VERSION "dbc-export 1 2026.26.6.5"

NS_ :

BS_:

BU_: ADSP APSB CMP DAS EPAS3P GTW OCS1P PTC RCM TCU TCU2 UDS UI UIS VCLEFT

BO_ 1297 RCM_alertLog: 8 RCM
 SG_ RCM_alertID M : 0|10@1+ (1,0) [0|1023] "" Vector__XXX
 SG_ RCM_a117_eventDriveOrientation m117 : 14|1@1+ (1,0) [0|1] "" Vector__XXX
 SG_ RCM_a117_imuZaccelChnlMonitTmp m117 : 16|1@1+ (1,0) [0|1] "" Vector__XXX
 SG_ RCM_a117_imuZaccelChnlMonitPerm m117 : 17|1@1+ (1,0) [0|1] "" Vector__XXX
 SG_ RCM_a117_eventIDFsignal m117 : 25|1@1+ (1,0) [0|1] "" Vector__XXX
 SG_ RCM_a117_eventFrontLeftSeatbelt m117 : 26|1@1+ (1,0) [0|1] "" Vector__XXX
 SG_ RCM_a117_eventFrontRightSeatbelt m117 : 27|1@1+ (1,0) [0|1] "" Vector__XXX
 SG_ RCM_a117_eventVehicleSpeed m117 : 28|12@1+ (0.08,-40) [-40|287.6] "kph" Vector__XXX
 SG_ RCM_a117_eventSteeringAngle m117 : 45|14@0+ (0.1,-819.2) [-819.2|819.1] "deg" Vector__XXX
 SG_ RCM_a117_eventDriverBrakeApply m117 : 46|2@1+ (1,0) [0|2] "" Vector__XXX
 SG_ RCM_a117_eventAccelPedalPos m117 : 56|8@1+ (0.4,0) [0|101.6] "%" Vector__XXX
 SG_ RCM_a118_eventArmStatus m118 : 11|1@1+ (1,0) [0|1] "" Vector__XXX
 SG_ RCM_a118_eventFactoryMode m118 : 12|1@1+ (1,0) [0|1] "" Vector__XXX
 SG_ RCM_a118_eventDiagEnabled m118 : 13|1@1+ (1,0) [0|1] "" Vector__XXX
 SG_ RCM_a118_eventDriveOrientation m118 : 14|1@1+ (1,0) [0|1] "" Vector__XXX
 SG_ RCM_a118_imuInPlaneSnsrMonitTmp m118 : 16|1@1+ (1,0) [0|1] "" Vector__XXX
 SG_ RCM_a118_imuInPlaneSnsrMonitPerm m118 : 17|1@1+ (1,0) [0|1] "" Vector__XXX
 SG_ RCM_a118_eventIDFsignal m118 : 25|1@1+ (1,0) [0|1] "" Vector__XXX
 SG_ RCM_a118_eventFrontLeftSeatbelt m118 : 26|1@1+ (1,0) [0|1] "" Vector__XXX
 SG_ RCM_a118_eventFrontRightSeatbelt m118 : 27|1@1+ (1,0) [0|1] "" Vector__XXX
 SG_ RCM_a118_eventVehicleSpeed m118 : 28|12@1+ (0.08,-40) [-40|287.6] "kph" Vector__XXX
 SG_ RCM_a118_eventSteeringAngle m118 : 45|14@0+ (0.1,-819.2) [-819.2|819.1] "deg" Vector__XXX
 SG_ RCM_a118_eventDriverBrakeApply m118 : 46|2@1+ (1,0) [0|2] "" Vector__XXX
 SG_ RCM_a118_eventAccelPedalPos m118 : 56|8@1+ (0.4,0) [0|101.6] "%" Vector__XXX

BO_ 881 RCM_alertMatrix: 8 RCM
 SG_ RCM_matrixIndex M : 0|4@1+ (1,0) [0|15] "" Vector__XXX
 SG_ RCM_a000_crashDetected m0 : 4|1@1+ (1,0) [0|1] "" Vector__XXX
 SG_ RCM_a001_nearDeploy m0 : 5|1@1+ (1,0) [0|1] "" Vector__XXX
 SG_ RCM_a002_airbagsNotArmed m0 : 6|1@1+ (1,0) [0|1] "" Vector__XXX
 SG_ RCM_a003_warningIndicator m0 : 7|1@1+ (1,0) [0|1] "" Vector__XXX
 SG_ RCM_a004_internalFault m0 : 8|1@1+ (1,0) [0|1] "" Vector__XXX
 SG_ RCM_a005_crcError m0 : 9|1@1+ (1,0) [0|1] "" Vector__XXX
 SG_ RCM_a006_batteryVoltageRange m0 : 10|1@1+ (1,0) [0|1] "" Vector__XXX
 SG_ RCM_a007_powerSupplyExternal m0 : 11|1@1+ (1,0) [0|1] "" Vector__XXX
 SG_ RCM_a008_powerSupplyInternal m0 : 12|1@1+ (1,0) [0|1] "" Vector__XXX
 SG_ RCM_a009_reprogramLimit m0 : 13|1@1+ (1,0) [0|1] "" Vector__XXX
 SG_ RCM_a010_scmDisabled m0 : 14|1@1+ (1,0) [0|1] "" Vector__XXX
 SG_ RCM_a011_eepromDataLocked m0 : 15|1@1+ (1,0) [0|1] "" Vector__XXX
 SG_ RCM_a012_vinStorage m0 : 16|1@1+ (1,0) [0|1] "" Vector__XXX
 SG_ RCM_a013_driverOrientation m0 : 17|1@1+ (1,0) [0|1] "" Vector__XXX
 SG_ RCM_a014_driverABStage1 m0 : 18|1@1+ (1,0) [0|1] "" Vector__XXX
 SG_ RCM_a015_driverABStage2 m0 : 19|1@1+ (1,0) [0|1] "" Vector__XXX
 SG_ RCM_a016_passABStage1 m0 : 20|1@1+ (1,0) [0|1] "" Vector__XXX
 SG_ RCM_a017_passABStage2 m0 : 21|1@1+ (1,0) [0|1] "" Vector__XXX
 SG_ RCM_a018_passengerActiveVent m0 : 22|1@1+ (1,0) [0|1] "" Vector__XXX
 SG_ RCM_a019_pretenShldrFrontLeft m0 : 23|1@1+ (1,0) [0|1] "" Vector__XXX
 SG_ RCM_a020_pretenShldFrontRight m0 : 24|1@1+ (1,0) [0|1] "" Vector__XXX
 SG_ RCM_a021_pretenLapFrontLeft m0 : 25|1@1+ (1,0) [0|1] "" Vector__XXX
 SG_ RCM_a022_pretenLapFrontRight m0 : 26|1@1+ (1,0) [0|1] "" Vector__XXX
 SG_ RCM_a023_loadLimiterLeftSide m0 : 27|1@1+ (1,0) [0|1] "" Vector__XXX
 SG_ RCM_a024_loadLimiterRightSide m0 : 28|1@1+ (1,0) [0|1] "" Vector__XXX
 SG_ RCM_a025_kneeABDriver m0 : 29|1@1+ (1,0) [0|1] "" Vector__XXX
 SG_ RCM_a026_kneeABFrontPassenger m0 : 30|1@1+ (1,0) [0|1] "" Vector__XXX
 SG_ RCM_a027_sideAB1stRowLeft m0 : 31|1@1+ (1,0) [0|1] "" Vector__XXX
 SG_ RCM_a028_sideAB1stRowRight m0 : 32|1@1+ (1,0) [0|1] "" Vector__XXX
 SG_ RCM_a029_driverABActiveVent m0 : 33|1@1+ (1,0) [0|1] "" Vector__XXX
 SG_ RCM_a030_farSideInboardAirbag m0 : 34|1@1+ (1,0) [0|1] "" Vector__XXX
 SG_ RCM_a031_frontCenterAirbag m0 : 35|1@1+ (1,0) [0|1] "" Vector__XXX
 SG_ RCM_a032_curtainABLeft m0 : 36|1@1+ (1,0) [0|1] "" Vector__XXX
 SG_ RCM_a033_curtainABRight m0 : 37|1@1+ (1,0) [0|1] "" Vector__XXX
 SG_ RCM_a034_preten2ndRowLeft m0 : 38|1@1+ (1,0) [0|1] "" Vector__XXX
 SG_ RCM_a035_preten2ndRowRight m0 : 39|1@1+ (1,0) [0|1] "" Vector__XXX
 SG_ RCM_a036_curAB2ndRowLeft m0 : 40|1@1+ (1,0) [0|1] "" Vector__XXX
 SG_ RCM_a037_curAB2ndRowRight m0 : 41|1@1+ (1,0) [0|1] "" Vector__XXX
 SG_ RCM_a038_unusedA m0 : 42|1@1+ (1,0) [0|1] "" Vector__XXX
 SG_ RCM_a039_unusedB m0 : 43|1@1+ (1,0) [0|1] "" Vector__XXX
 SG_ RCM_a040_hoodActuatorRight m0 : 44|1@1+ (1,0) [0|1] "" Vector__XXX
 SG_ RCM_a041_hoodActuatorLeft m0 : 45|1@1+ (1,0) [0|1] "" Vector__XXX
 SG_ RCM_a042_ens1Line m0 : 46|1@1+ (1,0) [0|1] "" Vector__XXX
 SG_ RCM_a043_ens2Line m0 : 47|1@1+ (1,0) [0|1] "" Vector__XXX
 SG_ RCM_a044_upFrontSensorLeft m0 : 48|1@1+ (1,0) [0|1] "" Vector__XXX
 SG_ RCM_a045_upFrontSensorRight m0 : 49|1@1+ (1,0) [0|1] "" Vector__XXX
 SG_ RCM_a046_sideAccelBPillarLeft m0 : 50|1@1+ (1,0) [0|1] "" Vector__XXX
 SG_ RCM_a047_sideAccelBPillarRight m0 : 51|1@1+ (1,0) [0|1] "" Vector__XXX
 SG_ RCM_a048_sideAccelCPillarLeft m0 : 52|1@1+ (1,0) [0|1] "" Vector__XXX
 SG_ RCM_a049_sideAccelCPillarRight m0 : 53|1@1+ (1,0) [0|1] "" Vector__XXX
 SG_ RCM_a050_upFrontSensorCenter m0 : 54|1@1+ (1,0) [0|1] "" Vector__XXX
 SG_ RCM_a051_pressureFrontLftDoor m0 : 55|1@1+ (1,0) [0|1] "" Vector__XXX
 SG_ RCM_a052_pressureFrontRtDoor m0 : 56|1@1+ (1,0) [0|1] "" Vector__XXX
 SG_ RCM_a053_pressurePedProLeft m0 : 57|1@1+ (1,0) [0|1] "" Vector__XXX
 SG_ RCM_a054_pressurePedProRight m0 : 58|1@1+ (1,0) [0|1] "" Vector__XXX
 SG_ RCM_a055_inertialMeasurement m0 : 59|1@1+ (1,0) [0|1] "" Vector__XXX
 SG_ RCM_a056_passengerFrontOCS m0 : 60|1@1+ (1,0) [0|1] "" Vector__XXX
 SG_ RCM_a057_driverOCS m0 : 61|1@1+ (1,0) [0|1] "" Vector__XXX
 SG_ RCM_a058_buckle1stRowLeft m0 : 62|1@1+ (1,0) [0|1] "" Vector__XXX
 SG_ RCM_a059_buckle1stRowRight m0 : 63|1@1+ (1,0) [0|1] "" Vector__XXX
 SG_ RCM_a060_stpsLeft m1 : 4|1@1+ (1,0) [0|1] "" Vector__XXX
 SG_ RCM_a061_stpsRight m1 : 5|1@1+ (1,0) [0|1] "" Vector__XXX
 SG_ RCM_a062_alrSwitch m1 : 6|1@1+ (1,0) [0|1] "" Vector__XXX
 SG_ RCM_a063_sbsw2ndRowRight m1 : 7|1@1+ (1,0) [0|1] "" Vector__XXX
 SG_ RCM_a064_hardwareCodingPin1 m1 : 8|1@1+ (1,0) [0|1] "" Vector__XXX
 SG_ RCM_a065_driverOrientConfigPin m1 : 9|1@1+ (1,0) [0|1] "" Vector__XXX
 SG_ RCM_a066_seatBackSw2ndRowLeft m1 : 10|1@1+ (1,0) [0|1] "" Vector__XXX
 SG_ RCM_a067_comCANInitFailure m1 : 11|1@1+ (1,0) [0|1] "" Vector__XXX
 SG_ RCM_a068_comChassisBusOff m1 : 12|1@1+ (1,0) [0|1] "" Vector__XXX
 SG_ RCM_a069_comCHCANPH7 m1 : 13|1@1+ (1,0) [0|1] "" Vector__XXX
 SG_ RCM_a070_comCHCANPH8 m1 : 14|1@1+ (1,0) [0|1] "" Vector__XXX
 SG_ RCM_a071_comCHCANPH9 m1 : 15|1@1+ (1,0) [0|1] "" Vector__XXX
 SG_ RCM_a072_comUnused m1 : 16|1@1+ (1,0) [0|1] "" Vector__XXX
 SG_ RCM_a073_comCHCANPH4 m1 : 17|1@1+ (1,0) [0|1] "" Vector__XXX
 SG_ RCM_a074_comCHCANPH5 m1 : 18|1@1+ (1,0) [0|1] "" Vector__XXX
 SG_ RCM_a075_comCHCANPH6 m1 : 19|1@1+ (1,0) [0|1] "" Vector__XXX
 SG_ RCM_a076_comEPBLStatus m1 : 20|1@1+ (1,0) [0|1] "" Vector__XXX
 SG_ RCM_a077_comEPBRStatus m1 : 21|1@1+ (1,0) [0|1] "" Vector__XXX
 SG_ RCM_a078_comOCS1PStatus m1 : 22|1@1+ (1,0) [0|1] "" Vector__XXX
 SG_ RCM_a079_comOCS1DStatus m1 : 23|1@1+ (1,0) [0|1] "" Vector__XXX
 SG_ RCM_a080_comGTWACS m1 : 24|1@1+ (1,0) [0|1] "" Vector__XXX
 SG_ RCM_a081_comVCFRONTLVPwr m1 : 25|1@1+ (1,0) [0|1] "" Vector__XXX
 SG_ RCM_a082_comUIodo m1 : 26|1@1+ (1,0) [0|1] "" Vector__XXX
 SG_ RCM_a083_comGTWCarState m1 : 27|1@1+ (1,0) [0|1] "" Vector__XXX
 SG_ RCM_a084_comTPMSStatus m1 : 28|1@1+ (1,0) [0|1] "" Vector__XXX
 SG_ RCM_a085_comGTWCarConfig m1 : 29|1@1+ (1,0) [0|1] "" Vector__XXX
 SG_ RCM_a086_comVINMIA m1 : 30|1@1+ (1,0) [0|1] "" Vector__XXX
 SG_ RCM_a087_comCANSilent m1 : 31|1@1+ (1,0) [0|1] "" Vector__XXX
 SG_ RCM_a088_comCHCANPH2 m1 : 32|1@1+ (1,0) [0|1] "" Vector__XXX
 SG_ RCM_a089_comCHCANPH3 m1 : 33|1@1+ (1,0) [0|1] "" Vector__XXX
 SG_ RCM_a090_comPartyBusOff m1 : 34|1@1+ (1,0) [0|1] "" Vector__XXX
 SG_ RCM_a091_comEPAS3PsysStatus m1 : 35|1@1+ (1,0) [0|1] "" Vector__XXX
 SG_ RCM_a092_comDASISF m1 : 36|1@1+ (1,0) [0|1] "" Vector__XXX
 SG_ RCM_a093_comVCLEFTStatus m1 : 37|1@1+ (1,0) [0|1] "" Vector__XXX
 SG_ RCM_a094_comVCRIGHTStatus m1 : 38|1@1+ (1,0) [0|1] "" Vector__XXX
 SG_ RCM_a095_comESPstatus m1 : 39|1@1+ (1,0) [0|1] "" Vector__XXX
 SG_ RCM_a096_comESPwheelSpeeds m1 : 40|1@1+ (1,0) [0|1] "" Vector__XXX
 SG_ RCM_a097_comDIspeed m1 : 41|1@1+ (1,0) [0|1] "" Vector__XXX
 SG_ RCM_a098_comDIchassisControl m1 : 42|1@1+ (1,0) [0|1] "" Vector__XXX
 SG_ RCM_a099_comDItorque m1 : 43|1@1+ (1,0) [0|1] "" Vector__XXX
 SG_ RCM_a100_comDIsystemStatus m1 : 44|1@1+ (1,0) [0|1] "" Vector__XXX
 SG_ RCM_a101_idfSystem m1 : 45|1@1+ (1,0) [0|1] "" Vector__XXX
 SG_ RCM_a102_imuYawR8OffstCompLim m1 : 46|1@1+ (1,0) [0|1] "" Vector__XXX
 SG_ RCM_a103_imuPtchR8OffstCompLim m1 : 47|1@1+ (1,0) [0|1] "" Vector__XXX
 SG_ RCM_a104_imuRollR8OffstCompLim m1 : 48|1@1+ (1,0) [0|1] "" Vector__XXX
 SG_ RCM_a105_imuLongAccOffstCompLim m1 : 49|1@1+ (1,0) [0|1] "" Vector__XXX
 SG_ RCM_a106_imuLatAccOffstCompLim m1 : 50|1@1+ (1,0) [0|1] "" Vector__XXX
 SG_ RCM_a107_imuVertAccOffstCompLim m1 : 51|1@1+ (1,0) [0|1] "" Vector__XXX
 SG_ RCM_a108_crashAlgoWakeup m1 : 52|1@1+ (1,0) [0|1] "" Vector__XXX
 SG_ RCM_a109_abuseImmunity m1 : 53|1@1+ (1,0) [0|1] "" Vector__XXX
 SG_ RCM_a110_factoryMode m1 : 54|1@1+ (1,0) [0|1] "" Vector__XXX
 SG_ RCM_a111_diagnosticsEnabled m1 : 55|1@1+ (1,0) [0|1] "" Vector__XXX
 SG_ RCM_a112_imuYawRate m1 : 56|1@1+ (1,0) [0|1] "" Vector__XXX
 SG_ RCM_a113_imuPitchRate m1 : 57|1@1+ (1,0) [0|1] "" Vector__XXX
 SG_ RCM_a114_imuRollRate m1 : 58|1@1+ (1,0) [0|1] "" Vector__XXX
 SG_ RCM_a115_imuLinearAcceleration m1 : 59|1@1+ (1,0) [0|1] "" Vector__XXX
 SG_ RCM_a116_imuLateralAcceleration m1 : 60|1@1+ (1,0) [0|1] "" Vector__XXX
 SG_ RCM_a117_imuVerticalAcceleration m1 : 61|1@1+ (1,0) [0|1] "" Vector__XXX
 SG_ RCM_a118_imuInPlaneAcceleration m1 : 62|1@1+ (1,0) [0|1] "" Vector__XXX

BO_ 1415 TCU2_SleepConfig: 1 TCU2
 SG_ TCU2_tc10Version : 0|2@1+ (1,0) [1|3] "" Vector__XXX

BO_ 1413 TCU2_alertLog: 8 TCU2
 SG_ TCU2_alertID M : 0|5@1+ (1,0) [0|31] "" Vector__XXX
 SG_ TCU2_alertState : 15|1@1+ (1,0) [0|1] "" Vector__XXX
 SG_ TCU2_w001_FailCode m1 : 16|32@1+ (1,0) [0|4294967295] "" Vector__XXX
 SG_ TCU2_w002_RejCause m2 : 16|32@1+ (1,0) [0|4294967295] "" Vector__XXX
 SG_ TCU2_w003_CallFailCode m3 : 16|32@1+ (1,0) [0|4294967295] "" Vector__XXX
 SG_ TCU2_w004_MSDFailCode m4 : 16|32@1+ (1,0) [0|4294967295] "" Vector__XXX
 SG_ TCU2_w006_Count m6 : 16|32@1+ (1,0) [0|4294967295] "" Vector__XXX
 SG_ TCU2_w007_Count m7 : 16|32@1+ (1,0) [0|4294967295] "" Vector__XXX
 SG_ TCU2_w009_CrashCode m9 : 16|32@1+ (1,0) [0|4294967295] "" Vector__XXX
 SG_ TCU2_w012_DataRAT m12 : 16|4@1+ (1,0) [0|15] "" Vector__XXX
 SG_ TCU2_w012_RSRP m12 : 20|8@1- (1,0) [-128|127] "dBm" Vector__XXX
 SG_ TCU2_w012_RSRQ m12 : 28|7@1- (1,0) [-64|63] "dBm" Vector__XXX
 SG_ TCU2_w012_MNC m12 : 45|10@1+ (1,0) [0|1023] "" Vector__XXX
 SG_ TCU2_w012_AvgQueueUsage m12 : 55|7@1+ (1,0) [0|127] "%" Vector__XXX
 SG_ TCU2_w012_NSAAvailable m12 : 62|2@1+ (1,0) [0|3] "" Vector__XXX
 SG_ TCU2_w013_DataRAT m13 : 16|4@1+ (1,0) [0|15] "" Vector__XXX
 SG_ TCU2_w013_RSRP m13 : 20|8@1- (1,0) [-128|127] "dBm" Vector__XXX
 SG_ TCU2_w013_RSRQ m13 : 28|7@1- (1,0) [-64|63] "dBm" Vector__XXX
 SG_ TCU2_w013_MNC m13 : 45|10@1+ (1,0) [0|1023] "" Vector__XXX
 SG_ TCU2_w013_AvgQueueUsage m13 : 55|7@1+ (1,0) [0|127] "%" Vector__XXX
 SG_ TCU2_w013_NSAAvailable m13 : 62|2@1+ (1,0) [0|3] "" Vector__XXX
 SG_ TCU2_w014_Reason m14 : 16|32@1- (1,0) [-2147483648|2147483647] "" Vector__XXX

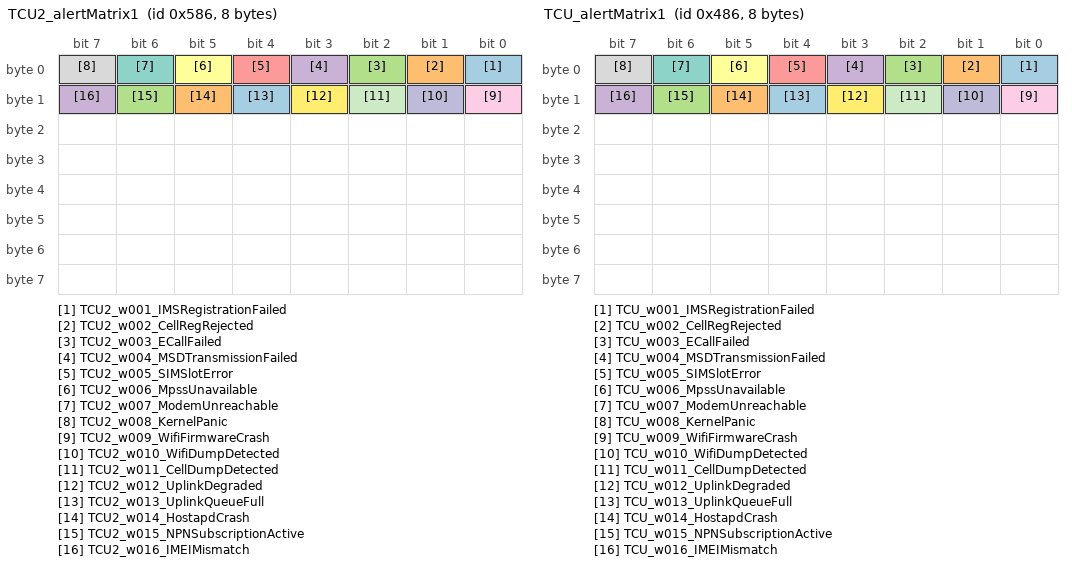
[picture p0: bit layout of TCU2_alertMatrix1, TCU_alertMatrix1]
BO_ 1414 TCU2_alertMatrix1: 8 TCU2
 SG_ TCU2_w001_IMSRegistrationFailed : 0|1@1+ (1,0) [0|1] "" Vector__XXX
 SG_ TCU2_w002_CellRegRejected : 1|1@1+ (1,0) [0|1] "" Vector__XXX
 SG_ TCU2_w003_ECallFailed : 2|1@1+ (1,0) [0|1] "" Vector__XXX
 SG_ TCU2_w004_MSDTransmissionFailed : 3|1@1+ (1,0) [0|1] "" Vector__XXX
 SG_ TCU2_w005_SIMSlotError : 4|1@1+ (1,0) [0|1] "" Vector__XXX
 SG_ TCU2_w006_MpssUnavailable : 5|1@1+ (1,0) [0|1] "" Vector__XXX
 SG_ TCU2_w007_ModemUnreachable : 6|1@1+ (1,0) [0|1] "" Vector__XXX
 SG_ TCU2_w008_KernelPanic : 7|1@1+ (1,0) [0|1] "" Vector__XXX
 SG_ TCU2_w009_WifiFirmwareCrash : 8|1@1+ (1,0) [0|1] "" Vector__XXX
 SG_ TCU2_w010_WifiDumpDetected : 9|1@1+ (1,0) [0|1] "" Vector__XXX
 SG_ TCU2_w011_CellDumpDetected : 10|1@1+ (1,0) [0|1] "" Vector__XXX
 SG_ TCU2_w012_UplinkDegraded : 11|1@1+ (1,0) [0|1] "" Vector__XXX
 SG_ TCU2_w013_UplinkQueueFull : 12|1@1+ (1,0) [0|1] "" Vector__XXX
 SG_ TCU2_w014_HostapdCrash : 13|1@1+ (1,0) [0|1] "" Vector__XXX
 SG_ TCU2_w015_NPNSubscriptionActive : 14|1@1+ (1,0) [0|1] "" Vector__XXX
 SG_ TCU2_w016_IMEIMismatch : 15|1@1+ (1,0) [0|1] "" Vector__XXX

BO_ 1412 TCU2_log: 8 TCU2
 SG_ TCU2_logMux M : 0|32@1+ (1,0) [0|4294967295] "" Vector__XXX
 SG_ TCU2_cpuTemp m0 : 32|32@1+ (1,0) [0|4294967295] "C" Vector__XXX
 SG_ TCU2_cpuUsage m1 : 32|32@1+ (1,0) [0|4294967295] "%" Vector__XXX
 SG_ TCU2_mdmCoreTemperature m2 : 32|32@1+ (1,0) [0|4294967295] "C" Vector__XXX
 SG_ TCU2_availableMemory m3 : 32|32@1+ (1,0) [0|4294967295] "KB" Vector__XXX
 SG_ TCU2_pwm m4 : 32|32@1+ (1,0) [0|4294967295] "" Vector__XXX
 SG_ TCU2_pwmcap m5 : 32|32@1+ (1,0) [0|4294967295] "" Vector__XXX
 SG_ TCU2_totalResumes m6 : 32|32@1+ (1,0) [0|4294967295] "" Vector__XXX
 SG_ TCU2_mdmUplinkQueueSize m7 : 32|32@1+ (1,0) [0|4294967295] "bytes" Vector__XXX
 SG_ TCU2_mdmRSRP m8 : 32|32@1- (1,0) [-2147483648|2147483647] "dBm" Vector__XXX
 SG_ TCU2_mdmSINR m9 : 32|32@1- (1,0) [-2147483648|2147483647] "dBm" Vector__XXX
 SG_ TCU2_mdmUplinkAllowedRate m10 : 32|32@1+ (1,0) [0|4294967295] "Kbps" Vector__XXX
 SG_ TCU2_mdmUplinkAvgRate m11 : 32|32@1+ (1,0) [0|4294967295] "Kbps" Vector__XXX
 SG_ TCU2_mdmServiceState m12 : 32|32@1+ (1,0) [0|4294967295] "" Vector__XXX
 SG_ TCU2_mdmIMSStatus m13 : 32|32@1+ (1,0) [0|4294967295] "" Vector__XXX
 SG_ TCU2_mdmSIMStatus m14 : 32|32@1+ (1,0) [0|4294967295] "" Vector__XXX
 SG_ TCU2_mdmBusyActive m15 : 32|32@1+ (1,0) [0|4294967294] "" Vector__XXX
 SG_ TCU2_modemUptime m16 : 32|32@1+ (1,0) [0|4294967295] "" Vector__XXX
 SG_ TCU2_mdmDataRat m17 : 32|3@1+ (1,0) [0|7] "" Vector__XXX
 SG_ TCU2_mdmDataCallStatus m18 : 32|3@1+ (1,0) [0|7] "" Vector__XXX
 SG_ TCU2_mdmNSAAvailable m19 : 32|2@1+ (1,0) [0|3] "" Vector__XXX
 SG_ TCU2_mdmPCIID m20 : 32|32@1+ (1,0) [0|4294967295] "" Vector__XXX
 SG_ TCU2_mdmMnc m21 : 32|32@1+ (1,0) [0|4294967295] "" Vector__XXX
 SG_ TCU2_mdmMcc m22 : 32|32@1+ (1,0) [0|4294967295] "" Vector__XXX
 SG_ TCU2_mdmTxKiloBytes m23 : 32|32@1+ (1,0) [0|4294967295] "KB" Vector__XXX
 SG_ TCU2_mdmDataCallTermReason m24 : 32|32@1+ (1,0) [0|4294967295] "" Vector__XXX
 SG_ TCU2_mdmDataCallTermCode m25 : 32|32@1+ (1,0) [0|4294967295] "" Vector__XXX
 SG_ TCU2_cellularSMState m26 : 32|32@1+ (1,0) [0|4294967295] "" Vector__XXX
 SG_ TCU2_tcuSMState m27 : 32|32@1+ (1,0) [0|4294967295] "" Vector__XXX
 SG_ TCU2_checkInternetFailCount m28 : 32|32@1+ (1,0) [0|4294967295] "" Vector__XXX
 SG_ TCU2_mdmBand m29 : 32|32@1+ (1,0) [0|4294967295] "" Vector__XXX
 SG_ TCU2_wakeSource m30 : 32|2@1+ (1,0) [0|3] "" Vector__XXX

BO_ 1159 TCU_SleepConfig: 1 TCU
 SG_ TCU_tc10Version : 0|2@1+ (1,0) [1|3] "" Vector__XXX

BO_ 1157 TCU_alertLog: 8 TCU
 SG_ TCU_alertID M : 0|5@1+ (1,0) [0|31] "" Vector__XXX
 SG_ TCU_alertState : 15|1@1+ (1,0) [0|1] "" Vector__XXX
 SG_ TCU_w001_FailCode m1 : 16|32@1+ (1,0) [0|4294967295] "" Vector__XXX
 SG_ TCU_w002_RejCause m2 : 16|32@1+ (1,0) [0|4294967295] "" Vector__XXX
 SG_ TCU_w003_CallFailCode m3 : 16|32@1+ (1,0) [0|4294967295] "" Vector__XXX
 SG_ TCU_w004_MSDFailCode m4 : 16|32@1+ (1,0) [0|4294967295] "" Vector__XXX
 SG_ TCU_w006_Count m6 : 16|32@1+ (1,0) [0|4294967295] "" Vector__XXX
 SG_ TCU_w007_Count m7 : 16|32@1+ (1,0) [0|4294967295] "" Vector__XXX
 SG_ TCU_w009_CrashCode m9 : 16|32@1+ (1,0) [0|4294967295] "" Vector__XXX
 SG_ TCU_w012_DataRAT m12 : 16|4@1+ (1,0) [0|15] "" Vector__XXX
 SG_ TCU_w012_RSRP m12 : 20|8@1- (1,0) [-128|127] "dBm" Vector__XXX
 SG_ TCU_w012_RSRQ m12 : 28|7@1- (1,0) [-64|63] "dBm" Vector__XXX
 SG_ TCU_w012_MNC m12 : 45|10@1+ (1,0) [0|1023] "" Vector__XXX
 SG_ TCU_w012_AvgQueueUsage m12 : 55|7@1+ (1,0) [0|127] "%" Vector__XXX
 SG_ TCU_w012_NSAAvailable m12 : 62|2@1+ (1,0) [0|3] "" Vector__XXX
 SG_ TCU_w013_DataRAT m13 : 16|4@1+ (1,0) [0|15] "" Vector__XXX
 SG_ TCU_w013_RSRP m13 : 20|8@1- (1,0) [-128|127] "dBm" Vector__XXX
 SG_ TCU_w013_RSRQ m13 : 28|7@1- (1,0) [-64|63] "dBm" Vector__XXX
 SG_ TCU_w013_MNC m13 : 45|10@1+ (1,0) [0|1023] "" Vector__XXX
 SG_ TCU_w013_AvgQueueUsage m13 : 55|7@1+ (1,0) [0|127] "%" Vector__XXX
 SG_ TCU_w013_NSAAvailable m13 : 62|2@1+ (1,0) [0|3] "" Vector__XXX
 SG_ TCU_w014_Reason m14 : 16|32@1- (1,0) [-2147483648|2147483647] "" Vector__XXX

BO_ 1158 TCU_alertMatrix1: 8 TCU
 SG_ TCU_w001_IMSRegistrationFailed : 0|1@1+ (1,0) [0|1] "" Vector__XXX
 SG_ TCU_w002_CellRegRejected : 1|1@1+ (1,0) [0|1] "" Vector__XXX
 SG_ TCU_w003_ECallFailed : 2|1@1+ (1,0) [0|1] "" Vector__XXX
 SG_ TCU_w004_MSDTransmissionFailed : 3|1@1+ (1,0) [0|1] "" Vector__XXX
 SG_ TCU_w005_SIMSlotError : 4|1@1+ (1,0) [0|1] "" Vector__XXX
 SG_ TCU_w006_MpssUnavailable : 5|1@1+ (1,0) [0|1] "" Vector__XXX
 SG_ TCU_w007_ModemUnreachable : 6|1@1+ (1,0) [0|1] "" Vector__XXX
 SG_ TCU_w008_KernelPanic : 7|1@1+ (1,0) [0|1] "" Vector__XXX
 SG_ TCU_w009_WifiFirmwareCrash : 8|1@1+ (1,0) [0|1] "" Vector__XXX
 SG_ TCU_w010_WifiDumpDetected : 9|1@1+ (1,0) [0|1] "" Vector__XXX
 SG_ TCU_w011_CellDumpDetected : 10|1@1+ (1,0) [0|1] "" Vector__XXX
 SG_ TCU_w012_UplinkDegraded : 11|1@1+ (1,0) [0|1] "" Vector__XXX
 SG_ TCU_w013_UplinkQueueFull : 12|1@1+ (1,0) [0|1] "" Vector__XXX
 SG_ TCU_w014_HostapdCrash : 13|1@1+ (1,0) [0|1] "" Vector__XXX
 SG_ TCU_w015_NPNSubscriptionActive : 14|1@1+ (1,0) [0|1] "" Vector__XXX
 SG_ TCU_w016_IMEIMismatch : 15|1@1+ (1,0) [0|1] "" Vector__XXX

BO_ 1155 TCU_log: 8 TCU
 SG_ TCU_logMux M : 0|32@1+ (1,0) [0|4294967295] "" Vector__XXX
 SG_ TCU_cpuTemp m0 : 32|32@1+ (1,0) [0|4294967295] "C" Vector__XXX
 SG_ TCU_cpuUsage m1 : 32|32@1+ (1,0) [0|4294967295] "%" Vector__XXX
 SG_ TCU_mdmCoreTemperature m2 : 32|32@1+ (1,0) [0|4294967295] "C" Vector__XXX
 SG_ TCU_availableMemory m3 : 32|32@1+ (1,0) [0|4294967295] "KB" Vector__XXX
 SG_ TCU_pwm m4 : 32|32@1+ (1,0) [0|4294967295] "" Vector__XXX
 SG_ TCU_pwmcap m5 : 32|32@1+ (1,0) [0|4294967295] "" Vector__XXX
 SG_ TCU_totalResumes m6 : 32|32@1+ (1,0) [0|4294967295] "" Vector__XXX
 SG_ TCU_mdmUplinkQueueSize m7 : 32|32@1+ (1,0) [0|4294967295] "bytes" Vector__XXX
 SG_ TCU_mdmRSRP m8 : 32|32@1- (1,0) [-2147483648|2147483647] "dBm" Vector__XXX
 SG_ TCU_mdmSINR m9 : 32|32@1- (1,0) [-2147483648|2147483647] "dBm" Vector__XXX
 SG_ TCU_mdmUplinkAllowedRate m10 : 32|32@1+ (1,0) [0|4294967295] "Kbps" Vector__XXX
 SG_ TCU_mdmUplinkAvgRate m11 : 32|32@1+ (1,0) [0|4294967295] "Kbps" Vector__XXX
 SG_ TCU_mdmServiceState m12 : 32|32@1+ (1,0) [0|4294967295] "" Vector__XXX
 SG_ TCU_mdmIMSStatus m13 : 32|32@1+ (1,0) [0|4294967295] "" Vector__XXX
 SG_ TCU_mdmSIMStatus m14 : 32|32@1+ (1,0) [0|4294967295] "" Vector__XXX
 SG_ TCU_mdmBusyActive m15 : 32|32@1+ (1,0) [0|4294967294] "" Vector__XXX
 SG_ TCU_modemUptime m16 : 32|32@1+ (1,0) [0|4294967295] "" Vector__XXX
 SG_ TCU_mdmDataRat m17 : 32|3@1+ (1,0) [0|7] "" Vector__XXX
 SG_ TCU_mdmDataCallStatus m18 : 32|3@1+ (1,0) [0|7] "" Vector__XXX
 SG_ TCU_mdmNSAAvailable m19 : 32|2@1+ (1,0) [0|3] "" Vector__XXX
 SG_ TCU_mdmPCIID m20 : 32|32@1+ (1,0) [0|4294967295] "" Vector__XXX
 SG_ TCU_mdmMnc m21 : 32|32@1+ (1,0) [0|4294967295] "" Vector__XXX
 SG_ TCU_mdmMcc m22 : 32|32@1+ (1,0) [0|4294967295] "" Vector__XXX
 SG_ TCU_mdmTxKiloBytes m23 : 32|32@1+ (1,0) [0|4294967295] "KB" Vector__XXX
 SG_ TCU_mdmDataCallTermReason m24 : 32|32@1+ (1,0) [0|4294967295] "" Vector__XXX
 SG_ TCU_mdmDataCallTermCode m25 : 32|32@1+ (1,0) [0|4294967295] "" Vector__XXX
 SG_ TCU_cellularSMState m26 : 32|32@1+ (1,0) [0|4294967295] "" Vector__XXX
 SG_ TCU_tcuSMState m27 : 32|32@1+ (1,0) [0|4294967295] "" Vector__XXX
 SG_ TCU_checkInternetFailCount m28 : 32|32@1+ (1,0) [0|4294967295] "" Vector__XXX
 SG_ TCU_mdmBand m29 : 32|32@1+ (1,0) [0|4294967295] "" Vector__XXX
 SG_ TCU_wakeSource m30 : 32|2@1+ (1,0) [0|3] "" Vector__XXX

BO_ 1603 UDS_ocs1pRequest: 8 UDS
 SG_ UDS_ocs1pRequestData : 7|64@0+ (1,0) [0|1.84467440737e+19] "" Vector__XXX

BO_ 1551 UDS_thcRequest: 8 UDS
 SG_ UDS_thcRequestData_H : 7|32@0+ (1,0) [0|4294967295] "" Vector__XXX
 SG_ UDS_thcRequestData_L : 39|32@0+ (1,0) [0|4294967295] "" Vector__XXX

BO_ 1056 UIS_log: 8 UIS
 SG_ UIS_logMux M : 0|32@1+ (1,0) [0|4294967295] "" Vector__XXX
 SG_ UIS_zramWriteTicks m0 : 32|32@1+ (1,0) [0|4294967295] "" Vector__XXX
 SG_ UIS_zramWriteIO m1 : 32|32@1+ (1,0) [0|4294967295] "" Vector__XXX
 SG_ UIS_zramReadTicks m2 : 32|32@1+ (1,0) [0|4294967295] "" Vector__XXX
 SG_ UIS_zramReadIO m3 : 32|32@1+ (1,0) [0|4294967295] "" Vector__XXX
 SG_ UIS_zramOriginalSize m4 : 32|32@1+ (1,0) [0|4294967295] "" Vector__XXX
 SG_ UIS_zramNotifyFree m5 : 32|32@1+ (1,0) [0|4294967295] "" Vector__XXX
 SG_ UIS_zramInvalidIO m6 : 32|32@1+ (1,0) [0|4294967295] "" Vector__XXX
 SG_ UIS_zramFailedWrites m7 : 32|32@1+ (1,0) [0|4294967295] "" Vector__XXX
 SG_ UIS_zramFailedReads m8 : 32|32@1+ (1,0) [0|4294967295] "" Vector__XXX
 SG_ UIS_zramCompressionRatio m9 : 32|32@1+ (1,0) [0|4294967295] "" Vector__XXX
 SG_ UIS_zramCompressedSize m10 : 32|32@1+ (1,0) [0|4294967295] "" Vector__XXX
 SG_ UIS_wifiTemperature m11 : 32|32@1+ (1,0) [0|4294967295] "" Vector__XXX
 SG_ UIS_wifiStackState m12 : 32|32@1+ (1,0) [0|4294967295] "" Vector__XXX
 SG_ UIS_wifiStackReady m13 : 32|32@1+ (1,0) [0|4294967295] "" Vector__XXX
 SG_ UIS_wifiBars m14 : 32|32@1+ (1,0) [0|4294967295] "" Vector__XXX
 SG_ UIS_wifiAutoJoinLowRSSI m15 : 32|32@1+ (1,0) [0|1] "" Vector__XXX
 SG_ UIS_webbrowserMemUsage m16 : 32|32@1+ (1,0) [0|4294967295] "" Vector__XXX
 SG_ UIS_webbrowserCPUUsage m17 : 32|32@1+ (1,0) [0|4294967295] "" Vector__XXX
 SG_ UIS_vmtouchMemUsage m18 : 32|32@1+ (1,0) [0|4294967295] "" Vector__XXX
 SG_ UIS_vmtouchCPUUsage m19 : 32|32@1+ (1,0) [0|4294967295] "" Vector__XXX
 SG_ UIS_videodMemUsage m20 : 32|32@1+ (1,0) [0|4294967295] "" Vector__XXX
 SG_ UIS_videodCPUUsage m21 : 32|32@1+ (1,0) [0|4294967295] "" Vector__XXX
 SG_ UIS_vehicleMemUsage m22 : 32|32@1+ (1,0) [0|4294967295] "" Vector__XXX
 SG_ UIS_vehicleCPUUsage m23 : 32|32@1+ (1,0) [0|4294967295] "" Vector__XXX
 SG_ UIS_valhallaserverMemUsage m24 : 32|32@1+ (1,0) [0|4294967295] "" Vector__XXX
 SG_ UIS_valhallaserverCPUUsage m25 : 32|32@1+ (1,0) [0|4294967295] "" Vector__XXX
 SG_ UIS_valetMode m26 : 32|32@1+ (1,0) [0|1] "" Vector__XXX
 SG_ UIS_uiQtCarUptime m27 : 32|32@1+ (1,0) [0|4294967295] "" Vector__XXX
 SG_ UIS_uiQtCarSwapUsage m28 : 32|32@1+ (1,0) [0|4294967295] "" Vector__XXX
 SG_ UIS_uiMeanFPS m29 : 32|32@1+ (1,0) [0|4294967295] "" Vector__XXX
 SG_ UIS_uiMaxFrametime m30 : 32|32@1+ (1,0) [0|4294967295] "" Vector__XXX
 SG_ UIS_uiFrametimeGearShiftPToR m31 : 32|32@1+ (1,0) [0|4294967295] "" Vector__XXX
 SG_ UIS_uiFrametimeGearShiftDToR m32 : 32|32@1+ (1,0) [0|4294967295] "" Vector__XXX
 SG_ UIS_uiFramesOver200Ms m33 : 32|32@1+ (1,0) [0|4294967295] "" Vector__XXX
 SG_ UIS_uiFramesOver100Ms m34 : 32|32@1+ (1,0) [0|4294967295] "" Vector__XXX
 SG_ UIS_tunerVoltageUBatt m35 : 32|32@1+ (1,0) [0|4294967295] "" Vector__XXX
 SG_ UIS_tunerVoltageOperation m36 : 32|32@1+ (1,0) [0|4294967295] "" Vector__XXX
 SG_ UIS_tunerVoltageMQS m37 : 32|32@1+ (1,0) [0|4294967295] "" Vector__XXX
 SG_ UIS_tunerVoltageAntenna2 m38 : 32|32@1+ (1,0) [0|4294967295] "" Vector__XXX
 SG_ UIS_tunerVoltageAntenna1 m39 : 32|32@1+ (1,0) [0|4294967295] "" Vector__XXX
 SG_ UIS_tunerVoltage3V3 m40 : 32|32@1+ (1,0) [0|4294967295] "" Vector__XXX
 SG_ UIS_tunerVoltage1V8 m41 : 32|32@1+ (1,0) [0|4294967295] "" Vector__XXX
 SG_ UIS_tunerTemperatureFahrenheit m42 : 32|32@1+ (1,0) [0|4294967295] "" Vector__XXX
 SG_ UIS_tunerTemperatureCelsius m43 : 32|32@1+ (1,0) [0|4294967295] "" Vector__XXX
 SG_ UIS_tunerCurrentAntenna2 m44 : 32|32@1+ (1,0) [0|4294967295] "" Vector__XXX
 SG_ UIS_tunerCurrentAntenna1 m45 : 32|32@1+ (1,0) [0|4294967295] "" Vector__XXX
 SG_ UIS_touchEventsAggCount m46 : 32|32@1+ (1,0) [0|4294967295] "" Vector__XXX
 SG_ UIS_tmserverMemUsage m47 : 32|32@1+ (1,0) [0|4294967295] "" Vector__XXX
 SG_ UIS_tmserverCPUUsage m48 : 32|32@1+ (1,0) [0|4294967295] "" Vector__XXX
 SG_ UIS_thermalResistance m49 : 32|32@1+ (1,0) [0|4294967295] "C/W" Vector__XXX
 SG_ UIS_thermalProfile m50 : 32|32@1+ (1,0) [1|4294967295] "" Vector__XXX
 SG_ UIS_testDriveMode m51 : 32|32@1+ (1,0) [0|4294967295] "" Vector__XXX
 SG_ UIS_teslachromiumMemUsage m52 : 32|32@1+ (1,0) [0|4294967295] "" Vector__XXX
 SG_ UIS_teslachromiumCPUUsage m53 : 32|32@1+ (1,0) [0|4294967295] "" Vector__XXX
 SG_ UIS_teslaMediaCacheSize m54 : 32|32@1+ (1,0) [0|4294967295] "" Vector__XXX
 SG_ UIS_teslaMediaCacheCost m55 : 32|32@1+ (1,0) [0|4294967295] "" Vector__XXX
 SG_ UIS_teleopStreamXrunCount m56 : 32|32@1+ (1,0) [0|4294967295] "" Vector__XXX
 SG_ UIS_teleopPhoneCallActive m57 : 32|32@1+ (1,0) [0|4294967295] "" Vector__XXX
 SG_ UIS_teleopPacketDrops m58 : 32|32@1+ (1,0) [0|4294967295] "" Vector__XXX
 SG_ UIS_teleopMinPacketDelta m59 : 32|32@1+ (0.0001,0) [0|429496.7295] "ms" Vector__XXX
 SG_ UIS_teleopMaxPacketDelta m60 : 32|32@1+ (0.0001,0) [0|429496.7295] "ms" Vector__XXX
 SG_ UIS_teleopAvgPacketDelta m61 : 32|32@1+ (0.0001,0) [0|429496.7295] "ms" Vector__XXX
 SG_ UIS_tegraModemManState m62 : 32|32@1+ (1,0) [0|4294967295] "" Vector__XXX
 SG_ UIS_systemWakeTime m63 : 32|32@1+ (1,0) [0|4294967295] "" Vector__XXX
 SG_ UIS_systemUptime m64 : 32|32@1+ (1,0) [0|4294967295] "" Vector__XXX
 SG_ UIS_systemMemSwapUsage m65 : 32|32@1+ (1,0) [0|4294967295] "" Vector__XXX
 SG_ UIS_suspensionGeofence m66 : 32|32@1+ (1,0) [0|1] "" Vector__XXX
 SG_ UIS_superchargePaymentNeeded m67 : 32|32@1+ (1,0) [0|4294967295] "" Vector__XXX
 SG_ UIS_sudokuMemUsage m68 : 32|32@1+ (1,0) [0|4294967295] "" Vector__XXX
 SG_ UIS_sudokuCPUUsage m69 : 32|32@1+ (1,0) [0|4294967295] "" Vector__XXX
 SG_ UIS_spotifyserverMemUsage m70 : 32|32@1+ (1,0) [0|4294967295] "" Vector__XXX
 SG_ UIS_spotifyserverCPUUsage m71 : 32|32@1+ (1,0) [0|4294967295] "" Vector__XXX
 SG_ UIS_speechrecoMemUsage m72 : 32|32@1+ (1,0) [0|4294967295] "" Vector__XXX
 SG_ UIS_speechrecoCPUUsage m73 : 32|32@1+ (1,0) [0|4294967295] "" Vector__XXX
 SG_ UIS_solitaireMemUsage m74 : 32|32@1+ (1,0) [0|4294967295] "" Vector__XXX
 SG_ UIS_solitaireCPUUsage m75 : 32|32@1+ (1,0) [0|4294967295] "" Vector__XXX
 SG_ UIS_softwareUpdateState m76 : 32|32@1+ (1,0) [0|4294967295] "" Vector__XXX
 SG_ UIS_softwareUpdatePrimDownload m77 : 32|32@1+ (1,0) [0|4294967295] "" Vector__XXX
 SG_ UIS_softwareInstallPopupStatus m78 : 32|32@1+ (1,0) [0|4294967295] "" Vector__XXX
 SG_ UIS_sleepType m79 : 32|32@1+ (1,0) [0|4294967295] "" Vector__XXX
 SG_ UIS_sleepTime m80 : 32|32@1+ (1,0) [0|4294967295] "" Vector__XXX
 SG_ UIS_sleepState m81 : 32|32@1+ (1,0) [0|4294967295] "" Vector__XXX
 SG_ UIS_sleepCount m82 : 32|32@1+ (1,0) [0|4294967295] "" Vector__XXX
 SG_ UIS_slackerLoginResult m83 : 32|32@1+ (1,0) [0|4294967295] "" Vector__XXX
 SG_ UIS_settingsAutoTurnSignal m84 : 32|32@1+ (1,0) [0|4294967295] "" Vector__XXX
 SG_ UIS_serviceModePlus m85 : 32|32@1+ (1,0) [0|4294967295] "" Vector__XXX
 SG_ UIS_serviceMode m86 : 32|32@1+ (1,0) [0|4294967295] "" Vector__XXX
 SG_ UIS_serverMemUsage m87 : 32|32@1+ (1,0) [0|4294967295] "" Vector__XXX
 SG_ UIS_serverCPUUsage m88 : 32|32@1+ (1,0) [0|4294967295] "" Vector__XXX
 SG_ UIS_sentryState m89 : 32|32@1+ (1,0) [0|4294967295] "" Vector__XXX
 SG_ UIS_sentryNeedsNap m90 : 32|32@1+ (1,0) [0|4294967295] "" Vector__XXX
 SG_ UIS_sentryIncidentCount m91 : 32|32@1+ (1,0) [0|4294967295] "" Vector__XXX
 SG_ UIS_scheduledChargingMode m92 : 32|32@1+ (1,0) [0|4294967295] "" Vector__XXX
 SG_ UIS_scheduleChargeStartTime m93 : 32|32@1+ (1,0) [0|4294967295] "" Vector__XXX
 SG_ UIS_scheduleChargeEndTime m94 : 32|32@1+ (1,0) [0|4294967295] "" Vector__XXX
 SG_ UIS_robotaxiModeActive m95 : 32|32@1+ (1,0) [0|4294967295] "" Vector__XXX
 SG_ UIS_remoteRequestType m96 : 32|32@1+ (1,0) [0|4294967295] "" Vector__XXX
 SG_ UIS_releasenotesMemUsage m97 : 32|32@1+ (1,0) [0|4294967295] "" Vector__XXX
 SG_ UIS_releasenotesCPUUsage m98 : 32|32@1+ (1,0) [0|4294967295] "" Vector__XXX
 SG_ UIS_rearDisplayUserPresent m99 : 32|32@1+ (1,0) [0|1] "" Vector__XXX
 SG_ UIS_rearDisplayState m100 : 32|32@1+ (1,0) [0|4294967295] "" Vector__XXX
 SG_ UIS_radioserveMemUsage m101 : 32|32@1+ (1,0) [0|4294967295] "" Vector__XXX
 SG_ UIS_radioserveCPUUsage m102 : 32|32@1+ (1,0) [0|4294967295] "" Vector__XXX
 SG_ UIS_qtcarMemUsage m103 : 32|32@1+ (1,0) [0|4294967295] "" Vector__XXX
 SG_ UIS_qtcarCPUUsage m104 : 32|32@1+ (1,0) [0|4294967295] "" Vector__XXX
 SG_ UIS_psiMemSome m105 : 32|32@1+ (1,0) [0|4294967295] "" Vector__XXX
 SG_ UIS_psiMemFull m106 : 32|32@1+ (1,0) [0|4294967295] "" Vector__XXX
 SG_ UIS_psiIOSome m107 : 32|32@1+ (1,0) [0|4294967295] "" Vector__XXX
 SG_ UIS_psiIOFull m108 : 32|32@1+ (1,0) [0|4294967295] "" Vector__XXX
 SG_ UIS_psiCpuSome m109 : 32|32@1+ (1,0) [0|4294967295] "" Vector__XXX
 SG_ UIS_powerManagerState m110 : 32|5@1+ (1,0) [0|31] "" Vector__XXX
 SG_ UIS_polytopiax8664MemUsage m111 : 32|32@1+ (1,0) [0|4294967295] "" Vector__XXX
 SG_ UIS_polytopiax8664CPUUsage m112 : 32|32@1+ (1,0) [0|4294967295] "" Vector__XXX
 SG_ UIS_odinStatusCmdResult m113 : 32|32@1+ (1,0) [0|4294967295] "" Vector__XXX
 SG_ UIS_odinStatusCmdDurationMs m114 : 32|32@1+ (1,0) [0|4294967295] "" Vector__XXX
 SG_ UIS_odinProcessState m115 : 32|32@1+ (1,0) [0|4294967295] "" Vector__XXX
 SG_ UIS_odinPeriodicTaskState m116 : 32|32@1+ (1,0) [0|4294967295] "" Vector__XXX
 SG_ UIS_odinOrchestratorStartCount m117 : 32|32@1+ (1,0) [0|4294967295] "" Vector__XXX
 SG_ UIS_odinOrchestratorFailCount m118 : 32|32@1+ (1,0) [0|4294967295] "" Vector__XXX
 SG_ UIS_odinNetworkStartCount m119 : 32|32@1+ (1,0) [0|4294967295] "" Vector__XXX
 SG_ UIS_odinNetworkFailCount m120 : 32|32@1+ (1,0) [0|4294967295] "" Vector__XXX
 SG_ UIS_odinMemUsage m121 : 32|32@1+ (1,0) [0|4294967295] "" Vector__XXX
 SG_ UIS_odinListTasksCmdResult m122 : 32|32@1+ (1,0) [0|4294967295] "" Vector__XXX
 SG_ UIS_odinListTasksCmdDurationMs m123 : 32|32@1+ (1,0) [0|4294967295] "" Vector__XXX
 SG_ UIS_odinHrlUploadLimits m124 : 32|32@1+ (1,0) [0|4294967295] "" Vector__XXX
 SG_ UIS_odinHrlLogUploadState m125 : 32|32@1+ (1,0) [0|4294967295] "" Vector__XXX
 SG_ UIS_odinHermesConnectionState m126 : 32|32@1+ (1,0) [0|4294967295] "" Vector__XXX
 SG_ UIS_odinGatewayConnectionState m127 : 32|32@1+ (1,0) [0|4294967295] "" Vector__XXX
 SG_ UIS_odinFileSystemState m128 : 32|32@1+ (1,0) [0|4294967295] "" Vector__XXX
 SG_ UIS_odinEcuLogUploadState m129 : 32|32@1+ (1,0) [0|4294967295] "" Vector__XXX
 SG_ UIS_odinEcuLogForceTriggerUpload m130 : 32|32@1+ (1,0) [0|4294967295] "" Vector__XXX
 SG_ UIS_odinCPUUsage m131 : 32|32@1+ (1,0) [0|4294967295] "" Vector__XXX
 SG_ UIS_odinAuthFailCount m132 : 32|32@1+ (1,0) [0|4294967295] "" Vector__XXX
 SG_ UIS_odinAuthCount m133 : 32|32@1+ (1,0) [0|4294967295] "" Vector__XXX
 SG_ UIS_nvmeTemperature m134 : 32|32@1+ (1,0) [0|4294967295] "" Vector__XXX
 SG_ UIS_nvmePercentLifetimeUsed m135 : 32|32@1+ (1,0) [0|4294967295] "" Vector__XXX
 SG_ UIS_nvmeDataUnitsWritten100mb m136 : 32|32@1+ (1,0) [0|4294967295] "" Vector__XXX
 SG_ UIS_numUncorrMemErrorsECC m137 : 32|32@1+ (1,0) [0|4294967295] "" Vector__XXX
 SG_ UIS_numCorrMemErrorsECC m138 : 32|32@1+ (1,0) [0|4294967295] "" Vector__XXX
 SG_ UIS_nuanceserverMemUsage m139 : 32|32@1+ (1,0) [0|4294967295] "" Vector__XXX
 SG_ UIS_nuanceserverCPUUsage m140 : 32|32@1+ (1,0) [0|4294967295] "" Vector__XXX
 SG_ UIS_netWifiTxRate m141 : 32|32@1+ (0.001,0) [0|4294967.295] "Megabytes per second (MBps)" Vector__XXX
 SG_ UIS_netWifiTxCount m142 : 32|32@1+ (0.001,0) [0|4294967.295] "Megabytes" Vector__XXX
 SG_ UIS_netWifiRxRate m143 : 32|32@1+ (0.001,0) [0|4294967.295] "Megabytes per second (MBps)" Vector__XXX
 SG_ UIS_netWifiRxCount m144 : 32|32@1+ (0.001,0) [0|4294967.295] "Megabytes" Vector__XXX
 SG_ UIS_netEthTxRate m145 : 32|32@1+ (0.001,0) [0|4294967.295] "Megabytes per second (MBps)" Vector__XXX
 SG_ UIS_netEthTxCount m146 : 32|32@1+ (0.001,0) [0|4294967.295] "Megabytes" Vector__XXX
 SG_ UIS_netEthRxRate m147 : 32|32@1+ (0.001,0) [0|4294967.295] "Megabytes per second (MBps)" Vector__XXX
 SG_ UIS_netEthRxErrorRate m148 : 32|32@1+ (1,0) [0|4294967295] "" Vector__XXX
 SG_ UIS_netEthRxErrorCount m149 : 32|32@1+ (1,0) [0|4294967295] "" Vector__XXX
 SG_ UIS_netEthRxDroppedRate m150 : 32|32@1+ (1,0) [0|4294967295] "" Vector__XXX
 SG_ UIS_netEthRxDroppedCount m151 : 32|32@1+ (1,0) [0|4294967295] "" Vector__XXX
 SG_ UIS_netEthRxCount m152 : 32|32@1+ (0.001,0) [0|4294967.295] "Megabytes" Vector__XXX
 SG_ UIS_netCellTxRate m153 : 32|32@1+ (0.001,0) [0|4294967.295] "Megabytes per second (MBps)" Vector__XXX
 SG_ UIS_netCellTxCount m154 : 32|32@1+ (0.001,0) [0|4294967.295] "Megabytes" Vector__XXX
 SG_ UIS_netCellRxRate m155 : 32|32@1+ (0.001,0) [0|4294967.295] "Megabytes per second (MBps)" Vector__XXX
 SG_ UIS_netCellRxCount m156 : 32|32@1+ (0.001,0) [0|4294967.295] "Megabytes" Vector__XXX
 SG_ UIS_navServiceError m157 : 32|32@1+ (1,0) [0|4294967295] "" Vector__XXX
 SG_ UIS_navAudioVolume m158 : 32|32@1+ (1,0) [0|4294967295] "" Vector__XXX
 SG_ UIS_muteNavVolume m159 : 32|32@1+ (1,0) [0|4294967295] "" Vector__XXX
 SG_ UIS_mounterdState m160 : 32|32@1+ (1,0) [0|4294967295] "" Vector__XXX
 SG_ UIS_mounterdMountCountTotal m161 : 32|32@1+ (1,0) [0|4294967295] "" Vector__XXX
 SG_ UIS_mounterdFrontHubDisconnected m162 : 32|32@1+ (1,0) [0|4294967295] "" Vector__XXX
 SG_ UIS_mounterdFrontHubConnected m163 : 32|32@1+ (1,0) [0|4294967295] "" Vector__XXX
 SG_ UIS_mounterdFilesystemCountFat32 m164 : 32|32@1+ (1,0) [0|4294967295] "" Vector__XXX
 SG_ UIS_mounterdFilesystemCountExt4 m165 : 32|32@1+ (1,0) [0|4294967295] "" Vector__XXX
 SG_ UIS_mounterdFilesystemCountExt3 m166 : 32|32@1+ (1,0) [0|4294967295] "" Vector__XXX
 SG_ UIS_mounterdFilesystemCountExfat m167 : 32|32@1+ (1,0) [0|4294967295] "" Vector__XXX
 SG_ UIS_mounterdEncryptionCapacityGB m168 : 32|32@1+ (1,0) [0|4294967295] "" Vector__XXX
 SG_ UIS_mounterdDeviceCount m169 : 32|32@1+ (1,0) [0|4294967295] "" Vector__XXX
 SG_ UIS_mounterdDashcamCapacityGB m170 : 32|32@1+ (1,0) [0|4294967295] "" Vector__XXX
 SG_ UIS_modemECallppAvail m171 : 32|32@1+ (1,0) [0|1] "" Vector__XXX
 SG_ UIS_modemBusyActive m172 : 32|32@1+ (1,0) [0|1] "" Vector__XXX
 SG_ UIS_mirrorGeofenceActive m173 : 32|32@1+ (1,0) [0|1] "" Vector__XXX
 SG_ UIS_mediaserveMemUsage m174 : 32|32@1+ (1,0) [0|4294967295] "" Vector__XXX
 SG_ UIS_mediaserveCPUUsage m175 : 32|32@1+ (1,0) [0|4294967295] "" Vector__XXX
 SG_ UIS_mediaPlaybackStatus m176 : 32|32@1+ (1,0) [0|4294967295] "" Vector__XXX
 SG_ UIS_mediaNeedAuthToken m177 : 32|32@1+ (1,0) [0|1] "" Vector__XXX
 SG_ UIS_mediaImageCacheSize m178 : 32|32@1+ (1,0) [0|4294967295] "" Vector__XXX
 SG_ UIS_mediaImageCacheCost m179 : 32|32@1+ (1,0) [0|4294967295] "" Vector__XXX
 SG_ UIS_limex8664MemUsage m180 : 32|32@1+ (1,0) [0|4294967295] "" Vector__XXX
 SG_ UIS_limex8664CPUUsage m181 : 32|32@1+ (1,0) [0|4294967295] "" Vector__XXX
 SG_ UIS_inSuperchargerGeofence m182 : 32|32@1+ (1,0) [0|1] "" Vector__XXX
 SG_ UIS_igpuTemperature m183 : 32|32@1+ (1,0) [0|4294967295] "" Vector__XXX
 SG_ UIS_homelinkState m184 : 32|32@1+ (1,0) [0|4294967295] "" Vector__XXX
 SG_ UIS_hicarServiceState m185 : 32|32@1+ (1,0) [0|4294967295] "" Vector__XXX
 SG_ UIS_hicarEventCode m186 : 32|32@1+ (1,0) [0|4294967295] "" Vector__XXX
 SG_ UIS_hicarErrorCode m187 : 32|32@1+ (1,0) [0|4294967295] "" Vector__XXX
 SG_ UIS_hicarDataReceiveType m188 : 32|32@1+ (1,0) [0|4294967295] "" Vector__XXX
 SG_ UIS_hicarConnectionState m189 : 32|32@1+ (1,0) [0|4294967295] "" Vector__XXX
 SG_ UIS_hicarCallState m190 : 32|32@1+ (1,0) [0|4294967295] "" Vector__XXX
 SG_ UIS_hicarAudioTeardownState m191 : 32|32@1+ (1,0) [0|4294967295] "" Vector__XXX
 SG_ UIS_hicarAudioSetupState m192 : 32|32@1+ (1,0) [0|4294967295] "" Vector__XXX
 SG_ UIS_hermesdynamicMemUsage m193 : 32|32@1+ (1,0) [0|4294967295] "" Vector__XXX
 SG_ UIS_hermesdynamicCPUUsage m194 : 32|32@1+ (1,0) [0|4294967295] "" Vector__XXX
 SG_ UIS_hermesclientMemUsage m195 : 32|32@1+ (1,0) [0|4294967295] "" Vector__XXX
 SG_ UIS_hermesclientCPUUsage m196 : 32|32@1+ (1,0) [0|4294967295] "" Vector__XXX
 SG_ UIS_headsetPairResult m197 : 32|32@1+ (1,0) [0|4294967295] "" Vector__XXX
 SG_ UIS_headsetConnectionState m198 : 32|32@1+ (1,0) [0|4294967295] "" Vector__XXX
 SG_ UIS_gtwSocUartTxStatTimeouts m199 : 32|32@1+ (1,0) [0|4294967295] "" Vector__XXX
 SG_ UIS_gtwSocUartTxStatPackets m200 : 32|32@1+ (1,0) [0|4294967295] "" Vector__XXX
 SG_ UIS_gtwSocUartTxStatNacks m201 : 32|32@1+ (1,0) [0|4294967295] "" Vector__XXX
 SG_ UIS_gtwSocUartTxStatBadTooBig m202 : 32|32@1+ (1,0) [0|4294967295] "" Vector__XXX
 SG_ UIS_gtwSocUartTxStatAnsMismatch m203 : 32|32@1+ (1,0) [0|4294967295] "" Vector__XXX
 SG_ UIS_gtwSocUartRxStatValidPackets m204 : 32|32@1+ (1,0) [0|4294967295] "" Vector__XXX
 SG_ UIS_gtwSocUartRxStatUnhandled m205 : 32|32@1+ (1,0) [0|4294967295] "" Vector__XXX
 SG_ UIS_gtwSocUartRxStatMsgErr m206 : 32|32@1+ (1,0) [0|4294967295] "" Vector__XXX
 SG_ UIS_gtwSocUartRxStatHeartbeats m207 : 32|32@1+ (1,0) [0|4294967295] "" Vector__XXX
 SG_ UIS_gtwSocUartRxStatHandleErr m208 : 32|32@1+ (1,0) [0|4294967295] "" Vector__XXX
 SG_ UIS_gtwSocUartRxStatBadTooSmall m209 : 32|32@1+ (1,0) [0|4294967295] "" Vector__XXX
 SG_ UIS_gtwSocUartRxStatBadTooBig m210 : 32|32@1+ (1,0) [0|4294967295] "" Vector__XXX
 SG_ UIS_gtwSocUartRxStatBadChecksum m211 : 32|32@1+ (1,0) [0|4294967295] "" Vector__XXX
 SG_ UIS_gpsmanagerMemUsage m212 : 32|32@1+ (1,0) [0|4294967295] "" Vector__XXX
 SG_ UIS_gpsmanagerCPUUsage m213 : 32|32@1+ (1,0) [0|4294967295] "" Vector__XXX
 SG_ UIS_godot_TIME_PROCESS m214 : 32|32@1+ (1,0) [0|4294967295] "" Vector__XXX
 SG_ UIS_godot_TIME_FPS m215 : 32|32@1+ (1,0) [0|4294967295] "" Vector__XXX
 SG_ UIS_godot_MEMORY_STATIC m216 : 32|32@1+ (1,0) [0|4294967295] "" Vector__XXX
 SG_ UIS_godot_MEMORY_DYNAMIC m217 : 32|32@1+ (1,0) [0|4294967295] "" Vector__XXX
 SG_ UIS_godotMemUsage m218 : 32|32@1+ (1,0) [0|4294967295] "" Vector__XXX
 SG_ UIS_godotCPUUsage m219 : 32|32@1+ (1,0) [0|4294967295] "" Vector__XXX
 SG_ UIS_firmwareReleaseScope m220 : 32|32@1+ (1,0) [0|4294967295] "" Vector__XXX
 SG_ UIS_featureSuperchargingEnabled m221 : 32|32@1+ (1,0) [0|4294967295] "" Vector__XXX
 SG_ UIS_estimatedOccupancyCount m222 : 32|32@1+ (1,0) [0|4294967295] "" Vector__XXX
 SG_ UIS_embeddedGameState m223 : 32|32@1+ (1,0) [0|4294967295] "" Vector__XXX
 SG_ UIS_embeddedGameName m224 : 32|32@1+ (1,0) [0|4294967295] "" Vector__XXX
 SG_ UIS_dynamicTriggersTelemetryServ m225 : 32|32@1+ (1,0) [0|4294967295] "" Vector__XXX
 SG_ UIS_dynamicTriggersOutputManager m226 : 32|32@1+ (1,0) [0|4294967295] "" Vector__XXX
 SG_ UIS_dynamicTriggersHRLServiceSta m227 : 32|32@1+ (1,0) [0|4294967295] "" Vector__XXX
 SG_ UIS_dynamicTriggersCampaignState m228 : 32|32@1+ (1,0) [1|4294967295] "" Vector__XXX
 SG_ UIS_dumTclipUploadState m229 : 32|32@1+ (1,0) [0|4294967295] "" Vector__XXX
 SG_ UIS_dumTclipUploadActive m230 : 32|32@1+ (1,0) [0|4294967295] "" Vector__XXX
 SG_ UIS_dumTclipTransferCount m231 : 32|32@1+ (1,0) [0|4294967295] "" Vector__XXX
 SG_ UIS_dumTclipSuccessfulUploadCoun m232 : 32|32@1+ (1,0) [0|4294967295] "" Vector__XXX
 SG_ UIS_dumTclipClipCount m233 : 32|32@1+ (1,0) [0|4294967295] "" Vector__XXX
 SG_ UIS_dmRearTouchDeviceExists m234 : 32|32@1+ (1,0) [0|4294967295] "" Vector__XXX
 SG_ UIS_dmRearPowerState m235 : 32|32@1+ (1,0) [0|1] "" Vector__XXX
 SG_ UIS_dmRearLinkCheckOk m236 : 32|32@1+ (1,0) [0|1] "" Vector__XXX
 SG_ UIS_dmRearEnabled m237 : 32|32@1+ (1,0) [0|4294967295] "" Vector__XXX
 SG_ UIS_dmRearConnected m238 : 32|32@1+ (1,0) [0|4294967295] "" Vector__XXX
 SG_ UIS_dmRearBacklightPowerLevel m239 : 32|32@1+ (1,0) [0|4294967295] "" Vector__XXX
 SG_ UIS_dmRearBacklightNits m240 : 32|32@1+ (1,0) [0|4294967295] "" Vector__XXX
 SG_ UIS_dmRearBacklightFault m241 : 32|32@1+ (1,0) [0|4294967295] "" Vector__XXX
 SG_ UIS_dmRearBacklightDutyCycle m242 : 32|32@1+ (1,0) [0|4294967295] "" Vector__XXX
 SG_ UIS_dmRearBacklightDevExists m243 : 32|32@1+ (1,0) [0|1] "" Vector__XXX
 SG_ UIS_dmRearAsilStatusMsb m244 : 32|32@1+ (1,0) [0|4294967295] "" Vector__XXX
 SG_ UIS_dmRearAsilStatusLsb m245 : 32|32@1+ (1,0) [0|4294967295] "" Vector__XXX
 SG_ UIS_dmIcuTouchIrqCount m246 : 32|32@1+ (1,0) [0|4294967295] "" Vector__XXX
 SG_ UIS_dmIcuPowerState m247 : 32|32@1+ (1,0) [0|1] "" Vector__XXX
 SG_ UIS_dmIcuLinkCheckOk m248 : 32|32@1+ (1,0) [0|1] "" Vector__XXX
 SG_ UIS_dmIcuEnabled m249 : 32|32@1+ (1,0) [0|4294967295] "" Vector__XXX
 SG_ UIS_dmIcuConnected m250 : 32|32@1+ (1,0) [0|4294967295] "" Vector__XXX
 SG_ UIS_dmIcuBacklightPowerLevel m251 : 32|32@1+ (1,0) [0|4294967295] "" Vector__XXX
 SG_ UIS_dmIcuBacklightNits m252 : 32|32@1+ (1,0) [0|4294967295] "" Vector__XXX
 SG_ UIS_dmIcuBacklightFault m253 : 32|32@1+ (1,0) [0|4294967295] "" Vector__XXX
 SG_ UIS_dmIcuBacklightDutyCycle m254 : 32|32@1+ (1,0) [0|4294967295] "" Vector__XXX
 SG_ UIS_dmIcuBacklightDevExists m255 : 32|32@1+ (1,0) [0|1] "" Vector__XXX
 SG_ UIS_dmIcuAsilShortFlag m256 : 32|32@1+ (1,0) [0|4294967295] "" Vector__XXX
 SG_ UIS_dmIcuAsilResumeFlag m257 : 32|32@1+ (1,0) [0|4294967295] "" Vector__XXX
 SG_ UIS_dmIcuAsilOpenFlag m258 : 32|32@1+ (1,0) [0|4294967295] "" Vector__XXX
 SG_ UIS_dmIcuAsilFirmwareStatus m259 : 32|32@1+ (1,0) [0|4294967295] "" Vector__XXX
 SG_ UIS_dmGatewayLinkWedged m260 : 32|32@1+ (1,0) [0|4294967295] "" Vector__XXX
 SG_ UIS_dmCenterTouchIrqCount m261 : 32|32@1+ (1,0) [0|4294967295] "" Vector__XXX
 SG_ UIS_dmCenterTouchDeviceExists m262 : 32|32@1+ (1,0) [0|4294967295] "" Vector__XXX
 SG_ UIS_dmCenterSOsdVideoCrcData m263 : 32|32@1+ (1,0) [0|4294967295] "" Vector__XXX
 SG_ UIS_dmCenterSOsdExactCrcCheck m264 : 32|32@1+ (1,0) [0|4294967295] "" Vector__XXX
 SG_ UIS_dmCenterPowerState m265 : 32|32@1+ (1,0) [0|1] "" Vector__XXX
 SG_ UIS_dmCenterOsdDisplayedState m266 : 32|32@1+ (1,0) [0|1] "" Vector__XXX
 SG_ UIS_dmCenterOsdDayNightState m267 : 32|32@1+ (1,0) [0|4294967295] "" Vector__XXX
 SG_ UIS_dmCenterModeSettingStatus m268 : 32|32@1+ (1,0) [0|4294967295] "" Vector__XXX
 SG_ UIS_dmCenterMOsdVideoCrcData m269 : 32|32@1+ (1,0) [0|4294967295] "" Vector__XXX
 SG_ UIS_dmCenterMOsdExactCrcCheck m270 : 32|32@1+ (1,0) [0|4294967295] "" Vector__XXX
 SG_ UIS_dmCenterLinkCheckOk m271 : 32|32@1+ (1,0) [0|1] "" Vector__XXX
 SG_ UIS_dmCenterEnabled m272 : 32|32@1+ (1,0) [0|4294967295] "" Vector__XXX
 SG_ UIS_dmCenterConnected m273 : 32|32@1+ (1,0) [0|4294967295] "" Vector__XXX
 SG_ UIS_dmCenterBacklightPowerLevel m274 : 32|32@1+ (1,0) [0|4294967295] "" Vector__XXX
 SG_ UIS_dmCenterBacklightNits m275 : 32|32@1+ (1,0) [0|4294967295] "" Vector__XXX
 SG_ UIS_dmCenterBacklightFault m276 : 32|32@1+ (1,0) [0|4294967295] "" Vector__XXX
 SG_ UIS_dmCenterBacklightDutyCycle m277 : 32|32@1+ (1,0) [0|4294967295] "" Vector__XXX
 SG_ UIS_dmCenterBacklightDevExists m278 : 32|32@1+ (1,0) [0|1] "" Vector__XXX
 SG_ UIS_dmCenterBacklightControlDefe m279 : 32|32@1+ (1,0) [0|4294967295] "" Vector__XXX
 SG_ UIS_dmCenterAsilShortFlag m280 : 32|32@1+ (1,0) [0|4294967295] "" Vector__XXX
 SG_ UIS_dmCenterAsilResumeFlag m281 : 32|32@1+ (1,0) [0|4294967295] "" Vector__XXX
 SG_ UIS_dmCenterAsilOpenFlag m282 : 32|32@1+ (1,0) [0|4294967295] "" Vector__XXX
 SG_ UIS_dmCenterAsilFirmwareStatus m283 : 32|32@1+ (1,0) [0|4294967295] "" Vector__XXX
 SG_ UIS_dmCenterAsilCalibrationSync m284 : 32|32@1+ (1,0) [0|4294967295] "" Vector__XXX
 SG_ UIS_dgpuTemperature m285 : 32|32@1+ (1,0) [0|4294967295] "" Vector__XXX
 SG_ UIS_developerMode m286 : 32|32@1+ (1,0) [0|4294967295] "" Vector__XXX
 SG_ UIS_dashcamviewerMemUsage m287 : 32|32@1+ (1,0) [0|4294967295] "" Vector__XXX
 SG_ UIS_dashcamviewerCPUUsage m288 : 32|32@1+ (1,0) [0|4294967295] "" Vector__XXX
 SG_ UIS_dashcamTransferTimeMs m289 : 32|32@1+ (1,0) [0|4294967295] "" Vector__XXX
 SG_ UIS_dashcamTransferSizeMB m290 : 32|32@1+ (1,0) [0|4294967295] "" Vector__XXX
 SG_ UIS_dashcamTransferRateMBps m291 : 32|32@1+ (1,0) [0|4294967295] "" Vector__XXX
 SG_ UIS_dashcamTransferFileCount m292 : 32|32@1+ (1,0) [0|4294967295] "" Vector__XXX
 SG_ UIS_dashcamTransferCount m293 : 32|32@1+ (1,0) [0|4294967295] "" Vector__XXX
 SG_ UIS_dashcamStorageState m294 : 32|32@1+ (1,0) [0|4294967295] "" Vector__XXX
 SG_ UIS_dashcamStorageSentryMB m295 : 32|32@1+ (1,0) [0|4294967295] "" Vector__XXX
 SG_ UIS_dashcamStorageSavedMB m296 : 32|32@1+ (1,0) [0|4294967295] "" Vector__XXX
 SG_ UIS_dashcamStorageRecentMB m297 : 32|32@1+ (1,0) [0|4294967295] "" Vector__XXX
 SG_ UIS_dashcamStorageAvailableMB m298 : 32|32@1+ (1,0) [0|4294967295] "" Vector__XXX
 SG_ UIS_dashcamState m299 : 32|32@1+ (1,0) [0|4294967295] "" Vector__XXX
 SG_ UIS_dashcamSavedToSentryCount m300 : 32|32@1+ (1,0) [0|4294967295] "" Vector__XXX
 SG_ UIS_dashcamSavedToSavedCount m301 : 32|32@1+ (1,0) [0|4294967295] "" Vector__XXX
 SG_ UIS_dashcamSavedToOnboardCount m302 : 32|32@1+ (1,0) [0|4294967295] "" Vector__XXX
 SG_ UIS_dashcamOnboardTransferCount m303 : 32|32@1+ (1,0) [0|4294967295] "" Vector__XXX
 SG_ UIS_dashcamOnboardSavePressCount m304 : 32|32@1+ (1,0) [0|4294967295] "" Vector__XXX
 SG_ UIS_dashcamOnboardMB m305 : 32|32@1+ (1,0) [0|4294967295] "" Vector__XXX
 SG_ UIS_dashcamOnboardAvailableMB m306 : 32|32@1+ (1,0) [0|4294967295] "" Vector__XXX
 SG_ UIS_dasAutonomyControlMessageMia m307 : 32|32@1+ (1,0) [0|4294967295] "" Vector__XXX
 SG_ UIS_cpuTemperature m308 : 32|32@1+ (1,0) [0|4294967295] "" Vector__XXX
 SG_ UIS_connectedToInternet m309 : 32|32@1+ (1,0) [0|4294967295] "" Vector__XXX
 SG_ UIS_compositorRenderMinRenderTim m310 : 32|32@1+ (1,0) [0|4294967295] "" Vector__XXX
 SG_ UIS_compositorRenderMinFrameTime m311 : 32|32@1+ (1,0) [0|4294967295] "" Vector__XXX
 SG_ UIS_compositorRenderMaxRenderTim m312 : 32|32@1+ (1,0) [0|4294967295] "" Vector__XXX
 SG_ UIS_compositorRenderMaxFrameTime m313 : 32|32@1+ (1,0) [0|4294967295] "" Vector__XXX
 SG_ UIS_compositorRenderGpuPercentag m314 : 32|32@1+ (1,0) [0|4294967295] "" Vector__XXX
 SG_ UIS_compositorRenderFrameRate m315 : 32|32@1+ (1,0) [0|4294967295] "" Vector__XXX
 SG_ UIS_compositorRenderFrameCount m316 : 32|32@1+ (1,0) [0|4294967295] "" Vector__XXX
 SG_ UIS_compositorRenderAvgRenderTim m317 : 32|32@1+ (1,0) [0|4294967295] "" Vector__XXX
 SG_ UIS_compositorFrameMonitorState m318 : 32|32@1+ (1,0) [0|4294967295] "" Vector__XXX
 SG_ UIS_cobaltlinuxMemUsage m319 : 32|32@1+ (1,0) [0|4294967295] "" Vector__XXX
 SG_ UIS_cobaltlinuxCPUUsage m320 : 32|32@1+ (1,0) [0|4294967295] "" Vector__XXX
 SG_ UIS_clusterMemUsage m321 : 32|32@1+ (1,0) [0|4294967295] "" Vector__XXX
 SG_ UIS_clusterMeanFPS m322 : 32|32@1+ (1,0) [0|4294967295] "" Vector__XXX
 SG_ UIS_clusterMaxFrametime m323 : 32|32@1+ (1,0) [0|4294967295] "" Vector__XXX
 SG_ UIS_clusterFramesOver200Ms m324 : 32|32@1+ (1,0) [0|4294967295] "" Vector__XXX
 SG_ UIS_clusterFramesOver100Ms m325 : 32|32@1+ (1,0) [0|4294967295] "" Vector__XXX
 SG_ UIS_clusterDisplayState m326 : 32|32@1+ (1,0) [0|4294967295] "" Vector__XXX
 SG_ UIS_clusterCPUUsage m327 : 32|32@1+ (1,0) [0|4294967295] "" Vector__XXX
 SG_ UIS_chromiumadapterMemUsage m328 : 32|32@1+ (1,0) [0|4294967295] "" Vector__XXX
 SG_ UIS_chromiumadapterCPUUsage m329 : 32|32@1+ (1,0) [0|4294967295] "" Vector__XXX
 SG_ UIS_chargeOnSolarNoChargeReason m330 : 32|32@1+ (1,0) [0|4294967295] "" Vector__XXX
 SG_ UIS_chargeLocationId m331 : 32|32@1+ (1,0) [0|4294967295] "" Vector__XXX
 SG_ UIS_ceruleanx8664MemUsage m332 : 32|32@1+ (1,0) [0|4294967295] "" Vector__XXX
 SG_ UIS_ceruleanx8664CPUUsage m333 : 32|32@1+ (1,0) [0|4294967295] "" Vector__XXX
 SG_ UIS_centerDisplayState m334 : 32|32@1+ (1,0) [0|4294967295] "" Vector__XXX
 SG_ UIS_centerDisplayEvent m335 : 32|32@1+ (1,0) [0|4294967295] "" Vector__XXX
 SG_ UIS_centerDispAsilB_msb m336 : 32|32@1+ (1,0) [0|4294967295] "" Vector__XXX
 SG_ UIS_centerDispAsilB_lsb m337 : 32|32@1+ (1,0) [0|4294967295] "" Vector__XXX
 SG_ UIS_centerDispAsilA_msb m338 : 32|32@1+ (1,0) [0|4294967295] "" Vector__XXX
 SG_ UIS_centerDispAsilA_lsb m339 : 32|32@1+ (1,0) [0|4294967295] "" Vector__XXX
 SG_ UIS_cellularLinkManagerState m340 : 32|32@1+ (1,0) [0|4294967295] "" Vector__XXX
 SG_ UIS_cellularConnectivityStatus m341 : 32|32@1+ (1,0) [0|1] "" Vector__XXX
 SG_ UIS_carAssistState m369 : 32|32@1+ (1,0) [0|4294967295] "" Vector__XXX
 SG_ UIS_carAssistSessionCount m370 : 32|32@1+ (1,0) [0|4294967295] "" Vector__XXX
 SG_ UIS_carAssistMicMuted m371 : 32|32@1+ (1,0) [0|1] "" Vector__XXX
 SG_ UIS_carAssistMicAlsaRms m372 : 32|32@1+ (1,0) [0|4294967295] "" Vector__XXX
 SG_ UIS_carAssistErrorCode m373 : 32|32@1+ (1,0) [0|4294967295] "" Vector__XXX
 SG_ UIS_cameraSelectableRenderState m374 : 32|32@1+ (1,0) [0|4294967295] "" Vector__XXX
 SG_ UIS_cameraSelectablePipeline m375 : 32|32@1+ (1,0) [0|4294967295] "" Vector__XXX
 SG_ UIS_cameraSelectablePacketState m376 : 32|32@1+ (1,0) [0|4294967295] "" Vector__XXX
 SG_ UIS_cameraRearViewStreamMissing m377 : 32|32@1+ (1,0) [0|4294967295] "" Vector__XXX
 SG_ UIS_cameraRearViewRenderState m378 : 32|32@1+ (1,0) [0|4294967295] "" Vector__XXX
 SG_ UIS_cameraRearViewPopup m379 : 32|32@1+ (1,0) [0|4294967295] "" Vector__XXX
 SG_ UIS_cameraRearViewPipeline m380 : 32|32@1+ (1,0) [0|4294967295] "" Vector__XXX
 SG_ UIS_cameraRearViewPacketState m381 : 32|32@1+ (1,0) [0|4294967295] "" Vector__XXX
 SG_ UIS_cameraRRepeaterStreamMissing m382 : 32|32@1+ (1,0) [0|1] "" Vector__XXX
 SG_ UIS_cameraRRepeaterRenderState m383 : 32|32@1+ (1,0) [0|4294967295] "" Vector__XXX
 SG_ UIS_cameraRRepeaterPopup m384 : 32|32@1+ (1,0) [0|1] "" Vector__XXX
 SG_ UIS_cameraRRepeaterPipeline m385 : 32|32@1+ (1,0) [0|4294967295] "" Vector__XXX
 SG_ UIS_cameraRRepeaterPacketState m386 : 32|32@1+ (1,0) [0|4294967295] "" Vector__XXX
 SG_ UIS_cameraRRepeaterMaxFrametime m387 : 32|32@1+ (1,0) [0|4294967295] "" Vector__XXX
 SG_ UIS_cameraRRepeaterLateFrames m388 : 32|32@1+ (1,0) [0|4294967295] "" Vector__XXX
 SG_ UIS_cameraRRepeaterFramerate m389 : 32|32@1+ (1,0) [0|4294967295] "" Vector__XXX
 SG_ UIS_cameraRDownwardRenderState m390 : 32|32@1+ (1,0) [0|4294967295] "" Vector__XXX
 SG_ UIS_cameraRDownwardPipeline m391 : 32|32@1+ (1,0) [0|4294967295] "" Vector__XXX
 SG_ UIS_cameraRDownwardPacketState m392 : 32|32@1+ (1,0) [0|4294967295] "" Vector__XXX
 SG_ UIS_cameraLRepeaterStreamMissing m393 : 32|32@1+ (1,0) [0|1] "" Vector__XXX
 SG_ UIS_cameraLRepeaterRenderState m394 : 32|32@1+ (1,0) [0|4294967295] "" Vector__XXX
 SG_ UIS_cameraLRepeaterPopup m395 : 32|32@1+ (1,0) [0|1] "" Vector__XXX
 SG_ UIS_cameraLRepeaterPipeline m396 : 32|32@1+ (1,0) [0|4294967295] "" Vector__XXX
 SG_ UIS_cameraLRepeaterPacketState m397 : 32|32@1+ (1,0) [0|4294967295] "" Vector__XXX
 SG_ UIS_cameraLRepeaterMaxFrametime m398 : 32|32@1+ (1,0) [0|4294967295] "" Vector__XXX
 SG_ UIS_cameraLRepeaterLateFrames m399 : 32|32@1+ (1,0) [0|4294967295] "" Vector__XXX
 SG_ UIS_cameraLRepeaterFramerate m400 : 32|32@1+ (1,0) [0|4294967295] "" Vector__XXX
 SG_ UIS_cameraLDownwardRenderState m401 : 32|32@1+ (1,0) [0|4294967295] "" Vector__XXX
 SG_ UIS_cameraLDownwardPipeline m402 : 32|32@1+ (1,0) [0|4294967295] "" Vector__XXX
 SG_ UIS_cameraLDownwardPacketState m403 : 32|32@1+ (1,0) [0|4294967295] "" Vector__XXX
 SG_ UIS_cameraFrontStreamMissing m404 : 32|32@1+ (1,0) [0|4294967295] "" Vector__XXX
 SG_ UIS_cameraFrontRenderState m405 : 32|32@1+ (1,0) [0|4294967295] "" Vector__XXX
 SG_ UIS_cameraFrontPopup m406 : 32|32@1+ (1,0) [0|4294967295] "" Vector__XXX
 SG_ UIS_cameraFrontPipeline m407 : 32|32@1+ (1,0) [0|4294967295] "" Vector__XXX
 SG_ UIS_cameraFrontPacketState m408 : 32|32@1+ (1,0) [0|4294967295] "" Vector__XXX
 SG_ UIS_cameraBackupStreamQuality m409 : 32|32@1+ (1,0) [0|4294967295] "" Vector__XXX
 SG_ UIS_cameraBackupStreamMissing m410 : 32|32@1+ (1,0) [0|1] "" Vector__XXX
 SG_ UIS_cameraBackupRenderState m411 : 32|32@1+ (1,0) [0|4294967295] "" Vector__XXX
 SG_ UIS_cameraBackupPopup m412 : 32|32@1+ (1,0) [0|1] "" Vector__XXX
 SG_ UIS_cameraBackupPipeline m413 : 32|32@1+ (1,0) [0|4294967295] "" Vector__XXX
 SG_ UIS_cameraBackupPacketState m414 : 32|32@1+ (1,0) [0|4294967295] "" Vector__XXX
 SG_ UIS_cameraBackupMaxFrametime m415 : 32|32@1+ (1,0) [0|4294967295] "" Vector__XXX
 SG_ UIS_pmSuspendHookIndex m416 : 32|32@1+ (1,0) [0|4294967295] "" Vector__XXX
 SG_ UIS_cameraBackupLateFrames m417 : 32|32@1+ (1,0) [0|4294967295] "" Vector__XXX
 SG_ UIS_cameraBackupFramerate m418 : 32|32@1+ (1,0) [0|4294967295] "" Vector__XXX
 SG_ UIS_camBackupDecodeMinFrametime m419 : 32|32@1+ (1,0) [0|4294967295] "" Vector__XXX
 SG_ UIS_camBackupDecodeMaxFrametime m420 : 32|32@1+ (1,0) [0|4294967295] "" Vector__XXX
 SG_ UIS_camBackupDecodeFramecount m421 : 32|32@1+ (1,0) [0|4294967295] "" Vector__XXX
 SG_ UIS_camBackupDecodeAvgFrametime m422 : 32|32@1+ (1,0) [0|4294967295] "" Vector__XXX
 SG_ UIS_bootCount m423 : 32|32@1+ (1,0) [0|4294967295] "" Vector__XXX
 SG_ UIS_boardTemperature m424 : 32|32@1+ (1,0) [0|4294967295] "" Vector__XXX
 SG_ UIS_bluetoothState m425 : 32|32@1+ (1,0) [0|4294967295] "" Vector__XXX
 SG_ UIS_bluetoothStackState m426 : 32|32@1+ (1,0) [0|4294967295] "" Vector__XXX
 SG_ UIS_bluetoothStackRearState m427 : 32|32@1+ (1,0) [0|4294967295] "" Vector__XXX
 SG_ UIS_bluetoothPairResult m428 : 32|32@1+ (1,0) [0|4294967295] "" Vector__XXX
 SG_ UIS_bluetoothMemUsage m429 : 32|32@1+ (1,0) [0|4294967295] "" Vector__XXX
 SG_ UIS_bluetoothConnectionState m430 : 32|32@1+ (1,0) [0|4294967295] "" Vector__XXX
 SG_ UIS_bluetoothCPUUsage m431 : 32|32@1+ (1,0) [0|4294967295] "" Vector__XXX
 SG_ UIS_bluetoothAutoconnectAttempts m432 : 32|32@1+ (1,0) [0|4294967295] "" Vector__XXX
 SG_ UIS_bluetoothAutoconnectActive m433 : 32|32@1+ (1,0) [0|4294967295] "" Vector__XXX
 SG_ UIS_bluetoothAutoConnectionState m434 : 32|32@1+ (1,0) [0|4294967295] "" Vector__XXX
 SG_ UIS_bifrostOdinEngineUp m435 : 32|32@1+ (1,0) [0|4294967295] "" Vector__XXX
 SG_ UIS_bifrostOdinEngineRequests m436 : 32|32@1+ (1,0) [0|4294967295] "" Vector__XXX
 SG_ UIS_bifrostMemUsage m437 : 32|32@1+ (1,0) [0|4294967295] "" Vector__XXX
 SG_ UIS_bifrostCPUUsage m438 : 32|32@1+ (1,0) [0|4294967295] "" Vector__XXX
 SG_ UIS_backlightUserRequest m439 : 32|32@1+ (1,0) [0|4294967295] "" Vector__XXX
 SG_ UIS_audioVolumeLevel m440 : 32|32@1+ (1,0) [0|4294967295] "" Vector__XXX
 SG_ UIS_audioType m441 : 32|32@1+ (1,0) [0|4294967295] "" Vector__XXX
 SG_ UIS_audioState m442 : 32|32@1+ (1,0) [0|4294967295] "" Vector__XXX
 SG_ UIS_audioSource m443 : 32|32@1+ (1,0) [0|4294967295] "" Vector__XXX
 SG_ UIS_audioPWSGain m444 : 32|32@1+ (1,0) [0|4294967295] "" Vector__XXX
 SG_ UIS_audioMediaPlaying m445 : 32|32@1+ (1,0) [0|4294967295] "" Vector__XXX
 SG_ UIS_audioMediaBrowsing m446 : 32|32@1+ (1,0) [0|4294967295] "" Vector__XXX
 SG_ UIS_audioA2BRediscoveryCount m447 : 32|32@1+ (1,0) [0|4294967295] "" Vector__XXX
 SG_ UIS_apeHardwareMinorVersion m448 : 32|32@1+ (1,0) [0|4294967295] "" Vector__XXX
 SG_ UIS_amdSocPkgPower m449 : 32|32@1+ (1,0) [0|4294967295] "" Vector__XXX
 SG_ UIS_activeAppView m450 : 32|32@1+ (1,0) [0|4294967295] "" Vector__XXX
 SG_ UIS_CamViewerServiceEnabled m451 : 32|32@1+ (1,0) [0|4294967295] "" Vector__XXX

BO_ 979 UI_airbagCutoffStatus: 1 UI
 SG_ UI_airbagCutoffSwState : 0|2@1+ (1,0) [0|3] "" Vector__XXX
 SG_ UI_warningIndicatorStatus : 2|2@1+ (1,0) [0|2] "" Vector__XXX

BO_TX_BU_ 881 : RCM;
BO_TX_BU_ 1415 : TCU2;
BO_TX_BU_ 1413 : TCU2;
BO_TX_BU_ 1414 : TCU2;
BO_TX_BU_ 1412 : TCU2;
BO_TX_BU_ 1159 : TCU;
BO_TX_BU_ 1157 : TCU;
BO_TX_BU_ 1158 : TCU;
BO_TX_BU_ 1155 : TCU;
BO_TX_BU_ 1603 : UDS;
BO_TX_BU_ 1551 : UDS;
BO_TX_BU_ 1056 : UIS;
BO_TX_BU_ 979 : UI;
CM_ SG_ 1297 RCM_a117_eventDriveOrientation "Restraint control module: a117 event drive orientation";
CM_ SG_ 1297 RCM_a117_imuZaccelChnlMonitTmp "Restraint control module: a117 imu zaccel chnl monit tmp";
CM_ SG_ 1297 RCM_a117_imuZaccelChnlMonitPerm "Restraint control module: a117 imu zaccel chnl monit perm";
CM_ SG_ 1297 RCM_a117_eventIDFsignal "Restraint control module: a117 event ID fsignal";
CM_ SG_ 1297 RCM_a117_eventFrontLeftSeatbelt "Restraint control module: a117 event front left seatbelt";
CM_ SG_ 1297 RCM_a117_eventFrontRightSeatbelt "Restraint control module: a117 event front right seatbelt";
CM_ SG_ 1297 RCM_a117_eventVehicleSpeed "Restraint control module: a117 event vehicle speed";
CM_ SG_ 1297 RCM_a117_eventSteeringAngle "Restraint control module: a117 event steering angle";
CM_ SG_ 1297 RCM_a117_eventDriverBrakeApply "Restraint control module: a117 event driver brake apply; raw 3 = signal not available (SNA)";
CM_ SG_ 1297 RCM_a117_eventAccelPedalPos "Restraint control module: a117 event accel pedal pos; raw 255 = signal not available (SNA)";
CM_ SG_ 1297 RCM_a118_eventArmStatus "Restraint control module: a118 event arm status";
CM_ SG_ 1297 RCM_a118_eventFactoryMode "Restraint control module: a118 event factory mode";
CM_ SG_ 1297 RCM_a118_eventDiagEnabled "Restraint control module: a118 event diag enabled";
CM_ SG_ 1297 RCM_a118_eventDriveOrientation "Restraint control module: a118 event drive orientation";
CM_ SG_ 1297 RCM_a118_imuInPlaneSnsrMonitTmp "Restraint control module: a118 imu in plane snsr monit tmp";
CM_ SG_ 1297 RCM_a118_imuInPlaneSnsrMonitPerm "Restraint control module: a118 imu in plane snsr monit perm";
CM_ SG_ 1297 RCM_a118_eventIDFsignal "Restraint control module: a118 event ID fsignal";
CM_ SG_ 1297 RCM_a118_eventFrontLeftSeatbelt "Restraint control module: a118 event front left seatbelt";
CM_ SG_ 1297 RCM_a118_eventFrontRightSeatbelt "Restraint control module: a118 event front right seatbelt";
CM_ SG_ 1297 RCM_a118_eventVehicleSpeed "Restraint control module: a118 event vehicle speed";
CM_ SG_ 1297 RCM_a118_eventSteeringAngle "Restraint control module: a118 event steering angle";
CM_ SG_ 1297 RCM_a118_eventDriverBrakeApply "Restraint control module: a118 event driver brake apply; raw 3 = signal not available (SNA)";
CM_ SG_ 1297 RCM_a118_eventAccelPedalPos "Restraint control module: a118 event accel pedal pos; raw 255 = signal not available (SNA)";
CM_ BO_ 881 "Restraint control module message: alert matrix";
CM_ SG_ 881 RCM_matrixIndex "Restraint control module: matrix index";
CM_ SG_ 881 RCM_a000_crashDetected "Restraint control module: a000 crash detected";
CM_ SG_ 881 RCM_a001_nearDeploy "Restraint control module: a001 near deploy";
CM_ SG_ 881 RCM_a002_airbagsNotArmed "Restraint control module: a002 airbags not armed";
CM_ SG_ 881 RCM_a003_warningIndicator "Restraint control module: a003 warning indicator";
CM_ SG_ 881 RCM_a004_internalFault "Restraint control module: a004 internal fault";
CM_ SG_ 881 RCM_a005_crcError "Restraint control module: a005 crc error";
CM_ SG_ 881 RCM_a006_batteryVoltageRange "Restraint control module: a006 battery voltage range";
CM_ SG_ 881 RCM_a007_powerSupplyExternal "Restraint control module: a007 power supply external";
CM_ SG_ 881 RCM_a008_powerSupplyInternal "Restraint control module: a008 power supply internal";
CM_ SG_ 881 RCM_a009_reprogramLimit "Restraint control module: a009 reprogram limit";
CM_ SG_ 881 RCM_a010_scmDisabled "Restraint control module: a010 scm disabled";
CM_ SG_ 881 RCM_a011_eepromDataLocked "Restraint control module: a011 eeprom data locked";
CM_ SG_ 881 RCM_a012_vinStorage "Restraint control module: a012 vin storage";
CM_ SG_ 881 RCM_a013_driverOrientation "Restraint control module: a013 driver orientation";
CM_ SG_ 881 RCM_a014_driverABStage1 "Restraint control module: a014 driver AB stage1";
CM_ SG_ 881 RCM_a015_driverABStage2 "Restraint control module: a015 driver AB stage2";
CM_ SG_ 881 RCM_a016_passABStage1 "Restraint control module: a016 pass AB stage1";
CM_ SG_ 881 RCM_a017_passABStage2 "Restraint control module: a017 pass AB stage2";
CM_ SG_ 881 RCM_a018_passengerActiveVent "Restraint control module: a018 passenger active vent";
CM_ SG_ 881 RCM_a019_pretenShldrFrontLeft "Restraint control module: a019 preten shldr front left";
CM_ SG_ 881 RCM_a020_pretenShldFrontRight "Restraint control module: a020 preten shld front right";
CM_ SG_ 881 RCM_a021_pretenLapFrontLeft "Restraint control module: a021 preten lap front left";
CM_ SG_ 881 RCM_a022_pretenLapFrontRight "Restraint control module: a022 preten lap front right";
CM_ SG_ 881 RCM_a023_loadLimiterLeftSide "Restraint control module: a023 load limiter left side";
CM_ SG_ 881 RCM_a024_loadLimiterRightSide "Restraint control module: a024 load limiter right side";
CM_ SG_ 881 RCM_a025_kneeABDriver "Restraint control module: a025 knee AB driver";
CM_ SG_ 881 RCM_a026_kneeABFrontPassenger "Restraint control module: a026 knee AB front passenger";
CM_ SG_ 881 RCM_a027_sideAB1stRowLeft "Restraint control module: a027 side ab1st row left";
CM_ SG_ 881 RCM_a028_sideAB1stRowRight "Restraint control module: a028 side ab1st row right";
CM_ SG_ 881 RCM_a029_driverABActiveVent "Restraint control module: a029 driver AB active vent";
CM_ SG_ 881 RCM_a030_farSideInboardAirbag "Restraint control module: a030 far side inboard airbag";
CM_ SG_ 881 RCM_a031_frontCenterAirbag "Restraint control module: a031 front center airbag";
CM_ SG_ 881 RCM_a032_curtainABLeft "Restraint control module: a032 curtain AB left";
CM_ SG_ 881 RCM_a033_curtainABRight "Restraint control module: a033 curtain AB right";
CM_ SG_ 881 RCM_a034_preten2ndRowLeft "Restraint control module: a034 preten2nd row left";
CM_ SG_ 881 RCM_a035_preten2ndRowRight "Restraint control module: a035 preten2nd row right";
CM_ SG_ 881 RCM_a036_curAB2ndRowLeft "Restraint control module: a036 cur ab2nd row left";
CM_ SG_ 881 RCM_a037_curAB2ndRowRight "Restraint control module: a037 cur ab2nd row right";
CM_ SG_ 881 RCM_a038_unusedA "Restraint control module: a038 unused a";
CM_ SG_ 881 RCM_a039_unusedB "Restraint control module: a039 unused b";
CM_ SG_ 881 RCM_a040_hoodActuatorRight "Restraint control module: a040 hood actuator right";
CM_ SG_ 881 RCM_a041_hoodActuatorLeft "Restraint control module: a041 hood actuator left";
CM_ SG_ 881 RCM_a042_ens1Line "Restraint control module: a042 ens1 line";
CM_ SG_ 881 RCM_a043_ens2Line "Restraint control module: a043 ens2 line";
CM_ SG_ 881 RCM_a044_upFrontSensorLeft "Restraint control module: a044 up front sensor left";
CM_ SG_ 881 RCM_a045_upFrontSensorRight "Restraint control module: a045 up front sensor right";
CM_ SG_ 881 RCM_a046_sideAccelBPillarLeft "Restraint control module: a046 side accel b pillar left";
CM_ SG_ 881 RCM_a047_sideAccelBPillarRight "Restraint control module: a047 side accel b pillar right";
CM_ SG_ 881 RCM_a048_sideAccelCPillarLeft "Restraint control module: a048 side accel c pillar left";
CM_ SG_ 881 RCM_a049_sideAccelCPillarRight "Restraint control module: a049 side accel c pillar right";
CM_ SG_ 881 RCM_a050_upFrontSensorCenter "Restraint control module: a050 up front sensor center";
CM_ SG_ 881 RCM_a051_pressureFrontLftDoor "Restraint control module: a051 pressure front lft door";
CM_ SG_ 881 RCM_a052_pressureFrontRtDoor "Restraint control module: a052 pressure front rt door";
CM_ SG_ 881 RCM_a053_pressurePedProLeft "Restraint control module: a053 pressure ped pro left";
CM_ SG_ 881 RCM_a054_pressurePedProRight "Restraint control module: a054 pressure ped pro right";
CM_ SG_ 881 RCM_a055_inertialMeasurement "Restraint control module: a055 inertial measurement";
CM_ SG_ 881 RCM_a056_passengerFrontOCS "Restraint control module: a056 passenger front OCS";
CM_ SG_ 881 RCM_a057_driverOCS "Restraint control module: a057 driver OCS";
CM_ SG_ 881 RCM_a058_buckle1stRowLeft "Restraint control module: a058 buckle1st row left";
CM_ SG_ 881 RCM_a059_buckle1stRowRight "Restraint control module: a059 buckle1st row right";
CM_ SG_ 881 RCM_a060_stpsLeft "Restraint control module: a060 stps left";
CM_ SG_ 881 RCM_a061_stpsRight "Restraint control module: a061 stps right";
CM_ SG_ 881 RCM_a062_alrSwitch "Restraint control module: a062 alr switch";
CM_ SG_ 881 RCM_a063_sbsw2ndRowRight "Restraint control module: a063 sbsw2nd row right";
CM_ SG_ 881 RCM_a064_hardwareCodingPin1 "Restraint control module: a064 hardware coding pin1";
CM_ SG_ 881 RCM_a065_driverOrientConfigPin "Restraint control module: a065 driver orient config pin";
CM_ SG_ 881 RCM_a066_seatBackSw2ndRowLeft "Restraint control module: a066 seat back sw2nd row left";
CM_ SG_ 881 RCM_a067_comCANInitFailure "Restraint control module: a067 com CAN init failure";
CM_ SG_ 881 RCM_a068_comChassisBusOff "Restraint control module: a068 com chassis bus off";
CM_ SG_ 881 RCM_a069_comCHCANPH7 "Restraint control module: a069 com CHCANPH7";
CM_ SG_ 881 RCM_a070_comCHCANPH8 "Restraint control module: a070 com CHCANPH8";
CM_ SG_ 881 RCM_a071_comCHCANPH9 "Restraint control module: a071 com CHCANPH9";
CM_ SG_ 881 RCM_a072_comUnused "Restraint control module: a072 com unused";
CM_ SG_ 881 RCM_a073_comCHCANPH4 "Restraint control module: a073 com CHCANPH4";
CM_ SG_ 881 RCM_a074_comCHCANPH5 "Restraint control module: a074 com CHCANPH5";
CM_ SG_ 881 RCM_a075_comCHCANPH6 "Restraint control module: a075 com CHCANPH6";
CM_ SG_ 881 RCM_a076_comEPBLStatus "Restraint control module: a076 com EPBL status";
CM_ SG_ 881 RCM_a077_comEPBRStatus "Restraint control module: a077 com EPBR status";
CM_ SG_ 881 RCM_a078_comOCS1PStatus "Restraint control module: a078 com OCS1 p status";
CM_ SG_ 881 RCM_a079_comOCS1DStatus "Restraint control module: a079 com OCS1 d status";
CM_ SG_ 881 RCM_a080_comGTWACS "Restraint control module: a080 com GTWACS";
CM_ SG_ 881 RCM_a081_comVCFRONTLVPwr "Restraint control module: a081 com VCFRONTLV pwr";
CM_ SG_ 881 RCM_a082_comUIodo "Restraint control module: a082 com u iodo";
CM_ SG_ 881 RCM_a083_comGTWCarState "Restraint control module: a083 com GTW car state";
CM_ SG_ 881 RCM_a084_comTPMSStatus "Restraint control module: a084 com TPMS status";
CM_ SG_ 881 RCM_a085_comGTWCarConfig "Restraint control module: a085 com GTW car config";
CM_ SG_ 881 RCM_a086_comVINMIA "Restraint control module: a086 com VINMIA";
CM_ SG_ 881 RCM_a087_comCANSilent "Restraint control module: a087 com CAN silent";
CM_ SG_ 881 RCM_a088_comCHCANPH2 "Restraint control module: a088 com CHCANPH2";
CM_ SG_ 881 RCM_a089_comCHCANPH3 "Restraint control module: a089 com CHCANPH3";
CM_ SG_ 881 RCM_a090_comPartyBusOff "Restraint control module: a090 com party bus off";
CM_ SG_ 881 RCM_a091_comEPAS3PsysStatus "Restraint control module: a091 com EPAS3 psys status";
CM_ SG_ 881 RCM_a092_comDASISF "Restraint control module: a092 com DASISF";
CM_ SG_ 881 RCM_a093_comVCLEFTStatus "Restraint control module: a093 com VCLEFT status";
CM_ SG_ 881 RCM_a094_comVCRIGHTStatus "Restraint control module: a094 com VCRIGHT status";
CM_ SG_ 881 RCM_a095_comESPstatus "Restraint control module: a095 com ES pstatus";
CM_ SG_ 881 RCM_a096_comESPwheelSpeeds "Restraint control module: a096 com ES pwheel speeds";
CM_ SG_ 881 RCM_a097_comDIspeed "Restraint control module: a097 com d ispeed";
CM_ SG_ 881 RCM_a098_comDIchassisControl "Restraint control module: a098 com d ichassis control";
CM_ SG_ 881 RCM_a099_comDItorque "Restraint control module: a099 com d itorque";
CM_ SG_ 881 RCM_a100_comDIsystemStatus "Restraint control module: a100 com d isystem status";
CM_ SG_ 881 RCM_a101_idfSystem "Restraint control module: a101 idf system";
CM_ SG_ 881 RCM_a102_imuYawR8OffstCompLim "Restraint control module: a102 imu yaw R8 offst comp lim";
CM_ SG_ 881 RCM_a103_imuPtchR8OffstCompLim "Restraint control module: a103 imu ptch R8 offst comp lim";
CM_ SG_ 881 RCM_a104_imuRollR8OffstCompLim "Restraint control module: a104 imu roll R8 offst comp lim";
CM_ SG_ 881 RCM_a105_imuLongAccOffstCompLim "Restraint control module: a105 imu long acc offst comp lim";
CM_ SG_ 881 RCM_a106_imuLatAccOffstCompLim "Restraint control module: a106 imu lat acc offst comp lim";
CM_ SG_ 881 RCM_a107_imuVertAccOffstCompLim "Restraint control module: a107 imu vert acc offst comp lim";
CM_ SG_ 881 RCM_a108_crashAlgoWakeup "Restraint control module: a108 crash algo wakeup";
CM_ SG_ 881 RCM_a109_abuseImmunity "Restraint control module: a109 abuse immunity";
CM_ SG_ 881 RCM_a110_factoryMode "Restraint control module: a110 factory mode";
CM_ SG_ 881 RCM_a111_diagnosticsEnabled "Restraint control module: a111 diagnostics enabled";
CM_ SG_ 881 RCM_a112_imuYawRate "Restraint control module: a112 imu yaw rate";
CM_ SG_ 881 RCM_a113_imuPitchRate "Restraint control module: a113 imu pitch rate";
CM_ SG_ 881 RCM_a114_imuRollRate "Restraint control module: a114 imu roll rate";
CM_ SG_ 881 RCM_a115_imuLinearAcceleration "Restraint control module: a115 imu linear acceleration";
CM_ SG_ 881 RCM_a116_imuLateralAcceleration "Restraint control module: a116 imu lateral acceleration";
CM_ SG_ 881 RCM_a117_imuVerticalAcceleration "Restraint control module: a117 imu vertical acceleration";
CM_ SG_ 881 RCM_a118_imuInPlaneAcceleration "Restraint control module: a118 imu in plane acceleration";
CM_ BO_ 1415 "TCU2 ECU message: sleep config";
CM_ SG_ 1415 TCU2_tc10Version "Indicates which version of Open Alliance's TC10 protocol is supported by the modem; raw 0 = signal not available (SNA)";
CM_ BO_ 1413 "TCU2 ECU message: alert log";
CM_ SG_ 1413 TCU2_alertID "TCU2 ECU: alert ID";
CM_ SG_ 1413 TCU2_alertState "TCU2 ECU: alert state";
CM_ SG_ 1413 TCU2_w001_FailCode "TCU2 ECU: w001 fail code";
CM_ SG_ 1413 TCU2_w002_RejCause "TCU2 ECU: w002 rej cause";
CM_ SG_ 1413 TCU2_w003_CallFailCode "TCU2 ECU: w003 call fail code";
CM_ SG_ 1413 TCU2_w004_MSDFailCode "TCU2 ECU: w004 MSD fail code";
CM_ SG_ 1413 TCU2_w006_Count "TCU2 ECU: w006 count";
CM_ SG_ 1413 TCU2_w007_Count "TCU2 ECU: w007 count";
CM_ SG_ 1413 TCU2_w009_CrashCode "TCU2 ECU: w009 crash code";
CM_ SG_ 1413 TCU2_w012_DataRAT "TCU2 ECU: w012 data RAT";
CM_ SG_ 1413 TCU2_w012_RSRP "TCU2 ECU: w012 RSRP";
CM_ SG_ 1413 TCU2_w012_RSRQ "TCU2 ECU: w012 RSRQ";
CM_ SG_ 1413 TCU2_w012_MNC "TCU2 ECU: w012 MNC";
CM_ SG_ 1413 TCU2_w012_AvgQueueUsage "TCU2 ECU: w012 avg queue usage";
CM_ SG_ 1413 TCU2_w012_NSAAvailable "TCU2 ECU: w012 NSA available";
CM_ SG_ 1413 TCU2_w013_DataRAT "TCU2 ECU: w013 data RAT";
CM_ SG_ 1413 TCU2_w013_RSRP "TCU2 ECU: w013 RSRP";
CM_ SG_ 1413 TCU2_w013_RSRQ "TCU2 ECU: w013 RSRQ";
CM_ SG_ 1413 TCU2_w013_MNC "TCU2 ECU: w013 MNC";
CM_ SG_ 1413 TCU2_w013_AvgQueueUsage "TCU2 ECU: w013 avg queue usage";
CM_ SG_ 1413 TCU2_w013_NSAAvailable "TCU2 ECU: w013 NSA available";
CM_ SG_ 1413 TCU2_w014_Reason "TCU2 ECU: w014 reason";
CM_ BO_ 1414 "TCU2 ECU message: alert matrix1";
CM_ SG_ 1414 TCU2_w001_IMSRegistrationFailed "TCU2 ECU: w001 IMS registration failed";
CM_ SG_ 1414 TCU2_w002_CellRegRejected "TCU2 ECU: w002 cell reg rejected";
CM_ SG_ 1414 TCU2_w003_ECallFailed "TCU2 ECU: w003 e call failed";
CM_ SG_ 1414 TCU2_w004_MSDTransmissionFailed "TCU2 ECU: w004 MSD transmission failed";
CM_ SG_ 1414 TCU2_w005_SIMSlotError "TCU2 ECU: w005 SIM slot error";
CM_ SG_ 1414 TCU2_w006_MpssUnavailable "TCU2 ECU: w006 mpss unavailable";
CM_ SG_ 1414 TCU2_w007_ModemUnreachable "TCU2 ECU: w007 modem unreachable";
CM_ SG_ 1414 TCU2_w008_KernelPanic "TCU2 ECU: w008 kernel panic";
CM_ SG_ 1414 TCU2_w009_WifiFirmwareCrash "TCU2 ECU: w009 wifi firmware crash";
CM_ SG_ 1414 TCU2_w010_WifiDumpDetected "TCU2 ECU: w010 wifi dump detected";
CM_ SG_ 1414 TCU2_w011_CellDumpDetected "TCU2 ECU: w011 cell dump detected";
CM_ SG_ 1414 TCU2_w012_UplinkDegraded "TCU2 ECU: w012 uplink degraded";
CM_ SG_ 1414 TCU2_w013_UplinkQueueFull "TCU2 ECU: w013 uplink queue full";
CM_ SG_ 1414 TCU2_w014_HostapdCrash "TCU2 ECU: w014 hostapd crash";
CM_ SG_ 1414 TCU2_w015_NPNSubscriptionActive "TCU2 ECU: w015 NPN subscription active";
CM_ SG_ 1414 TCU2_w016_IMEIMismatch "TCU2 ECU: w016 IMEI mismatch";
CM_ BO_ 1412 "TCU2 ECU message: log";
CM_ SG_ 1412 TCU2_logMux "TCU2 ECU: log mux";
CM_ SG_ 1412 TCU2_cpuTemp "Indicates the current temperature reported by the Central Processing Unit (CPU) in the modem application processor";
CM_ SG_ 1412 TCU2_cpuUsage "Indicates the current CPU usage in percentage reported by the modem application processor";
CM_ SG_ 1412 TCU2_mdmCoreTemperature "Indicates the current Communication Processor (CP) temperature reported by the modem CP.";
CM_ SG_ 1412 TCU2_availableMemory "Indicates the currently available Random Access Memory in the modem application processor";
CM_ SG_ 1412 TCU2_pwm "Indicates the active Pulse Width Modulation (PWM) duty cycle applied to the modem fan.";
CM_ SG_ 1412 TCU2_pwmcap "Indicates the active Pulse Width Modulation (PWM) duty cycle restriciton applied to the modem fan.";
CM_ SG_ 1412 TCU2_totalResumes "Indicates the total amount of times the modem has been resumed";
CM_ SG_ 1412 TCU2_mdmUplinkQueueSize "TCU2 ECU: mdm uplink queue size";
CM_ SG_ 1412 TCU2_mdmRSRP "TCU2 ECU: mdm RSRP";
CM_ SG_ 1412 TCU2_mdmSINR "TCU2 ECU: mdm SINR";
CM_ SG_ 1412 TCU2_mdmUplinkAllowedRate "TCU2 ECU: mdm uplink allowed rate";
CM_ SG_ 1412 TCU2_mdmUplinkAvgRate "TCU2 ECU: mdm uplink avg rate";
CM_ SG_ 1412 TCU2_mdmServiceState "TCU2 ECU: mdm service state";
CM_ SG_ 1412 TCU2_mdmIMSStatus "Indicates the current IP Multimedia System (IMS) registration state.";
CM_ SG_ 1412 TCU2_mdmSIMStatus "TCU2 ECU: mdm SIM status";
CM_ SG_ 1412 TCU2_mdmBusyActive "Reports whether the modem busy service is active on the modem application processor; raw 4294967295 = signal not available (SNA)";
CM_ SG_ 1412 TCU2_modemUptime "Indicates the current modem Application Processor uptime.";
CM_ SG_ 1412 TCU2_mdmDataRat "Reports which Radio Access Technology (RAT) is active for the current data bearer.";
CM_ SG_ 1412 TCU2_mdmDataCallStatus "Indicates the current state of the Packet Data Protocol (PDP) context.";
CM_ SG_ 1412 TCU2_mdmNSAAvailable "TCU2 ECU: mdm NSA available";
CM_ SG_ 1412 TCU2_mdmPCIID "TCU2 ECU: mdm PCIID";
CM_ SG_ 1412 TCU2_mdmMnc "TCU2 ECU: mdm mnc";
CM_ SG_ 1412 TCU2_mdmMcc "TCU2 ECU: mdm mcc";
CM_ SG_ 1412 TCU2_mdmTxKiloBytes "TCU2 ECU: mdm tx kilo bytes";
CM_ SG_ 1412 TCU2_mdmDataCallTermReason "Indicates the internal reason which the Data Call was terminated.";
CM_ SG_ 1412 TCU2_mdmDataCallTermCode "Indicates the termination code informed by the network that caused the Data Call termination.";
CM_ SG_ 1412 TCU2_cellularSMState "Indicates the current state of cellular state machine.";
CM_ SG_ 1412 TCU2_tcuSMState "Reports the state of the Telematics Control Unit (TCU) state machine.";
CM_ SG_ 1412 TCU2_checkInternetFailCount "Reports the count of unsuccessful cellular connectivity checks.";
CM_ SG_ 1412 TCU2_mdmBand "Indicates the band which the baseband processor is currently attached to the cellular network.";
CM_ SG_ 1412 TCU2_wakeSource "Indicates the source of wake event in the modem.";
CM_ BO_ 1159 "TCU ECU message: sleep config";
CM_ SG_ 1159 TCU_tc10Version "Indicates which version of Open Alliance's TC10 protocol is supported by the modem; raw 0 = signal not available (SNA)";
CM_ BO_ 1157 "TCU ECU message: alert log";
CM_ SG_ 1157 TCU_alertID "TCU ECU: alert ID";
CM_ SG_ 1157 TCU_alertState "TCU ECU: alert state";
CM_ SG_ 1157 TCU_w001_FailCode "TCU ECU: w001 fail code";
CM_ SG_ 1157 TCU_w002_RejCause "TCU ECU: w002 rej cause";
CM_ SG_ 1157 TCU_w003_CallFailCode "TCU ECU: w003 call fail code";
CM_ SG_ 1157 TCU_w004_MSDFailCode "TCU ECU: w004 MSD fail code";
CM_ SG_ 1157 TCU_w006_Count "TCU ECU: w006 count";
CM_ SG_ 1157 TCU_w007_Count "TCU ECU: w007 count";
CM_ SG_ 1157 TCU_w009_CrashCode "TCU ECU: w009 crash code";
CM_ SG_ 1157 TCU_w012_DataRAT "TCU ECU: w012 data RAT";
CM_ SG_ 1157 TCU_w012_RSRP "TCU ECU: w012 RSRP";
CM_ SG_ 1157 TCU_w012_RSRQ "TCU ECU: w012 RSRQ";
CM_ SG_ 1157 TCU_w012_MNC "TCU ECU: w012 MNC";
CM_ SG_ 1157 TCU_w012_AvgQueueUsage "TCU ECU: w012 avg queue usage";
CM_ SG_ 1157 TCU_w012_NSAAvailable "TCU ECU: w012 NSA available";
CM_ SG_ 1157 TCU_w013_DataRAT "TCU ECU: w013 data RAT";
CM_ SG_ 1157 TCU_w013_RSRP "TCU ECU: w013 RSRP";
CM_ SG_ 1157 TCU_w013_RSRQ "TCU ECU: w013 RSRQ";
CM_ SG_ 1157 TCU_w013_MNC "TCU ECU: w013 MNC";
CM_ SG_ 1157 TCU_w013_AvgQueueUsage "TCU ECU: w013 avg queue usage";
CM_ SG_ 1157 TCU_w013_NSAAvailable "TCU ECU: w013 NSA available";
CM_ SG_ 1157 TCU_w014_Reason "TCU ECU: w014 reason";
CM_ BO_ 1158 "TCU ECU message: alert matrix1";
CM_ SG_ 1158 TCU_w001_IMSRegistrationFailed "TCU ECU: w001 IMS registration failed";
CM_ SG_ 1158 TCU_w002_CellRegRejected "TCU ECU: w002 cell reg rejected";
CM_ SG_ 1158 TCU_w003_ECallFailed "TCU ECU: w003 e call failed";
CM_ SG_ 1158 TCU_w004_MSDTransmissionFailed "TCU ECU: w004 MSD transmission failed";
CM_ SG_ 1158 TCU_w005_SIMSlotError "TCU ECU: w005 SIM slot error";
CM_ SG_ 1158 TCU_w006_MpssUnavailable "TCU ECU: w006 mpss unavailable";
CM_ SG_ 1158 TCU_w007_ModemUnreachable "TCU ECU: w007 modem unreachable";
CM_ SG_ 1158 TCU_w008_KernelPanic "TCU ECU: w008 kernel panic";
CM_ SG_ 1158 TCU_w009_WifiFirmwareCrash "TCU ECU: w009 wifi firmware crash";
CM_ SG_ 1158 TCU_w010_WifiDumpDetected "TCU ECU: w010 wifi dump detected";
CM_ SG_ 1158 TCU_w011_CellDumpDetected "TCU ECU: w011 cell dump detected";
CM_ SG_ 1158 TCU_w012_UplinkDegraded "TCU ECU: w012 uplink degraded";
CM_ SG_ 1158 TCU_w013_UplinkQueueFull "TCU ECU: w013 uplink queue full";
CM_ SG_ 1158 TCU_w014_HostapdCrash "TCU ECU: w014 hostapd crash";
CM_ SG_ 1158 TCU_w015_NPNSubscriptionActive "TCU ECU: w015 NPN subscription active";
CM_ SG_ 1158 TCU_w016_IMEIMismatch "TCU ECU: w016 IMEI mismatch";
CM_ BO_ 1155 "TCU ECU message: log";
CM_ SG_ 1155 TCU_logMux "TCU ECU: log mux";
CM_ SG_ 1155 TCU_cpuTemp "Indicates the current temperature reported by the Central Processing Unit (CPU) in the modem application processor";
CM_ SG_ 1155 TCU_cpuUsage "Indicates the current CPU usage in percentage reported by the modem application processor";
CM_ SG_ 1155 TCU_mdmCoreTemperature "Indicates the current Communication Processor (CP) temperature reported by the modem CP.";
CM_ SG_ 1155 TCU_availableMemory "Indicates the currently available Random Access Memory in the modem application processor";
CM_ SG_ 1155 TCU_pwm "Indicates the active Pulse Width Modulation (PWM) duty cycle applied to the modem fan.";
CM_ SG_ 1155 TCU_pwmcap "Indicates the active Pulse Width Modulation (PWM) duty cycle restriciton applied to the modem fan.";
CM_ SG_ 1155 TCU_totalResumes "Indicates the total amount of times the modem has been resumed";
CM_ SG_ 1155 TCU_mdmUplinkQueueSize "TCU ECU: mdm uplink queue size";
CM_ SG_ 1155 TCU_mdmRSRP "TCU ECU: mdm RSRP";
CM_ SG_ 1155 TCU_mdmSINR "TCU ECU: mdm SINR";
CM_ SG_ 1155 TCU_mdmUplinkAllowedRate "TCU ECU: mdm uplink allowed rate";
CM_ SG_ 1155 TCU_mdmUplinkAvgRate "TCU ECU: mdm uplink avg rate";
CM_ SG_ 1155 TCU_mdmServiceState "TCU ECU: mdm service state";
CM_ SG_ 1155 TCU_mdmIMSStatus "Indicates the current IP Multimedia System (IMS) registration state.";
CM_ SG_ 1155 TCU_mdmSIMStatus "TCU ECU: mdm SIM status";
CM_ SG_ 1155 TCU_mdmBusyActive "Reports whether the modem busy service is active on the modem application processor; raw 4294967295 = signal not available (SNA)";
CM_ SG_ 1155 TCU_modemUptime "Indicates the current modem Application Processor uptime.";
CM_ SG_ 1155 TCU_mdmDataRat "Reports which Radio Access Technology (RAT) is active for the current data bearer.";
CM_ SG_ 1155 TCU_mdmDataCallStatus "Indicates the current state of the Packet Data Protocol (PDP) context.";
CM_ SG_ 1155 TCU_mdmNSAAvailable "TCU ECU: mdm NSA available";
CM_ SG_ 1155 TCU_mdmPCIID "TCU ECU: mdm PCIID";
CM_ SG_ 1155 TCU_mdmMnc "TCU ECU: mdm mnc";
CM_ SG_ 1155 TCU_mdmMcc "TCU ECU: mdm mcc";
CM_ SG_ 1155 TCU_mdmTxKiloBytes "TCU ECU: mdm tx kilo bytes";
CM_ SG_ 1155 TCU_mdmDataCallTermReason "Indicates the internal reason which the Data Call was terminated.";
CM_ SG_ 1155 TCU_mdmDataCallTermCode "Indicates the termination code informed by the network that caused the Data Call termination.";
CM_ SG_ 1155 TCU_cellularSMState "Indicates the current state of cellular state machine.";
CM_ SG_ 1155 TCU_tcuSMState "Reports the state of the Telematics Control Unit (TCU) state machine.";
CM_ SG_ 1155 TCU_checkInternetFailCount "Reports the count of unsuccessful cellular connectivity checks.";
CM_ SG_ 1155 TCU_mdmBand "Indicates the band which the baseband processor is currently attached to the cellular network.";
CM_ SG_ 1155 TCU_wakeSource "Indicates the source of wake event in the modem.";
CM_ BO_ 1603 "UDS ECU message: ocs1p request";
CM_ SG_ 1603 UDS_ocs1pRequestData "UDS ECU: ocs1p request data";
CM_ BO_ 1551 "UDS ECU message: thc request";
CM_ SG_ 1551 UDS_thcRequestData_H "UDS ECU: thc request data h";
CM_ SG_ 1551 UDS_thcRequestData_L "UDS ECU: thc request data l";
CM_ BO_ 1056 "UIS ECU message: log";
CM_ SG_ 1056 UIS_logMux "UIS ECU: log mux";
CM_ SG_ 1056 UIS_zramWriteTicks "UIS ECU: zram write ticks";
CM_ SG_ 1056 UIS_zramWriteIO "UIS ECU: zram write IO";
CM_ SG_ 1056 UIS_zramReadTicks "UIS ECU: zram read ticks";
CM_ SG_ 1056 UIS_zramReadIO "UIS ECU: zram read IO";
CM_ SG_ 1056 UIS_zramOriginalSize "UIS ECU: zram original size";
CM_ SG_ 1056 UIS_zramNotifyFree "UIS ECU: zram notify free";
CM_ SG_ 1056 UIS_zramInvalidIO "UIS ECU: zram invalid IO";
CM_ SG_ 1056 UIS_zramFailedWrites "UIS ECU: zram failed writes";
CM_ SG_ 1056 UIS_zramFailedReads "UIS ECU: zram failed reads";
CM_ SG_ 1056 UIS_zramCompressionRatio "UIS ECU: zram compression ratio";
CM_ SG_ 1056 UIS_zramCompressedSize "UIS ECU: zram compressed size";
CM_ SG_ 1056 UIS_wifiTemperature "Current temperature reported for wifi";
CM_ SG_ 1056 UIS_wifiStackState "WiFi stack state description";
CM_ SG_ 1056 UIS_wifiStackReady "UIS ECU: wifi stack ready";
CM_ SG_ 1056 UIS_wifiBars "WiFi bars for connected network";
CM_ SG_ 1056 UIS_wifiAutoJoinLowRSSI "Indicates an attempt to auto-join a known network with low Received Signal Strength Indicator (RSSI).";
CM_ SG_ 1056 UIS_webbrowserMemUsage "UIS ECU: webbrowser mem usage";
CM_ SG_ 1056 UIS_webbrowserCPUUsage "UIS ECU: webbrowser CPU usage";
CM_ SG_ 1056 UIS_vmtouchMemUsage "UIS ECU: vmtouch mem usage";
CM_ SG_ 1056 UIS_vmtouchCPUUsage "UIS ECU: vmtouch CPU usage";
CM_ SG_ 1056 UIS_videodMemUsage "UIS ECU: videod mem usage";
CM_ SG_ 1056 UIS_videodCPUUsage "UIS ECU: videod CPU usage";
CM_ SG_ 1056 UIS_vehicleMemUsage "UIS ECU: vehicle mem usage";
CM_ SG_ 1056 UIS_vehicleCPUUsage "UIS ECU: vehicle CPU usage";
CM_ SG_ 1056 UIS_valhallaserverMemUsage "UIS ECU: valhallaserver mem usage";
CM_ SG_ 1056 UIS_valhallaserverCPUUsage "UIS ECU: valhallaserver CPU usage";
CM_ SG_ 1056 UIS_valetMode "UI Valet Mode state";
CM_ SG_ 1056 UIS_uiQtCarUptime "Touchscreen UI software uptime";
CM_ SG_ 1056 UIS_uiQtCarSwapUsage "Signal reported by UIS ECU";
CM_ SG_ 1056 UIS_uiMeanFPS "UI mean frames per second over a 60s period";
CM_ SG_ 1056 UIS_uiMaxFrametime "UIS ECU: ui max frametime";
CM_ SG_ 1056 UIS_uiFrametimeGearShiftPToR "UIS ECU: ui frametime gear shift p to r";
CM_ SG_ 1056 UIS_uiFrametimeGearShiftDToR "UIS ECU: ui frametime gear shift d to r";
CM_ SG_ 1056 UIS_uiFramesOver200Ms "UIS ECU: ui frames over200 ms";
CM_ SG_ 1056 UIS_uiFramesOver100Ms "UIS ECU: ui frames over100 ms";
CM_ SG_ 1056 UIS_tunerVoltageUBatt "UIS ECU: tuner voltage u batt";
CM_ SG_ 1056 UIS_tunerVoltageOperation "Radio tuner operating voltage (mV)";
CM_ SG_ 1056 UIS_tunerVoltageMQS "UIS ECU: tuner voltage MQS";
CM_ SG_ 1056 UIS_tunerVoltageAntenna2 "Radio tuner voltage (mV) for antenna 2";
CM_ SG_ 1056 UIS_tunerVoltageAntenna1 "Radio tuner voltage (mV) for antenna 1";
CM_ SG_ 1056 UIS_tunerVoltage3V3 "UIS ECU: tuner voltage3 V3";
CM_ SG_ 1056 UIS_tunerVoltage1V8 "UIS ECU: tuner voltage1 V8";
CM_ SG_ 1056 UIS_tunerTemperatureFahrenheit "UIS ECU: tuner temperature fahrenheit";
CM_ SG_ 1056 UIS_tunerTemperatureCelsius "UIS ECU: tuner temperature celsius";
CM_ SG_ 1056 UIS_tunerCurrentAntenna2 "Radio tuner current (mA) for antenna 2";
CM_ SG_ 1056 UIS_tunerCurrentAntenna1 "Radio tuner current (mA) for antenna 1";
CM_ SG_ 1056 UIS_touchEventsAggCount "UIS ECU: touch events agg count";
CM_ SG_ 1056 UIS_tmserverMemUsage "UIS ECU: tmserver mem usage";
CM_ SG_ 1056 UIS_tmserverCPUUsage "UIS ECU: tmserver CPU usage";
CM_ SG_ 1056 UIS_thermalResistance "UIS ECU: thermal resistance";
CM_ SG_ 1056 UIS_thermalProfile "UIS ECU: thermal profile; raw 0 = signal not available (SNA)";
CM_ SG_ 1056 UIS_testDriveMode "UIS ECU: test drive mode";
CM_ SG_ 1056 UIS_teslachromiumMemUsage "UIS ECU: teslachromium mem usage";
CM_ SG_ 1056 UIS_teslachromiumCPUUsage "UIS ECU: teslachromium CPU usage";
CM_ SG_ 1056 UIS_teslaMediaCacheSize "UIS ECU: tesla media cache size";
CM_ SG_ 1056 UIS_teslaMediaCacheCost "UIS ECU: tesla media cache cost";
CM_ SG_ 1056 UIS_teleopStreamXrunCount "UIS ECU: teleop stream xrun count";
CM_ SG_ 1056 UIS_teleopPhoneCallActive "UIS ECU: teleop phone call active";
CM_ SG_ 1056 UIS_teleopPacketDrops "UIS ECU: teleop packet drops";
CM_ SG_ 1056 UIS_teleopMinPacketDelta "UIS ECU: teleop min packet delta";
CM_ SG_ 1056 UIS_teleopMaxPacketDelta "UIS ECU: teleop max packet delta";
CM_ SG_ 1056 UIS_teleopAvgPacketDelta "UIS ECU: teleop avg packet delta";
CM_ SG_ 1056 UIS_tegraModemManState "Tegra Cellular Modem Manager state";
CM_ SG_ 1056 UIS_systemWakeTime "Length of time since wake or boot if UI has not slept (seconds)";
CM_ SG_ 1056 UIS_systemUptime "Reports the system uptime duration.";
CM_ SG_ 1056 UIS_systemMemSwapUsage "UIS ECU: system mem swap usage";
CM_ SG_ 1056 UIS_suspensionGeofence "Status of suspension geofence add or remove";
CM_ SG_ 1056 UIS_superchargePaymentNeeded "Reports that Supercharging payment is needed.";
CM_ SG_ 1056 UIS_sudokuMemUsage "UIS ECU: sudoku mem usage";
CM_ SG_ 1056 UIS_sudokuCPUUsage "UIS ECU: sudoku CPU usage";
CM_ SG_ 1056 UIS_spotifyserverMemUsage "UIS ECU: spotifyserver mem usage";
CM_ SG_ 1056 UIS_spotifyserverCPUUsage "UIS ECU: spotifyserver CPU usage";
CM_ SG_ 1056 UIS_speechrecoMemUsage "UIS ECU: speechreco mem usage";
CM_ SG_ 1056 UIS_speechrecoCPUUsage "UIS ECU: speechreco CPU usage";
CM_ SG_ 1056 UIS_solitaireMemUsage "UIS ECU: solitaire mem usage";
CM_ SG_ 1056 UIS_solitaireCPUUsage "UIS ECU: solitaire CPU usage";
CM_ SG_ 1056 UIS_softwareUpdateState "UIS ECU: software update state";
CM_ SG_ 1056 UIS_softwareUpdatePrimDownload "UIS ECU: software update prim download";
CM_ SG_ 1056 UIS_softwareInstallPopupStatus "UIS ECU: software install popup status";
CM_ SG_ 1056 UIS_sleepType "Reports the system sleep type.";
CM_ SG_ 1056 UIS_sleepTime "Reports the system sleep duration.";
CM_ SG_ 1056 UIS_sleepState "Reports the system sleep state.";
CM_ SG_ 1056 UIS_sleepCount "UIS ECU: sleep count";
CM_ SG_ 1056 UIS_slackerLoginResult "Reports Slacker Media login events";
CM_ SG_ 1056 UIS_settingsAutoTurnSignal "UIS ECU: settings auto turn signal";
CM_ SG_ 1056 UIS_serviceModePlus "Signal reported by UIS ECU";
CM_ SG_ 1056 UIS_serviceMode "Signal reported by UIS ECU";
CM_ SG_ 1056 UIS_serverMemUsage "UIS ECU: server mem usage";
CM_ SG_ 1056 UIS_serverCPUUsage "UIS ECU: server CPU usage";
CM_ SG_ 1056 UIS_sentryState "Sentry Mode state";
CM_ SG_ 1056 UIS_sentryNeedsNap "Sentry Mode sleep indicator, max uptime reached";
CM_ SG_ 1056 UIS_sentryIncidentCount "Sentry Mode incident count, initializes to 0";
CM_ SG_ 1056 UIS_scheduledChargingMode "Scheduled charging mode";
CM_ SG_ 1056 UIS_scheduleChargeStartTime "Reports the scheduled charging start date time in MMDDHHMM format.";
CM_ SG_ 1056 UIS_scheduleChargeEndTime "Reports the scheduled charging end date time in MMDDHHMM format.";
CM_ SG_ 1056 UIS_robotaxiModeActive "UIS ECU: robotaxi mode active";
CM_ SG_ 1056 UIS_remoteRequestType "Reports the signed remote request type sent to vehicle, excluding closures and start requests.";
CM_ SG_ 1056 UIS_releasenotesMemUsage "UIS ECU: releasenotes mem usage";
CM_ SG_ 1056 UIS_releasenotesCPUUsage "UIS ECU: releasenotes CPU usage";
CM_ SG_ 1056 UIS_rearDisplayUserPresent "Indicates if a user is present in the rear seat based on seat occupancy and rear display usage";
CM_ SG_ 1056 UIS_rearDisplayState "Reports the rear display state.";
CM_ SG_ 1056 UIS_radioserveMemUsage "UIS ECU: radioserve mem usage";
CM_ SG_ 1056 UIS_radioserveCPUUsage "UIS ECU: radioserve CPU usage";
CM_ SG_ 1056 UIS_qtcarMemUsage "Signal reported by UIS ECU";
CM_ SG_ 1056 UIS_qtcarCPUUsage "Signal reported by UIS ECU";
CM_ SG_ 1056 UIS_psiMemSome "UIS ECU: psi mem some";
CM_ SG_ 1056 UIS_psiMemFull "UIS ECU: psi mem full";
CM_ SG_ 1056 UIS_psiIOSome "UIS ECU: psi IO some";
CM_ SG_ 1056 UIS_psiIOFull "UIS ECU: psi IO full";
CM_ SG_ 1056 UIS_psiCpuSome "UIS ECU: psi cpu some";
CM_ SG_ 1056 UIS_powerManagerState "UI power manager state signal; raw 18 = signal not available (SNA)";
CM_ SG_ 1056 UIS_polytopiax8664MemUsage "polytopiax8664's Resident Memory usage in MB";
CM_ SG_ 1056 UIS_polytopiax8664CPUUsage "polytopiax8664's CPU usage in CPU usage %";
CM_ SG_ 1056 UIS_odinStatusCmdResult "Signal reported by UIS ECU";
CM_ SG_ 1056 UIS_odinStatusCmdDurationMs "Signal reported by UIS ECU";
CM_ SG_ 1056 UIS_odinProcessState "Signal reported by UIS ECU";
CM_ SG_ 1056 UIS_odinPeriodicTaskState "Signal reported by UIS ECU";
CM_ SG_ 1056 UIS_odinOrchestratorStartCount "Signal reported by UIS ECU";
CM_ SG_ 1056 UIS_odinOrchestratorFailCount "Signal reported by UIS ECU";
CM_ SG_ 1056 UIS_odinNetworkStartCount "Signal reported by UIS ECU";
CM_ SG_ 1056 UIS_odinNetworkFailCount "Signal reported by UIS ECU";
CM_ SG_ 1056 UIS_odinMemUsage "Signal reported by UIS ECU";
CM_ SG_ 1056 UIS_odinListTasksCmdResult "Signal reported by UIS ECU";
CM_ SG_ 1056 UIS_odinListTasksCmdDurationMs "Signal reported by UIS ECU";
CM_ SG_ 1056 UIS_odinHrlUploadLimits "Signal reported by UIS ECU";
CM_ SG_ 1056 UIS_odinHrlLogUploadState "Signal reported by UIS ECU";
CM_ SG_ 1056 UIS_odinHermesConnectionState "Signal reported by UIS ECU";
CM_ SG_ 1056 UIS_odinGatewayConnectionState "Signal reported by UIS ECU";
CM_ SG_ 1056 UIS_odinFileSystemState "Signal reported by UIS ECU";
CM_ SG_ 1056 UIS_odinEcuLogUploadState "Signal reported by UIS ECU";
CM_ SG_ 1056 UIS_odinEcuLogForceTriggerUpload "Signal reported by UIS ECU";
CM_ SG_ 1056 UIS_odinCPUUsage "Signal reported by UIS ECU";
CM_ SG_ 1056 UIS_odinAuthFailCount "Signal reported by UIS ECU";
CM_ SG_ 1056 UIS_odinAuthCount "Signal reported by UIS ECU";
CM_ SG_ 1056 UIS_nvmeTemperature "UIS ECU: nvme temperature";
CM_ SG_ 1056 UIS_nvmePercentLifetimeUsed "UIS ECU: nvme percent lifetime used";
CM_ SG_ 1056 UIS_nvmeDataUnitsWritten100mb "UIS ECU: nvme data units written100mb";
CM_ SG_ 1056 UIS_numUncorrMemErrorsECC "UIS ECU: num uncorr mem errors ECC";
CM_ SG_ 1056 UIS_numCorrMemErrorsECC "UIS ECU: num corr mem errors ECC";
CM_ SG_ 1056 UIS_nuanceserverMemUsage "UIS ECU: nuanceserver mem usage";
CM_ SG_ 1056 UIS_nuanceserverCPUUsage "UIS ECU: nuanceserver CPU usage";
CM_ SG_ 1056 UIS_netWifiTxRate "UIS ECU: net wifi tx rate";
CM_ SG_ 1056 UIS_netWifiTxCount "UIS ECU: net wifi tx count";
CM_ SG_ 1056 UIS_netWifiRxRate "UIS ECU: net wifi rx rate";
CM_ SG_ 1056 UIS_netWifiRxCount "UIS ECU: net wifi rx count";
CM_ SG_ 1056 UIS_netEthTxRate "UIS ECU: net eth tx rate";
CM_ SG_ 1056 UIS_netEthTxCount "UIS ECU: net eth tx count";
CM_ SG_ 1056 UIS_netEthRxRate "UIS ECU: net eth rx rate";
CM_ SG_ 1056 UIS_netEthRxErrorRate "UIS ECU: net eth rx error rate";
CM_ SG_ 1056 UIS_netEthRxErrorCount "UIS ECU: net eth rx error count";
CM_ SG_ 1056 UIS_netEthRxDroppedRate "UIS ECU: net eth rx dropped rate";
CM_ SG_ 1056 UIS_netEthRxDroppedCount "UIS ECU: net eth rx dropped count";
CM_ SG_ 1056 UIS_netEthRxCount "UIS ECU: net eth rx count";
CM_ SG_ 1056 UIS_netCellTxRate "UIS ECU: net cell tx rate";
CM_ SG_ 1056 UIS_netCellTxCount "UIS ECU: net cell tx count";
CM_ SG_ 1056 UIS_netCellRxRate "UIS ECU: net cell rx rate";
CM_ SG_ 1056 UIS_netCellRxCount "UIS ECU: net cell rx count";
CM_ SG_ 1056 UIS_navServiceError "Reports the value of the navigation service error.";
CM_ SG_ 1056 UIS_navAudioVolume "Navigation audio volume level";
CM_ SG_ 1056 UIS_muteNavVolume "Mute state of the navigation audio";
CM_ SG_ 1056 UIS_mounterdState "UIS ECU: mounterd state";
CM_ SG_ 1056 UIS_mounterdMountCountTotal "UIS ECU: mounterd mount count total";
CM_ SG_ 1056 UIS_mounterdFrontHubDisconnected "UIS ECU: mounterd front hub disconnected";
CM_ SG_ 1056 UIS_mounterdFrontHubConnected "UIS ECU: mounterd front hub connected";
CM_ SG_ 1056 UIS_mounterdFilesystemCountFat32 "UIS ECU: mounterd filesystem count fat32";
CM_ SG_ 1056 UIS_mounterdFilesystemCountExt4 "UIS ECU: mounterd filesystem count ext4";
CM_ SG_ 1056 UIS_mounterdFilesystemCountExt3 "UIS ECU: mounterd filesystem count ext3";
CM_ SG_ 1056 UIS_mounterdFilesystemCountExfat "UIS ECU: mounterd filesystem count exfat";
CM_ SG_ 1056 UIS_mounterdEncryptionCapacityGB "UIS ECU: mounterd encryption capacity GB";
CM_ SG_ 1056 UIS_mounterdDeviceCount "UIS ECU: mounterd device count";
CM_ SG_ 1056 UIS_mounterdDashcamCapacityGB "UIS ECU: mounterd dashcam capacity GB";
CM_ SG_ 1056 UIS_modemECallppAvail "Reports whether eCall++ is enabled and is running on Telematics Control Unit (TCU).";
CM_ SG_ 1056 UIS_modemBusyActive "Reports whether the modem busy logic is requested to be active on the modem application processor.";
CM_ SG_ 1056 UIS_mirrorGeofenceActive "Folding mirror geofence active status";
CM_ SG_ 1056 UIS_mediaserveMemUsage "UIS ECU: mediaserve mem usage";
CM_ SG_ 1056 UIS_mediaserveCPUUsage "UIS ECU: mediaserve CPU usage";
CM_ SG_ 1056 UIS_mediaPlaybackStatus "Media Current Playback Status";
CM_ SG_ 1056 UIS_mediaNeedAuthToken "Indicates whether the media system needs a new authentication token.";
CM_ SG_ 1056 UIS_mediaImageCacheSize "UIS ECU: media image cache size";
CM_ SG_ 1056 UIS_mediaImageCacheCost "UIS ECU: media image cache cost";
CM_ SG_ 1056 UIS_limex8664MemUsage "UIS ECU: limex8664 mem usage";
CM_ SG_ 1056 UIS_limex8664CPUUsage "UIS ECU: limex8664 CPU usage";
CM_ SG_ 1056 UIS_inSuperchargerGeofence "Vehicle inside Supercharger Geofence";
CM_ SG_ 1056 UIS_igpuTemperature "UIS ECU: igpu temperature";
CM_ SG_ 1056 UIS_homelinkState "State of Homelink sate machine";
CM_ SG_ 1056 UIS_hicarServiceState "UIS ECU: hicar service state";
CM_ SG_ 1056 UIS_hicarEventCode "UIS ECU: hicar event code";
CM_ SG_ 1056 UIS_hicarErrorCode "UIS ECU: hicar error code";
CM_ SG_ 1056 UIS_hicarDataReceiveType "UIS ECU: hicar data receive type";
CM_ SG_ 1056 UIS_hicarConnectionState "UIS ECU: hicar connection state";
CM_ SG_ 1056 UIS_hicarCallState "UIS ECU: hicar call state";
CM_ SG_ 1056 UIS_hicarAudioTeardownState "UIS ECU: hicar audio teardown state";
CM_ SG_ 1056 UIS_hicarAudioSetupState "UIS ECU: hicar audio setup state";
CM_ SG_ 1056 UIS_hermesdynamicMemUsage "UIS ECU: hermesdynamic mem usage";
CM_ SG_ 1056 UIS_hermesdynamicCPUUsage "UIS ECU: hermesdynamic CPU usage";
CM_ SG_ 1056 UIS_hermesclientMemUsage "UIS ECU: hermesclient mem usage";
CM_ SG_ 1056 UIS_hermesclientCPUUsage "UIS ECU: hermesclient CPU usage";
CM_ SG_ 1056 UIS_headsetPairResult "Bluetooth headset pairing result";
CM_ SG_ 1056 UIS_headsetConnectionState "Bluetooth headset connection state";
CM_ SG_ 1056 UIS_gtwSocUartTxStatTimeouts "UIS ECU: gtw soc uart tx stat timeouts";
CM_ SG_ 1056 UIS_gtwSocUartTxStatPackets "UIS ECU: gtw soc uart tx stat packets";
CM_ SG_ 1056 UIS_gtwSocUartTxStatNacks "UIS ECU: gtw soc uart tx stat nacks";
CM_ SG_ 1056 UIS_gtwSocUartTxStatBadTooBig "UIS ECU: gtw soc uart tx stat bad too big";
CM_ SG_ 1056 UIS_gtwSocUartTxStatAnsMismatch "UIS ECU: gtw soc uart tx stat ans mismatch";
CM_ SG_ 1056 UIS_gtwSocUartRxStatValidPackets "UIS ECU: gtw soc uart rx stat valid packets";
CM_ SG_ 1056 UIS_gtwSocUartRxStatUnhandled "UIS ECU: gtw soc uart rx stat unhandled";
CM_ SG_ 1056 UIS_gtwSocUartRxStatMsgErr "UIS ECU: gtw soc uart rx stat msg err";
CM_ SG_ 1056 UIS_gtwSocUartRxStatHeartbeats "UIS ECU: gtw soc uart rx stat heartbeats";
CM_ SG_ 1056 UIS_gtwSocUartRxStatHandleErr "UIS ECU: gtw soc uart rx stat handle err";
CM_ SG_ 1056 UIS_gtwSocUartRxStatBadTooSmall "UIS ECU: gtw soc uart rx stat bad too small";
CM_ SG_ 1056 UIS_gtwSocUartRxStatBadTooBig "UIS ECU: gtw soc uart rx stat bad too big";
CM_ SG_ 1056 UIS_gtwSocUartRxStatBadChecksum "UIS ECU: gtw soc uart rx stat bad checksum";
CM_ SG_ 1056 UIS_gpsmanagerMemUsage "gpsManager's Resident Memory usage in MB";
CM_ SG_ 1056 UIS_gpsmanagerCPUUsage "gpsManager's CPU usage in CPU usage %";
CM_ SG_ 1056 UIS_godot_TIME_PROCESS "UIS ECU: godot TIME PROCESS";
CM_ SG_ 1056 UIS_godot_TIME_FPS "UIS ECU: godot TIME FPS";
CM_ SG_ 1056 UIS_godot_MEMORY_STATIC "UIS ECU: godot MEMORY STATIC";
CM_ SG_ 1056 UIS_godot_MEMORY_DYNAMIC "UIS ECU: godot MEMORY DYNAMIC";
CM_ SG_ 1056 UIS_godotMemUsage "UIS ECU: godot mem usage";
CM_ SG_ 1056 UIS_godotCPUUsage "UIS ECU: godot CPU usage";
CM_ SG_ 1056 UIS_firmwareReleaseScope "UIS ECU: firmware release scope";
CM_ SG_ 1056 UIS_featureSuperchargingEnabled "Reports the Supercharging enabled feature status.";
CM_ SG_ 1056 UIS_estimatedOccupancyCount "UIS ECU: estimated occupancy count";
CM_ SG_ 1056 UIS_embeddedGameState "UIS ECU: embedded game state";
CM_ SG_ 1056 UIS_embeddedGameName "UIS ECU: embedded game name";
CM_ SG_ 1056 UIS_dynamicTriggersTelemetryServ "UIS ECU: dynamic triggers telemetry service state";
CM_ SG_ 1056 UIS_dynamicTriggersOutputManager "UIS ECU: dynamic triggers output manager service state";
CM_ SG_ 1056 UIS_dynamicTriggersHRLServiceSta "UIS ECU: dynamic triggers HRL service state";
CM_ SG_ 1056 UIS_dynamicTriggersCampaignState "UIS ECU: dynamic triggers campaign state; raw 0 = signal not available (SNA)";
CM_ SG_ 1056 UIS_dumTclipUploadState "UIS ECU: dum tclip upload state";
CM_ SG_ 1056 UIS_dumTclipUploadActive "UIS ECU: dum tclip upload active";
CM_ SG_ 1056 UIS_dumTclipTransferCount "UIS ECU: dum tclip transfer count";
CM_ SG_ 1056 UIS_dumTclipSuccessfulUploadCoun "UIS ECU: dum tclip successful upload count";
CM_ SG_ 1056 UIS_dumTclipClipCount "UIS ECU: dum tclip clip count";
CM_ SG_ 1056 UIS_dmRearTouchDeviceExists "Reports status of rear display power state.";
CM_ SG_ 1056 UIS_dmRearPowerState "Logs rear display power state status";
CM_ SG_ 1056 UIS_dmRearLinkCheckOk "Logs whether rear display-hardware-init was successful";
CM_ SG_ 1056 UIS_dmRearEnabled "Rear display is enabled";
CM_ SG_ 1056 UIS_dmRearConnected "Rear display is connected";
CM_ SG_ 1056 UIS_dmRearBacklightPowerLevel "UIS ECU: dm rear backlight power level";
CM_ SG_ 1056 UIS_dmRearBacklightNits "UIS ECU: dm rear backlight nits";
CM_ SG_ 1056 UIS_dmRearBacklightFault "UIS ECU: dm rear backlight fault";
CM_ SG_ 1056 UIS_dmRearBacklightDutyCycle "Logs rear backlight duty cycle status";
CM_ SG_ 1056 UIS_dmRearBacklightDevExists "Logs whether rear backlight device exists and was successfully detected";
CM_ SG_ 1056 UIS_dmRearAsilStatusMsb "UIS ECU: dm rear asil status msb";
CM_ SG_ 1056 UIS_dmRearAsilStatusLsb "UIS ECU: dm rear asil status lsb";
CM_ SG_ 1056 UIS_dmIcuTouchIrqCount "UIS ECU: dm icu touch irq count";
CM_ SG_ 1056 UIS_dmIcuPowerState "Logs cluster display power state status";
CM_ SG_ 1056 UIS_dmIcuLinkCheckOk "Logs whether cluster display-hardware-init was successful";
CM_ SG_ 1056 UIS_dmIcuEnabled "Cluster display is enabled";
CM_ SG_ 1056 UIS_dmIcuConnected "Cluster display is connected";
CM_ SG_ 1056 UIS_dmIcuBacklightPowerLevel "UIS ECU: dm icu backlight power level";
CM_ SG_ 1056 UIS_dmIcuBacklightNits "UIS ECU: dm icu backlight nits";
CM_ SG_ 1056 UIS_dmIcuBacklightFault "UIS ECU: dm icu backlight fault";
CM_ SG_ 1056 UIS_dmIcuBacklightDutyCycle "Logs cluster backlight duty cycle status";
CM_ SG_ 1056 UIS_dmIcuBacklightDevExists "Logs whether cluster backlight device exists and was successfully detected";
CM_ SG_ 1056 UIS_dmIcuAsilShortFlag "UIS ECU: dm icu asil short flag";
CM_ SG_ 1056 UIS_dmIcuAsilResumeFlag "UIS ECU: dm icu asil resume flag";
CM_ SG_ 1056 UIS_dmIcuAsilOpenFlag "UIS ECU: dm icu asil open flag";
CM_ SG_ 1056 UIS_dmIcuAsilFirmwareStatus "UIS ECU: dm icu asil firmware status";
CM_ SG_ 1056 UIS_dmGatewayLinkWedged "Indicates whether the center display gateway link is stuck.";
CM_ SG_ 1056 UIS_dmCenterTouchIrqCount "UIS ECU: dm center touch irq count";
CM_ SG_ 1056 UIS_dmCenterTouchDeviceExists "Detects whether the center display touch input device is present.";
CM_ SG_ 1056 UIS_dmCenterSOsdVideoCrcData "UIS ECU: dm center s osd video crc data";
CM_ SG_ 1056 UIS_dmCenterSOsdExactCrcCheck "UIS ECU: dm center s osd exact crc check";
CM_ SG_ 1056 UIS_dmCenterPowerState "Logs center display power state status";
CM_ SG_ 1056 UIS_dmCenterOsdDisplayedState "Reports the center display On-Screen Display (OSD) shown state.";
CM_ SG_ 1056 UIS_dmCenterOsdDayNightState "UIS ECU: dm center osd day night state";
CM_ SG_ 1056 UIS_dmCenterModeSettingStatus "UIS ECU: dm center mode setting status";
CM_ SG_ 1056 UIS_dmCenterMOsdVideoCrcData "UIS ECU: dm center m osd video crc data";
CM_ SG_ 1056 UIS_dmCenterMOsdExactCrcCheck "UIS ECU: dm center m osd exact crc check";
CM_ SG_ 1056 UIS_dmCenterLinkCheckOk "Logs whether center display-hardware-init was successful";
CM_ SG_ 1056 UIS_dmCenterEnabled "Center display is enabled";
CM_ SG_ 1056 UIS_dmCenterConnected "Center display is connected";
CM_ SG_ 1056 UIS_dmCenterBacklightPowerLevel "Logs backlight power level for center display";
CM_ SG_ 1056 UIS_dmCenterBacklightNits "UIS ECU: dm center backlight nits";
CM_ SG_ 1056 UIS_dmCenterBacklightFault "UIS ECU: dm center backlight fault";
CM_ SG_ 1056 UIS_dmCenterBacklightDutyCycle "Logs center backlight duty cycle status";
CM_ SG_ 1056 UIS_dmCenterBacklightDevExists "Logs whether center backlight device exists and was successfully detected";
CM_ SG_ 1056 UIS_dmCenterBacklightControlDefe "Indicates whether the center display backlight request to the gateway was deferred to the User Datagram Protocol Application Programming Interface (UDP API) or converged within 1 second.";
CM_ SG_ 1056 UIS_dmCenterAsilShortFlag "UIS ECU: dm center asil short flag";
CM_ SG_ 1056 UIS_dmCenterAsilResumeFlag "UIS ECU: dm center asil resume flag";
CM_ SG_ 1056 UIS_dmCenterAsilOpenFlag "UIS ECU: dm center asil open flag";
CM_ SG_ 1056 UIS_dmCenterAsilFirmwareStatus "UIS ECU: dm center asil firmware status";
CM_ SG_ 1056 UIS_dmCenterAsilCalibrationSync "UIS ECU: dm center asil calibration sync";
CM_ SG_ 1056 UIS_dgpuTemperature "Current temperature reported for dgpu";
CM_ SG_ 1056 UIS_developerMode "UIS ECU: developer mode";
CM_ SG_ 1056 UIS_dashcamviewerMemUsage "dashcamViewer's Resident Memory usage in MB";
CM_ SG_ 1056 UIS_dashcamviewerCPUUsage "dashcamViewer's CPU usage in CPU usage %";
CM_ SG_ 1056 UIS_dashcamTransferTimeMs "UIS ECU: dashcam transfer time ms";
CM_ SG_ 1056 UIS_dashcamTransferSizeMB "UIS ECU: dashcam transfer size MB";
CM_ SG_ 1056 UIS_dashcamTransferRateMBps "UIS ECU: dashcam transfer rate m bps";
CM_ SG_ 1056 UIS_dashcamTransferFileCount "UIS ECU: dashcam transfer file count";
CM_ SG_ 1056 UIS_dashcamTransferCount "UIS ECU: dashcam transfer count";
CM_ SG_ 1056 UIS_dashcamStorageState "Internal state of the dashcam storage";
CM_ SG_ 1056 UIS_dashcamStorageSentryMB "Dashcam USB storage used by Sentry Clips in MB";
CM_ SG_ 1056 UIS_dashcamStorageSavedMB "Dashcam USB storage used by Saved Clips in MB";
CM_ SG_ 1056 UIS_dashcamStorageRecentMB "Dashcam USB storage used by Recent Clips in MB";
CM_ SG_ 1056 UIS_dashcamStorageAvailableMB "Dashcam USB storage that is Available in MB";
CM_ SG_ 1056 UIS_dashcamState "Internal state for the dashcam state machine";
CM_ SG_ 1056 UIS_dashcamSavedToSentryCount "UIS ECU: dashcam saved to sentry count";
CM_ SG_ 1056 UIS_dashcamSavedToSavedCount "UIS ECU: dashcam saved to saved count";
CM_ SG_ 1056 UIS_dashcamSavedToOnboardCount "UIS ECU: dashcam saved to onboard count";
CM_ SG_ 1056 UIS_dashcamOnboardTransferCount "UIS ECU: dashcam onboard transfer count";
CM_ SG_ 1056 UIS_dashcamOnboardSavePressCount "UIS ECU: dashcam onboard save press count";
CM_ SG_ 1056 UIS_dashcamOnboardMB "UIS ECU: dashcam onboard MB";
CM_ SG_ 1056 UIS_dashcamOnboardAvailableMB "UIS ECU: dashcam onboard available MB";
CM_ SG_ 1056 UIS_dasAutonomyControlMessageMia "UIS ECU: das autonomy control message mia in driverless takeover";
CM_ SG_ 1056 UIS_cpuTemperature "Current temperature reported for cpu";
CM_ SG_ 1056 UIS_connectedToInternet "UIS ECU: connected to internet";
CM_ SG_ 1056 UIS_compositorRenderMinRenderTim "UIS ECU: compositor render min render time";
CM_ SG_ 1056 UIS_compositorRenderMinFrameTime "UIS ECU: compositor render min frame time";
CM_ SG_ 1056 UIS_compositorRenderMaxRenderTim "UIS ECU: compositor render max render time";
CM_ SG_ 1056 UIS_compositorRenderMaxFrameTime "UIS ECU: compositor render max frame time";
CM_ SG_ 1056 UIS_compositorRenderGpuPercentag "UIS ECU: compositor render gpu percentage";
CM_ SG_ 1056 UIS_compositorRenderFrameRate "UIS ECU: compositor render frame rate";
CM_ SG_ 1056 UIS_compositorRenderFrameCount "UIS ECU: compositor render frame count";
CM_ SG_ 1056 UIS_compositorRenderAvgRenderTim "UIS ECU: compositor render avg render time";
CM_ SG_ 1056 UIS_compositorFrameMonitorState "UIS ECU: compositor frame monitor state";
CM_ SG_ 1056 UIS_cobaltlinuxMemUsage "UIS ECU: cobaltlinux mem usage";
CM_ SG_ 1056 UIS_cobaltlinuxCPUUsage "UIS ECU: cobaltlinux CPU usage";
CM_ SG_ 1056 UIS_clusterMemUsage "cluster's Resident Memory usage in MB";
CM_ SG_ 1056 UIS_clusterMeanFPS "UIS ECU: cluster mean FPS";
CM_ SG_ 1056 UIS_clusterMaxFrametime "UIS ECU: cluster max frametime";
CM_ SG_ 1056 UIS_clusterFramesOver200Ms "UIS ECU: cluster frames over200 ms";
CM_ SG_ 1056 UIS_clusterFramesOver100Ms "UIS ECU: cluster frames over100 ms";
CM_ SG_ 1056 UIS_clusterDisplayState "Reports the instrument cluster display state.";
CM_ SG_ 1056 UIS_clusterCPUUsage "cluster's CPU usage in CPU usage %";
CM_ SG_ 1056 UIS_chromiumadapterMemUsage "UIS ECU: chromiumadapter mem usage";
CM_ SG_ 1056 UIS_chromiumadapterCPUUsage "UIS ECU: chromiumadapter CPU usage";
CM_ SG_ 1056 UIS_chargeOnSolarNoChargeReason "Reason car is not charging on solar";
CM_ SG_ 1056 UIS_chargeLocationId "Privacy-respecting region identifier for charge location (1.1km accuracy, requires user consent via Software > Controls > Data Sharing)";
CM_ SG_ 1056 UIS_ceruleanx8664MemUsage "UIS ECU: ceruleanx8664 mem usage";
CM_ SG_ 1056 UIS_ceruleanx8664CPUUsage "UIS ECU: ceruleanx8664 CPU usage";
CM_ SG_ 1056 UIS_centerDisplayState "Reports the center display state.";
CM_ SG_ 1056 UIS_centerDisplayEvent "Reports the events that cause center display state transitions.";
CM_ SG_ 1056 UIS_centerDispAsilB_msb "UIS ECU: center disp asil b msb";
CM_ SG_ 1056 UIS_centerDispAsilB_lsb "UIS ECU: center disp asil b lsb";
CM_ SG_ 1056 UIS_centerDispAsilA_msb "UIS ECU: center disp asil a msb";
CM_ SG_ 1056 UIS_centerDispAsilA_lsb "UIS ECU: center disp asil a lsb";
CM_ SG_ 1056 UIS_cellularLinkManagerState "CellLink Manager state";
CM_ SG_ 1056 UIS_cellularConnectivityStatus "Reports the abstracted status of overall connectivity on the infotainment.";
CM_ SG_ 1056 UIS_carAssistState "Car Assist State";
CM_ SG_ 1056 UIS_carAssistSessionCount "Car Assist Session Count";
CM_ SG_ 1056 UIS_carAssistMicMuted "Reports whether the car assist microphone is muted or unmuted.";
CM_ SG_ 1056 UIS_carAssistMicAlsaRms "Monitors the car assist microphone Advanced Linux Sound Architecture (ALSA) Root Mean Squared (RMS).";
CM_ SG_ 1056 UIS_carAssistErrorCode "Car Assist Error Code";
CM_ SG_ 1056 UIS_cameraSelectableRenderState "Indicates if the touchscreen UI software has composited at least one new selectable stream camera window frame.";
CM_ SG_ 1056 UIS_cameraSelectablePipeline "Reports the selectable stream camera pipeline state.";
CM_ SG_ 1056 UIS_cameraSelectablePacketState "Indicates if Infotainment detects selectable stream camera UDP packets from Autopilot.";
CM_ SG_ 1056 UIS_cameraRearViewStreamMissing "UIS ECU: camera rear view stream missing";
CM_ SG_ 1056 UIS_cameraRearViewRenderState "Indicates if the touchscreen UI software has composited at least one new rear view camera window frame.";
CM_ SG_ 1056 UIS_cameraRearViewPopup "UIS ECU: camera rear view popup";
CM_ SG_ 1056 UIS_cameraRearViewPipeline "UIS ECU: camera rear view pipeline";
CM_ SG_ 1056 UIS_cameraRearViewPacketState "Indicates if Infotainment detects rear view camera UDP packets from Autopilot.";
CM_ SG_ 1056 UIS_cameraRRepeaterStreamMissing "Signal representing if left repeater camera stream is active within videod";
CM_ SG_ 1056 UIS_cameraRRepeaterRenderState "Indicates if the touchscreen UI software has composited at least one new right repeater camera window frame.";
CM_ SG_ 1056 UIS_cameraRRepeaterPopup "Right repeater camera popup state";
CM_ SG_ 1056 UIS_cameraRRepeaterPipeline "Right repeater videod pipeline state";
CM_ SG_ 1056 UIS_cameraRRepeaterPacketState "Indicates if Infotainment detects right repeater camera UDP packets from Autopilot.";
CM_ SG_ 1056 UIS_cameraRRepeaterMaxFrametime "UIS ECU: camera r repeater max frametime";
CM_ SG_ 1056 UIS_cameraRRepeaterLateFrames "UIS ECU: camera r repeater late frames";
CM_ SG_ 1056 UIS_cameraRRepeaterFramerate "UIS ECU: camera r repeater framerate";
CM_ SG_ 1056 UIS_cameraRDownwardRenderState "Indicates if the touchscreen UI software has composited at least one new right downward camera window frame.";
CM_ SG_ 1056 UIS_cameraRDownwardPipeline "UIS ECU: camera r downward pipeline";
CM_ SG_ 1056 UIS_cameraRDownwardPacketState "Indicates if Infotainment detects right downward camera UDP packets from Autopilot.";
CM_ SG_ 1056 UIS_cameraLRepeaterStreamMissing "Signal representing if left repeater camera stream is active within videod";
CM_ SG_ 1056 UIS_cameraLRepeaterRenderState "Indicates if the touchscreen UI software has composited at least one new left repeater camera window frame.";
CM_ SG_ 1056 UIS_cameraLRepeaterPopup "Left repeater camera popup state";
CM_ SG_ 1056 UIS_cameraLRepeaterPipeline "Left repeater videod pipeline state";
CM_ SG_ 1056 UIS_cameraLRepeaterPacketState "Indicates if Infotainment detects left repeater camera UDP packets from Autopilot.";
CM_ SG_ 1056 UIS_cameraLRepeaterMaxFrametime "UIS ECU: camera l repeater max frametime";
CM_ SG_ 1056 UIS_cameraLRepeaterLateFrames "UIS ECU: camera l repeater late frames";
CM_ SG_ 1056 UIS_cameraLRepeaterFramerate "UIS ECU: camera l repeater framerate";
CM_ SG_ 1056 UIS_cameraLDownwardRenderState "Indicates if the touchscreen UI software has composited at least one new left downward camera window frame.";
CM_ SG_ 1056 UIS_cameraLDownwardPipeline "UIS ECU: camera l downward pipeline";
CM_ SG_ 1056 UIS_cameraLDownwardPacketState "Indicates if Infotainment detects left downward camera UDP packets from Autopilot.";
CM_ SG_ 1056 UIS_cameraFrontStreamMissing "UIS ECU: camera front stream missing";
CM_ SG_ 1056 UIS_cameraFrontRenderState "Indicates if the touchscreen UI software has composited at least one new front fascia camera window frame.";
CM_ SG_ 1056 UIS_cameraFrontPopup "UIS ECU: camera front popup";
CM_ SG_ 1056 UIS_cameraFrontPipeline "UIS ECU: camera front pipeline";
CM_ SG_ 1056 UIS_cameraFrontPacketState "Indicates if Infotainment detects front fascia camera UDP packets from Autopilot.";
CM_ SG_ 1056 UIS_cameraBackupStreamQuality "UIS ECU: camera backup stream quality";
CM_ SG_ 1056 UIS_cameraBackupStreamMissing "Signal representing if backup camera stream is active within videod";
CM_ SG_ 1056 UIS_cameraBackupRenderState "Indicates if the touchscreen UI software has composited at least one new backup camera window frame.";
CM_ SG_ 1056 UIS_cameraBackupPopup "Reports the backup camera popup state.";
CM_ SG_ 1056 UIS_cameraBackupPipeline "Reports the backup camera video pipeline state.";
CM_ SG_ 1056 UIS_cameraBackupPacketState "Indicates if Infotainment detects backup camera UDP packets from Autopilot.";
CM_ SG_ 1056 UIS_cameraBackupMaxFrametime "UIS ECU: camera backup max frametime";
CM_ SG_ 1056 UIS_pmSuspendHookIndex "UIS ECU: pm suspend hook index";
CM_ SG_ 1056 UIS_cameraBackupLateFrames "UIS ECU: camera backup late frames";
CM_ SG_ 1056 UIS_cameraBackupFramerate "Reports the backup camera framerate.";
CM_ SG_ 1056 UIS_camBackupDecodeMinFrametime "UIS ECU: cam backup decode min frametime";
CM_ SG_ 1056 UIS_camBackupDecodeMaxFrametime "UIS ECU: cam backup decode max frametime";
CM_ SG_ 1056 UIS_camBackupDecodeFramecount "UIS ECU: cam backup decode framecount";
CM_ SG_ 1056 UIS_camBackupDecodeAvgFrametime "UIS ECU: cam backup decode avg frametime";
CM_ SG_ 1056 UIS_bootCount "UIS ECU: boot count";
CM_ SG_ 1056 UIS_boardTemperature "Current temperature reported for board";
CM_ SG_ 1056 UIS_bluetoothState "Reports bluetooth state.";
CM_ SG_ 1056 UIS_bluetoothStackState "Bluetooth stack state";
CM_ SG_ 1056 UIS_bluetoothStackRearState "Bluetooth rear stack state";
CM_ SG_ 1056 UIS_bluetoothPairResult "Bluetooth pairing result";
CM_ SG_ 1056 UIS_bluetoothMemUsage "Reports the Bluetooth process resident memory usage in megabytes.";
CM_ SG_ 1056 UIS_bluetoothConnectionState "Reports the Bluetooth connection state.";
CM_ SG_ 1056 UIS_bluetoothCPUUsage "Reports the Bluetooth process Central Processing Unit (CPU) usage percentage.";
CM_ SG_ 1056 UIS_bluetoothAutoconnectAttempts "Reports the number of Bluetooth auto-connect attempts for the most recent connection cycle.";
CM_ SG_ 1056 UIS_bluetoothAutoconnectActive "Indicates that Bluetooth auto-connect is active.";
CM_ SG_ 1056 UIS_bluetoothAutoConnectionState "Reports the Bluetooth auto-connection state.";
CM_ SG_ 1056 UIS_bifrostOdinEngineUp "Signal reported by UIS ECU";
CM_ SG_ 1056 UIS_bifrostOdinEngineRequests "Signal reported by UIS ECU";
CM_ SG_ 1056 UIS_bifrostMemUsage "UIS ECU: bifrost mem usage";
CM_ SG_ 1056 UIS_bifrostCPUUsage "UIS ECU: bifrost CPU usage";
CM_ SG_ 1056 UIS_backlightUserRequest "Reports the Graphical User Interface (GUI) backlight user request value.";
CM_ SG_ 1056 UIS_audioVolumeLevel "User facing volume level";
CM_ SG_ 1056 UIS_audioType "Shows which audio amplifier type is currently configured";
CM_ SG_ 1056 UIS_audioState "Shows the state of the audio system";
CM_ SG_ 1056 UIS_audioSource "Shows which internal audio source is currently active";
CM_ SG_ 1056 UIS_audioPWSGain "Reports the pedestrian warning system volume in decibels.";
CM_ SG_ 1056 UIS_audioMediaPlaying "Shows which media source is currently being played";
CM_ SG_ 1056 UIS_audioMediaBrowsing "Shows which media source is currently being viewed";
CM_ SG_ 1056 UIS_audioA2BRediscoveryCount "Shows the count of a2b rediscoveries that have occurred";
CM_ SG_ 1056 UIS_apeHardwareMinorVersion "APE hardware minor version from device tree";
CM_ SG_ 1056 UIS_amdSocPkgPower "UIS ECU: amd soc pkg power";
CM_ SG_ 1056 UIS_activeAppView "Shows the currently displayed app";
CM_ SG_ 1056 UIS_CamViewerServiceEnabled "Reports whether the cam-viewer service is enabled.";
CM_ BO_ 979 "Touchscreen user interface computer message: airbag cutoff status";
CM_ SG_ 979 UI_airbagCutoffSwState "Reports the front passenger airbag cutoff switch request; raw 2 = signal not available (SNA)";
CM_ SG_ 979 UI_warningIndicatorStatus "Touchscreen user interface computer: warning indicator status; raw 3 = signal not available (SNA)";
BA_DEF_ BO_ "GenMsgCycleTime" INT 0 3600000;
BA_DEF_ BO_ "GenMsgSendType" ENUM "Cyclic","NotUsed","NotUsed","NotUsed","NotUsed","NotUsed","NotUsed","IfActive","NoMsgSendType","NotUsed";
BA_DEF_ BO_ "VFrameFormat" ENUM "StandardCAN","ExtendedCAN","reserved","J1939PG","reserved","reserved","reserved","reserved","reserved","reserved","reserved","reserved","reserved","reserved","StandardCAN_FD","ExtendedCAN_FD";
BA_DEF_ BO_ "CANFD_BRS" ENUM "0","1";
BA_DEF_ SG_ "GenSigSNA" STRING;
BA_DEF_ SG_ "SystemSignalLongSymbol" STRING;
BA_DEF_ SG_ "Confidence" ENUM "validated","plausible","layout-only","contradicted";
BA_DEF_DEF_ "GenMsgCycleTime" 0;
BA_DEF_DEF_ "GenMsgSendType" "NoMsgSendType";
BA_DEF_DEF_ "VFrameFormat" "StandardCAN";
BA_DEF_DEF_ "CANFD_BRS" "1";
BA_DEF_DEF_ "GenSigSNA" "";
BA_DEF_DEF_ "SystemSignalLongSymbol" "";
BA_DEF_DEF_ "Confidence" "layout-only";
BA_ "GenMsgCycleTime" BO_ 881 1000;
BA_ "GenMsgSendType" BO_ 881 0;
BA_ "GenMsgCycleTime" BO_ 1415 1000;
BA_ "GenMsgSendType" BO_ 1415 0;
BA_ "GenMsgCycleTime" BO_ 1414 1000;
BA_ "GenMsgSendType" BO_ 1414 0;
BA_ "GenMsgCycleTime" BO_ 1412 1000;
BA_ "GenMsgSendType" BO_ 1412 0;
BA_ "GenMsgCycleTime" BO_ 1159 1000;
BA_ "GenMsgSendType" BO_ 1159 0;
BA_ "GenMsgCycleTime" BO_ 1158 1000;
BA_ "GenMsgSendType" BO_ 1158 0;
BA_ "GenMsgCycleTime" BO_ 1155 1000;
BA_ "GenMsgSendType" BO_ 1155 0;
BA_ "GenMsgCycleTime" BO_ 979 500;
BA_ "GenMsgSendType" BO_ 979 0;
BA_ "Confidence" SG_ 1297 RCM_a117_eventDriveOrientation 1;
BA_ "Confidence" SG_ 1297 RCM_a117_eventIDFsignal 1;
BA_ "Confidence" SG_ 1297 RCM_a117_eventFrontLeftSeatbelt 1;
BA_ "Confidence" SG_ 1297 RCM_a117_eventFrontRightSeatbelt 1;
BA_ "Confidence" SG_ 1297 RCM_a117_eventVehicleSpeed 1;
BA_ "Confidence" SG_ 1297 RCM_a117_eventSteeringAngle 1;
BA_ "Confidence" SG_ 1297 RCM_a117_eventDriverBrakeApply 1;
BA_ "GenSigSNA" SG_ 1297 RCM_a117_eventDriverBrakeApply "3";
BA_ "Confidence" SG_ 1297 RCM_a117_eventAccelPedalPos 1;
BA_ "GenSigSNA" SG_ 1297 RCM_a117_eventAccelPedalPos "255";
BA_ "Confidence" SG_ 1297 RCM_a118_eventArmStatus 1;
BA_ "Confidence" SG_ 1297 RCM_a118_eventFactoryMode 1;
BA_ "Confidence" SG_ 1297 RCM_a118_eventDiagEnabled 1;
BA_ "Confidence" SG_ 1297 RCM_a118_eventDriveOrientation 1;
BA_ "Confidence" SG_ 1297 RCM_a118_eventIDFsignal 1;
BA_ "Confidence" SG_ 1297 RCM_a118_eventFrontLeftSeatbelt 1;
BA_ "Confidence" SG_ 1297 RCM_a118_eventFrontRightSeatbelt 1;
BA_ "Confidence" SG_ 1297 RCM_a118_eventVehicleSpeed 1;
BA_ "Confidence" SG_ 1297 RCM_a118_eventSteeringAngle 1;
BA_ "Confidence" SG_ 1297 RCM_a118_eventDriverBrakeApply 1;
BA_ "GenSigSNA" SG_ 1297 RCM_a118_eventDriverBrakeApply "3";
BA_ "Confidence" SG_ 1297 RCM_a118_eventAccelPedalPos 1;
BA_ "GenSigSNA" SG_ 1297 RCM_a118_eventAccelPedalPos "255";
BA_ "Confidence" SG_ 881 RCM_matrixIndex 1;
BA_ "Confidence" SG_ 1415 TCU2_tc10Version 0;
BA_ "GenSigSNA" SG_ 1415 TCU2_tc10Version "0";
BA_ "Confidence" SG_ 1413 TCU2_alertID 1;
BA_ "Confidence" SG_ 1413 TCU2_alertState 1;
BA_ "Confidence" SG_ 1413 TCU2_w012_DataRAT 1;
BA_ "Confidence" SG_ 1413 TCU2_w012_RSRP 1;
BA_ "Confidence" SG_ 1413 TCU2_w012_RSRQ 1;
BA_ "Confidence" SG_ 1413 TCU2_w012_AvgQueueUsage 1;
BA_ "Confidence" SG_ 1413 TCU2_w012_NSAAvailable 1;
BA_ "Confidence" SG_ 1413 TCU2_w013_DataRAT 1;
BA_ "Confidence" SG_ 1413 TCU2_w013_RSRP 1;
BA_ "Confidence" SG_ 1413 TCU2_w013_RSRQ 1;
BA_ "Confidence" SG_ 1413 TCU2_w013_AvgQueueUsage 1;
BA_ "Confidence" SG_ 1413 TCU2_w013_NSAAvailable 1;
BA_ "Confidence" SG_ 1412 TCU2_logMux 1;
BA_ "Confidence" SG_ 1412 TCU2_cpuTemp 0;
BA_ "Confidence" SG_ 1412 TCU2_cpuUsage 0;
BA_ "Confidence" SG_ 1412 TCU2_mdmCoreTemperature 0;
BA_ "Confidence" SG_ 1412 TCU2_availableMemory 0;
BA_ "Confidence" SG_ 1412 TCU2_pwm 0;
BA_ "Confidence" SG_ 1412 TCU2_pwmcap 0;
BA_ "Confidence" SG_ 1412 TCU2_totalResumes 0;
BA_ "Confidence" SG_ 1412 TCU2_mdmUplinkQueueSize 0;
BA_ "Confidence" SG_ 1412 TCU2_mdmRSRP 0;
BA_ "Confidence" SG_ 1412 TCU2_mdmSINR 0;
BA_ "Confidence" SG_ 1412 TCU2_mdmUplinkAllowedRate 0;
BA_ "Confidence" SG_ 1412 TCU2_mdmUplinkAvgRate 0;
BA_ "Confidence" SG_ 1412 TCU2_mdmServiceState 0;
BA_ "Confidence" SG_ 1412 TCU2_mdmIMSStatus 0;
BA_ "Confidence" SG_ 1412 TCU2_mdmSIMStatus 0;
BA_ "Confidence" SG_ 1412 TCU2_mdmBusyActive 0;
BA_ "GenSigSNA" SG_ 1412 TCU2_mdmBusyActive "4294967295";
BA_ "Confidence" SG_ 1412 TCU2_modemUptime 0;
BA_ "Confidence" SG_ 1412 TCU2_mdmDataRat 0;
BA_ "Confidence" SG_ 1412 TCU2_mdmDataCallStatus 0;
BA_ "Confidence" SG_ 1412 TCU2_mdmNSAAvailable 0;
BA_ "Confidence" SG_ 1412 TCU2_mdmPCIID 0;
BA_ "Confidence" SG_ 1412 TCU2_mdmMnc 0;
BA_ "Confidence" SG_ 1412 TCU2_mdmMcc 0;
BA_ "Confidence" SG_ 1412 TCU2_mdmTxKiloBytes 0;
BA_ "Confidence" SG_ 1412 TCU2_mdmDataCallTermReason 0;
BA_ "Confidence" SG_ 1412 TCU2_mdmDataCallTermCode 0;
BA_ "Confidence" SG_ 1412 TCU2_cellularSMState 0;
BA_ "Confidence" SG_ 1412 TCU2_tcuSMState 0;
BA_ "Confidence" SG_ 1412 TCU2_checkInternetFailCount 0;
BA_ "Confidence" SG_ 1412 TCU2_mdmBand 0;
BA_ "Confidence" SG_ 1412 TCU2_wakeSource 0;
BA_ "Confidence" SG_ 1159 TCU_tc10Version 0;
BA_ "GenSigSNA" SG_ 1159 TCU_tc10Version "0";
BA_ "Confidence" SG_ 1157 TCU_alertID 1;
BA_ "Confidence" SG_ 1157 TCU_alertState 1;
BA_ "Confidence" SG_ 1157 TCU_w012_DataRAT 1;
BA_ "Confidence" SG_ 1157 TCU_w012_RSRP 1;
BA_ "Confidence" SG_ 1157 TCU_w012_RSRQ 1;
BA_ "Confidence" SG_ 1157 TCU_w012_AvgQueueUsage 1;
BA_ "Confidence" SG_ 1157 TCU_w012_NSAAvailable 1;
BA_ "Confidence" SG_ 1157 TCU_w013_DataRAT 1;
BA_ "Confidence" SG_ 1157 TCU_w013_RSRP 1;
BA_ "Confidence" SG_ 1157 TCU_w013_RSRQ 1;
BA_ "Confidence" SG_ 1157 TCU_w013_AvgQueueUsage 1;
BA_ "Confidence" SG_ 1157 TCU_w013_NSAAvailable 1;
BA_ "Confidence" SG_ 1155 TCU_logMux 1;
BA_ "Confidence" SG_ 1155 TCU_cpuTemp 0;
BA_ "Confidence" SG_ 1155 TCU_cpuUsage 0;
BA_ "Confidence" SG_ 1155 TCU_mdmCoreTemperature 0;
BA_ "Confidence" SG_ 1155 TCU_availableMemory 0;
BA_ "Confidence" SG_ 1155 TCU_pwm 0;
BA_ "Confidence" SG_ 1155 TCU_pwmcap 0;
BA_ "Confidence" SG_ 1155 TCU_totalResumes 0;
BA_ "Confidence" SG_ 1155 TCU_mdmUplinkQueueSize 0;
BA_ "Confidence" SG_ 1155 TCU_mdmRSRP 0;
BA_ "Confidence" SG_ 1155 TCU_mdmSINR 0;
BA_ "Confidence" SG_ 1155 TCU_mdmUplinkAllowedRate 0;
BA_ "Confidence" SG_ 1155 TCU_mdmUplinkAvgRate 0;
BA_ "Confidence" SG_ 1155 TCU_mdmServiceState 0;
BA_ "Confidence" SG_ 1155 TCU_mdmIMSStatus 0;
BA_ "Confidence" SG_ 1155 TCU_mdmSIMStatus 0;
BA_ "Confidence" SG_ 1155 TCU_mdmBusyActive 0;
BA_ "GenSigSNA" SG_ 1155 TCU_mdmBusyActive "4294967295";
BA_ "Confidence" SG_ 1155 TCU_modemUptime 0;
BA_ "Confidence" SG_ 1155 TCU_mdmDataRat 0;
BA_ "Confidence" SG_ 1155 TCU_mdmDataCallStatus 0;
BA_ "Confidence" SG_ 1155 TCU_mdmNSAAvailable 0;
BA_ "Confidence" SG_ 1155 TCU_mdmPCIID 0;
BA_ "Confidence" SG_ 1155 TCU_mdmMnc 0;
BA_ "Confidence" SG_ 1155 TCU_mdmMcc 0;
BA_ "Confidence" SG_ 1155 TCU_mdmTxKiloBytes 0;
BA_ "Confidence" SG_ 1155 TCU_mdmDataCallTermReason 0;
BA_ "Confidence" SG_ 1155 TCU_mdmDataCallTermCode 0;
BA_ "Confidence" SG_ 1155 TCU_cellularSMState 0;
BA_ "Confidence" SG_ 1155 TCU_tcuSMState 0;
BA_ "Confidence" SG_ 1155 TCU_checkInternetFailCount 0;
BA_ "Confidence" SG_ 1155 TCU_mdmBand 0;
BA_ "Confidence" SG_ 1155 TCU_wakeSource 0;
BA_ "Confidence" SG_ 1603 UDS_ocs1pRequestData 1;
BA_ "Confidence" SG_ 1551 UDS_thcRequestData_H 1;
BA_ "Confidence" SG_ 1551 UDS_thcRequestData_L 1;
BA_ "Confidence" SG_ 1056 UIS_logMux 1;
BA_ "Confidence" SG_ 1056 UIS_wifiTemperature 0;
BA_ "Confidence" SG_ 1056 UIS_wifiStackState 0;
BA_ "Confidence" SG_ 1056 UIS_wifiStackReady 1;
BA_ "Confidence" SG_ 1056 UIS_wifiBars 0;
BA_ "Confidence" SG_ 1056 UIS_wifiAutoJoinLowRSSI 0;
BA_ "Confidence" SG_ 1056 UIS_valetMode 0;
BA_ "Confidence" SG_ 1056 UIS_uiQtCarUptime 0;
BA_ "Confidence" SG_ 1056 UIS_uiMeanFPS 0;
BA_ "Confidence" SG_ 1056 UIS_tunerVoltageOperation 0;
BA_ "Confidence" SG_ 1056 UIS_tunerVoltageAntenna2 0;
BA_ "Confidence" SG_ 1056 UIS_tunerVoltageAntenna1 0;
BA_ "Confidence" SG_ 1056 UIS_tunerCurrentAntenna2 0;
BA_ "Confidence" SG_ 1056 UIS_tunerCurrentAntenna1 0;
BA_ "Confidence" SG_ 1056 UIS_thermalResistance 1;
BA_ "Confidence" SG_ 1056 UIS_thermalProfile 1;
BA_ "GenSigSNA" SG_ 1056 UIS_thermalProfile "0";
BA_ "Confidence" SG_ 1056 UIS_testDriveMode 1;
BA_ "Confidence" SG_ 1056 UIS_teleopMinPacketDelta 1;
BA_ "Confidence" SG_ 1056 UIS_teleopMaxPacketDelta 1;
BA_ "Confidence" SG_ 1056 UIS_teleopAvgPacketDelta 1;
BA_ "Confidence" SG_ 1056 UIS_tegraModemManState 0;
BA_ "Confidence" SG_ 1056 UIS_systemWakeTime 0;
BA_ "Confidence" SG_ 1056 UIS_systemUptime 0;
BA_ "Confidence" SG_ 1056 UIS_suspensionGeofence 0;
BA_ "Confidence" SG_ 1056 UIS_superchargePaymentNeeded 0;
BA_ "Confidence" SG_ 1056 UIS_softwareUpdateState 1;
BA_ "Confidence" SG_ 1056 UIS_softwareUpdatePrimDownload 1;
BA_ "Confidence" SG_ 1056 UIS_softwareInstallPopupStatus 1;
BA_ "Confidence" SG_ 1056 UIS_sleepType 0;
BA_ "Confidence" SG_ 1056 UIS_sleepTime 0;
BA_ "Confidence" SG_ 1056 UIS_sleepState 0;
BA_ "Confidence" SG_ 1056 UIS_slackerLoginResult 0;
BA_ "Confidence" SG_ 1056 UIS_settingsAutoTurnSignal 1;
BA_ "Confidence" SG_ 1056 UIS_sentryState 0;
BA_ "Confidence" SG_ 1056 UIS_sentryNeedsNap 0;
BA_ "Confidence" SG_ 1056 UIS_sentryIncidentCount 0;
BA_ "Confidence" SG_ 1056 UIS_scheduledChargingMode 0;
BA_ "Confidence" SG_ 1056 UIS_scheduleChargeStartTime 0;
BA_ "Confidence" SG_ 1056 UIS_scheduleChargeEndTime 0;
BA_ "Confidence" SG_ 1056 UIS_remoteRequestType 0;
BA_ "Confidence" SG_ 1056 UIS_rearDisplayUserPresent 0;
BA_ "Confidence" SG_ 1056 UIS_rearDisplayState 0;
BA_ "Confidence" SG_ 1056 UIS_powerManagerState 0;
BA_ "GenSigSNA" SG_ 1056 UIS_powerManagerState "18";
BA_ "Confidence" SG_ 1056 UIS_polytopiax8664MemUsage 0;
BA_ "Confidence" SG_ 1056 UIS_polytopiax8664CPUUsage 0;
BA_ "Confidence" SG_ 1056 UIS_odinStatusCmdResult 1;
BA_ "Confidence" SG_ 1056 UIS_odinProcessState 1;
BA_ "Confidence" SG_ 1056 UIS_odinPeriodicTaskState 1;
BA_ "Confidence" SG_ 1056 UIS_odinListTasksCmdResult 1;
BA_ "Confidence" SG_ 1056 UIS_odinHrlUploadLimits 1;
BA_ "Confidence" SG_ 1056 UIS_odinHrlLogUploadState 1;
BA_ "Confidence" SG_ 1056 UIS_odinHermesConnectionState 1;
BA_ "Confidence" SG_ 1056 UIS_odinGatewayConnectionState 1;
BA_ "Confidence" SG_ 1056 UIS_odinFileSystemState 1;
BA_ "Confidence" SG_ 1056 UIS_odinEcuLogUploadState 1;
BA_ "Confidence" SG_ 1056 UIS_odinEcuLogForceTriggerUpload 1;
BA_ "SystemSignalLongSymbol" SG_ 1056 UIS_odinEcuLogForceTriggerUpload "UIS_odinEcuLogForceTriggerUploadState";
BA_ "Confidence" SG_ 1056 UIS_netWifiTxRate 1;
BA_ "Confidence" SG_ 1056 UIS_netWifiTxCount 1;
BA_ "Confidence" SG_ 1056 UIS_netWifiRxRate 1;
BA_ "Confidence" SG_ 1056 UIS_netWifiRxCount 1;
BA_ "Confidence" SG_ 1056 UIS_netEthTxRate 1;
BA_ "Confidence" SG_ 1056 UIS_netEthTxCount 1;
BA_ "Confidence" SG_ 1056 UIS_netEthRxRate 1;
BA_ "Confidence" SG_ 1056 UIS_netEthRxCount 1;
BA_ "Confidence" SG_ 1056 UIS_netCellTxRate 1;
BA_ "Confidence" SG_ 1056 UIS_netCellTxCount 1;
BA_ "Confidence" SG_ 1056 UIS_netCellRxRate 1;
BA_ "Confidence" SG_ 1056 UIS_netCellRxCount 1;
BA_ "Confidence" SG_ 1056 UIS_navServiceError 0;
BA_ "Confidence" SG_ 1056 UIS_navAudioVolume 0;
BA_ "Confidence" SG_ 1056 UIS_muteNavVolume 0;
BA_ "Confidence" SG_ 1056 UIS_mounterdState 1;
BA_ "Confidence" SG_ 1056 UIS_modemECallppAvail 0;
BA_ "Confidence" SG_ 1056 UIS_modemBusyActive 0;
BA_ "Confidence" SG_ 1056 UIS_mirrorGeofenceActive 0;
BA_ "Confidence" SG_ 1056 UIS_mediaPlaybackStatus 0;
BA_ "Confidence" SG_ 1056 UIS_mediaNeedAuthToken 0;
BA_ "Confidence" SG_ 1056 UIS_inSuperchargerGeofence 0;
BA_ "Confidence" SG_ 1056 UIS_homelinkState 0;
BA_ "Confidence" SG_ 1056 UIS_hicarEventCode 1;
BA_ "Confidence" SG_ 1056 UIS_hicarErrorCode 1;
BA_ "Confidence" SG_ 1056 UIS_hicarConnectionState 1;
BA_ "Confidence" SG_ 1056 UIS_hicarCallState 1;
BA_ "Confidence" SG_ 1056 UIS_hicarAudioTeardownState 1;
BA_ "Confidence" SG_ 1056 UIS_hicarAudioSetupState 1;
BA_ "Confidence" SG_ 1056 UIS_headsetPairResult 0;
BA_ "Confidence" SG_ 1056 UIS_headsetConnectionState 0;
BA_ "Confidence" SG_ 1056 UIS_gpsmanagerMemUsage 0;
BA_ "Confidence" SG_ 1056 UIS_gpsmanagerCPUUsage 0;
BA_ "Confidence" SG_ 1056 UIS_firmwareReleaseScope 1;
BA_ "Confidence" SG_ 1056 UIS_featureSuperchargingEnabled 0;
BA_ "Confidence" SG_ 1056 UIS_embeddedGameState 1;
BA_ "Confidence" SG_ 1056 UIS_embeddedGameName 1;
BA_ "Confidence" SG_ 1056 UIS_dynamicTriggersTelemetryServ 1;
BA_ "SystemSignalLongSymbol" SG_ 1056 UIS_dynamicTriggersTelemetryServ "UIS_dynamicTriggersTelemetryServiceState";
BA_ "Confidence" SG_ 1056 UIS_dynamicTriggersOutputManager 1;
BA_ "SystemSignalLongSymbol" SG_ 1056 UIS_dynamicTriggersOutputManager "UIS_dynamicTriggersOutputManagerServiceState";
BA_ "Confidence" SG_ 1056 UIS_dynamicTriggersHRLServiceSta 1;
BA_ "SystemSignalLongSymbol" SG_ 1056 UIS_dynamicTriggersHRLServiceSta "UIS_dynamicTriggersHRLServiceState";
BA_ "Confidence" SG_ 1056 UIS_dynamicTriggersCampaignState 1;
BA_ "GenSigSNA" SG_ 1056 UIS_dynamicTriggersCampaignState "0";
BA_ "Confidence" SG_ 1056 UIS_dumTclipUploadState 1;
BA_ "SystemSignalLongSymbol" SG_ 1056 UIS_dumTclipSuccessfulUploadCoun "UIS_dumTclipSuccessfulUploadCount";
BA_ "Confidence" SG_ 1056 UIS_dmRearTouchDeviceExists 0;
BA_ "Confidence" SG_ 1056 UIS_dmRearPowerState 0;
BA_ "Confidence" SG_ 1056 UIS_dmRearLinkCheckOk 0;
BA_ "Confidence" SG_ 1056 UIS_dmRearEnabled 0;
BA_ "Confidence" SG_ 1056 UIS_dmRearConnected 0;
BA_ "Confidence" SG_ 1056 UIS_dmRearBacklightPowerLevel 1;
BA_ "Confidence" SG_ 1056 UIS_dmRearBacklightDutyCycle 0;
BA_ "Confidence" SG_ 1056 UIS_dmRearBacklightDevExists 0;
BA_ "Confidence" SG_ 1056 UIS_dmIcuPowerState 0;
BA_ "Confidence" SG_ 1056 UIS_dmIcuLinkCheckOk 0;
BA_ "Confidence" SG_ 1056 UIS_dmIcuEnabled 0;
BA_ "Confidence" SG_ 1056 UIS_dmIcuConnected 0;
BA_ "Confidence" SG_ 1056 UIS_dmIcuBacklightPowerLevel 1;
BA_ "Confidence" SG_ 1056 UIS_dmIcuBacklightDutyCycle 0;
BA_ "Confidence" SG_ 1056 UIS_dmIcuBacklightDevExists 0;
BA_ "Confidence" SG_ 1056 UIS_dmIcuAsilResumeFlag 1;
BA_ "Confidence" SG_ 1056 UIS_dmIcuAsilFirmwareStatus 1;
BA_ "Confidence" SG_ 1056 UIS_dmGatewayLinkWedged 0;
BA_ "Confidence" SG_ 1056 UIS_dmCenterTouchDeviceExists 0;
BA_ "Confidence" SG_ 1056 UIS_dmCenterSOsdExactCrcCheck 1;
BA_ "Confidence" SG_ 1056 UIS_dmCenterPowerState 0;
BA_ "Confidence" SG_ 1056 UIS_dmCenterOsdDisplayedState 0;
BA_ "Confidence" SG_ 1056 UIS_dmCenterOsdDayNightState 1;
BA_ "Confidence" SG_ 1056 UIS_dmCenterModeSettingStatus 1;
BA_ "Confidence" SG_ 1056 UIS_dmCenterMOsdExactCrcCheck 1;
BA_ "Confidence" SG_ 1056 UIS_dmCenterLinkCheckOk 0;
BA_ "Confidence" SG_ 1056 UIS_dmCenterEnabled 0;
BA_ "Confidence" SG_ 1056 UIS_dmCenterConnected 0;
BA_ "Confidence" SG_ 1056 UIS_dmCenterBacklightPowerLevel 0;
BA_ "Confidence" SG_ 1056 UIS_dmCenterBacklightDutyCycle 0;
BA_ "Confidence" SG_ 1056 UIS_dmCenterBacklightDevExists 0;
BA_ "Confidence" SG_ 1056 UIS_dmCenterBacklightControlDefe 0;
BA_ "SystemSignalLongSymbol" SG_ 1056 UIS_dmCenterBacklightControlDefe "UIS_dmCenterBacklightControlDeferred";
BA_ "Confidence" SG_ 1056 UIS_dmCenterAsilResumeFlag 1;
BA_ "Confidence" SG_ 1056 UIS_dmCenterAsilFirmwareStatus 1;
BA_ "Confidence" SG_ 1056 UIS_dmCenterAsilCalibrationSync 1;
BA_ "Confidence" SG_ 1056 UIS_dgpuTemperature 0;
BA_ "Confidence" SG_ 1056 UIS_dashcamviewerMemUsage 0;
BA_ "Confidence" SG_ 1056 UIS_dashcamviewerCPUUsage 0;
BA_ "Confidence" SG_ 1056 UIS_dashcamStorageState 0;
BA_ "Confidence" SG_ 1056 UIS_dashcamStorageSentryMB 0;
BA_ "Confidence" SG_ 1056 UIS_dashcamStorageSavedMB 0;
BA_ "Confidence" SG_ 1056 UIS_dashcamStorageRecentMB 0;
BA_ "Confidence" SG_ 1056 UIS_dashcamStorageAvailableMB 0;
BA_ "Confidence" SG_ 1056 UIS_dashcamState 0;
BA_ "Confidence" SG_ 1056 UIS_dasAutonomyControlMessageMia 1;
BA_ "SystemSignalLongSymbol" SG_ 1056 UIS_dasAutonomyControlMessageMia "UIS_dasAutonomyControlMessageMiaInDriverlessTakeover";
BA_ "Confidence" SG_ 1056 UIS_cpuTemperature 0;
BA_ "SystemSignalLongSymbol" SG_ 1056 UIS_compositorRenderMinRenderTim "UIS_compositorRenderMinRenderTime";
BA_ "SystemSignalLongSymbol" SG_ 1056 UIS_compositorRenderMaxRenderTim "UIS_compositorRenderMaxRenderTime";
BA_ "SystemSignalLongSymbol" SG_ 1056 UIS_compositorRenderGpuPercentag "UIS_compositorRenderGpuPercentage";
BA_ "SystemSignalLongSymbol" SG_ 1056 UIS_compositorRenderAvgRenderTim "UIS_compositorRenderAvgRenderTime";
BA_ "Confidence" SG_ 1056 UIS_compositorFrameMonitorState 1;
BA_ "Confidence" SG_ 1056 UIS_clusterMemUsage 0;
BA_ "Confidence" SG_ 1056 UIS_clusterDisplayState 0;
BA_ "Confidence" SG_ 1056 UIS_clusterCPUUsage 0;
BA_ "Confidence" SG_ 1056 UIS_chargeOnSolarNoChargeReason 0;
BA_ "Confidence" SG_ 1056 UIS_chargeLocationId 0;
BA_ "Confidence" SG_ 1056 UIS_centerDisplayState 0;
BA_ "Confidence" SG_ 1056 UIS_centerDisplayEvent 0;
BA_ "Confidence" SG_ 1056 UIS_cellularLinkManagerState 0;
BA_ "Confidence" SG_ 1056 UIS_cellularConnectivityStatus 0;
BA_ "Confidence" SG_ 1056 UIS_carAssistState 0;
BA_ "Confidence" SG_ 1056 UIS_carAssistSessionCount 0;
BA_ "Confidence" SG_ 1056 UIS_carAssistMicMuted 0;
BA_ "Confidence" SG_ 1056 UIS_carAssistMicAlsaRms 0;
BA_ "Confidence" SG_ 1056 UIS_carAssistErrorCode 0;
BA_ "Confidence" SG_ 1056 UIS_cameraSelectableRenderState 0;
BA_ "Confidence" SG_ 1056 UIS_cameraSelectablePipeline 0;
BA_ "Confidence" SG_ 1056 UIS_cameraSelectablePacketState 0;
BA_ "Confidence" SG_ 1056 UIS_cameraRearViewStreamMissing 1;
BA_ "Confidence" SG_ 1056 UIS_cameraRearViewRenderState 0;
BA_ "Confidence" SG_ 1056 UIS_cameraRearViewPopup 1;
BA_ "Confidence" SG_ 1056 UIS_cameraRearViewPipeline 1;
BA_ "Confidence" SG_ 1056 UIS_cameraRearViewPacketState 0;
BA_ "Confidence" SG_ 1056 UIS_cameraRRepeaterStreamMissing 0;
BA_ "Confidence" SG_ 1056 UIS_cameraRRepeaterRenderState 0;
BA_ "Confidence" SG_ 1056 UIS_cameraRRepeaterPopup 0;
BA_ "Confidence" SG_ 1056 UIS_cameraRRepeaterPipeline 0;
BA_ "Confidence" SG_ 1056 UIS_cameraRRepeaterPacketState 0;
BA_ "Confidence" SG_ 1056 UIS_cameraRDownwardRenderState 0;
BA_ "Confidence" SG_ 1056 UIS_cameraRDownwardPipeline 1;
BA_ "Confidence" SG_ 1056 UIS_cameraRDownwardPacketState 0;
BA_ "Confidence" SG_ 1056 UIS_cameraLRepeaterStreamMissing 0;
BA_ "Confidence" SG_ 1056 UIS_cameraLRepeaterRenderState 0;
BA_ "Confidence" SG_ 1056 UIS_cameraLRepeaterPopup 0;
BA_ "Confidence" SG_ 1056 UIS_cameraLRepeaterPipeline 0;
BA_ "Confidence" SG_ 1056 UIS_cameraLRepeaterPacketState 0;
BA_ "Confidence" SG_ 1056 UIS_cameraLDownwardRenderState 0;
BA_ "Confidence" SG_ 1056 UIS_cameraLDownwardPipeline 1;
BA_ "Confidence" SG_ 1056 UIS_cameraLDownwardPacketState 0;
BA_ "Confidence" SG_ 1056 UIS_cameraFrontStreamMissing 1;
BA_ "Confidence" SG_ 1056 UIS_cameraFrontRenderState 0;
BA_ "Confidence" SG_ 1056 UIS_cameraFrontPopup 1;
BA_ "Confidence" SG_ 1056 UIS_cameraFrontPipeline 1;
BA_ "Confidence" SG_ 1056 UIS_cameraFrontPacketState 0;
BA_ "Confidence" SG_ 1056 UIS_cameraBackupStreamQuality 1;
BA_ "Confidence" SG_ 1056 UIS_cameraBackupStreamMissing 0;
BA_ "Confidence" SG_ 1056 UIS_cameraBackupRenderState 0;
BA_ "Confidence" SG_ 1056 UIS_cameraBackupPopup 0;
BA_ "Confidence" SG_ 1056 UIS_cameraBackupPipeline 0;
BA_ "Confidence" SG_ 1056 UIS_cameraBackupPacketState 0;
BA_ "Confidence" SG_ 1056 UIS_pmSuspendHookIndex 1;
BA_ "Confidence" SG_ 1056 UIS_cameraBackupFramerate 0;
BA_ "Confidence" SG_ 1056 UIS_boardTemperature 0;
BA_ "Confidence" SG_ 1056 UIS_bluetoothState 0;
BA_ "Confidence" SG_ 1056 UIS_bluetoothStackState 0;
BA_ "Confidence" SG_ 1056 UIS_bluetoothStackRearState 0;
BA_ "Confidence" SG_ 1056 UIS_bluetoothPairResult 0;
BA_ "Confidence" SG_ 1056 UIS_bluetoothMemUsage 0;
BA_ "Confidence" SG_ 1056 UIS_bluetoothConnectionState 0;
BA_ "Confidence" SG_ 1056 UIS_bluetoothCPUUsage 0;
BA_ "Confidence" SG_ 1056 UIS_bluetoothAutoconnectAttempts 0;
BA_ "Confidence" SG_ 1056 UIS_bluetoothAutoconnectActive 0;
BA_ "Confidence" SG_ 1056 UIS_bluetoothAutoConnectionState 0;
BA_ "Confidence" SG_ 1056 UIS_backlightUserRequest 0;
BA_ "Confidence" SG_ 1056 UIS_audioVolumeLevel 0;
BA_ "Confidence" SG_ 1056 UIS_audioType 0;
BA_ "Confidence" SG_ 1056 UIS_audioState 0;
BA_ "Confidence" SG_ 1056 UIS_audioSource 0;
BA_ "Confidence" SG_ 1056 UIS_audioPWSGain 0;
BA_ "Confidence" SG_ 1056 UIS_audioMediaPlaying 0;
BA_ "Confidence" SG_ 1056 UIS_audioMediaBrowsing 0;
BA_ "Confidence" SG_ 1056 UIS_audioA2BRediscoveryCount 0;
BA_ "Confidence" SG_ 1056 UIS_apeHardwareMinorVersion 0;
BA_ "Confidence" SG_ 1056 UIS_activeAppView 0;
BA_ "Confidence" SG_ 1056 UIS_CamViewerServiceEnabled 0;
BA_ "Confidence" SG_ 979 UI_airbagCutoffSwState 0;
BA_ "GenSigSNA" SG_ 979 UI_airbagCutoffSwState "2";
BA_ "Confidence" SG_ 979 UI_warningIndicatorStatus 1;
BA_ "GenSigSNA" SG_ 979 UI_warningIndicatorStatus "3";
VAL_ 1297 RCM_a117_eventDriveOrientation 1 "RIGHT_HAND_DRIVE" 0 "LEFT_HAND_DRIVE" ;
VAL_ 1297 RCM_a117_eventIDFsignal 1 "ACTIVE" 0 "NOT_ACTIVE" ;
VAL_ 1297 RCM_a117_eventFrontLeftSeatbelt 1 "LATCHED" 0 "UNLATCHED" ;
VAL_ 1297 RCM_a117_eventFrontRightSeatbelt 1 "LATCHED" 0 "UNLATCHED" ;
VAL_ 1297 RCM_a117_eventDriverBrakeApply 3 "Faulty_SNA" 2 "Driver_applying_brakes" 1 "Not_Applied" 0 "NotInit_orOff" ;
VAL_ 1297 RCM_a117_eventAccelPedalPos 255 "SNA" ;
VAL_ 1297 RCM_a118_eventArmStatus 1 "ARMED" 0 "UNARMED" ;
VAL_ 1297 RCM_a118_eventFactoryMode 1 "ENABLED" 0 "DISABLED" ;
VAL_ 1297 RCM_a118_eventDiagEnabled 1 "ENABLED" 0 "DISABLED" ;
VAL_ 1297 RCM_a118_eventDriveOrientation 1 "RIGHT_HAND_DRIVE" 0 "LEFT_HAND_DRIVE" ;
VAL_ 1297 RCM_a118_eventIDFsignal 1 "ACTIVE" 0 "NOT_ACTIVE" ;
VAL_ 1297 RCM_a118_eventFrontLeftSeatbelt 1 "LATCHED" 0 "UNLATCHED" ;
VAL_ 1297 RCM_a118_eventFrontRightSeatbelt 1 "LATCHED" 0 "UNLATCHED" ;
VAL_ 1297 RCM_a118_eventDriverBrakeApply 3 "Faulty_SNA" 2 "Driver_applying_brakes" 1 "Not_Applied" 0 "NotInit_orOff" ;
VAL_ 1297 RCM_a118_eventAccelPedalPos 255 "SNA" ;
VAL_ 881 RCM_matrixIndex 1 "AlertMatrix1" 0 "AlertMatrix0" ;
VAL_ 1415 TCU2_tc10Version 2 "TCU_tc10Version_FINAL_1_0" 1 "TCU_tc10Version_DRAFT" 0 "SNA" ;
VAL_ 1413 TCU2_alertID 16 "w016_IMEIMismatch" 15 "w015_NPNSubscriptionActive" 14 "w014_HostapdCrash" 13 "w013_UplinkQueueFull" 12 "w012_UplinkDegraded" 11 "w011_CellDumpDetected" 10 "w010_WifiDumpDetected" 9 "w009_WifiFirmwareCrash" 8 "w008_KernelPanic" 7 "w007_ModemUnreachable" 6 "w006_MpssUnavailable" 5 "w005_SIMSlotError" 4 "w004_MSDTransmissionFailed" 3 "w003_ECallFailed" 2 "w002_CellRegRejected" 1 "w001_IMSRegistrationFailed" 0 "ALERT_DO_NOT_USE_ZERO" ;
VAL_ 1413 TCU2_alertState 1 "SET" 0 "CLEARED" ;
VAL_ 1413 TCU2_w012_DataRAT 6 "NR5G_UNKNOWN" 5 "NR5G_SA" 4 "NR5G_NSA" 3 "LTE" 2 "WCDMA" 1 "GSM" 0 "UNKNOWN" ;
VAL_ 1413 TCU2_w012_NSAAvailable 2 "NOT_AVAILABLE" 1 "AVAILABLE" 0 "UNKNOWN" ;
VAL_ 1413 TCU2_w013_DataRAT 6 "NR5G_UNKNOWN" 5 "NR5G_SA" 4 "NR5G_NSA" 3 "LTE" 2 "WCDMA" 1 "GSM" 0 "UNKNOWN" ;
VAL_ 1413 TCU2_w013_NSAAvailable 2 "NOT_AVAILABLE" 1 "AVAILABLE" 0 "UNKNOWN" ;
VAL_ 1412 TCU2_logMux 30 "wakeSource" 29 "mdmBand" 28 "checkInternetFailCount" 27 "tcuSMState" 26 "cellularSMState" 25 "mdmDataCallTermCode" 24 "mdmDataCallTermReason" 23 "mdmTxKiloBytes" 22 "mdmMcc" 21 "mdmMnc" 20 "mdmPCIID" 19 "mdmNSAAvailable" 18 "mdmDataCallStatus" 17 "mdmDataRat" 16 "modemUptime" 15 "mdmBusyActive" 14 "mdmSIMStatus" 13 "mdmIMSStatus" 12 "mdmServiceState" 11 "mdmUplinkAvgRate" 10 "mdmUplinkAllowedRate" 9 "mdmSINR" 8 "mdmRSRP" 7 "mdmUplinkQueueSize" 6 "totalResumes" 5 "pwmcap" 4 "pwm" 3 "availableMemory" 2 "mdmCoreTemperature" 1 "cpuUsage" 0 "cpuTemp" ;
VAL_ 1412 TCU2_mdmBusyActive 4294967295 "SNA" ;
VAL_ 1412 TCU2_mdmDataRat 6 "RAT_NR5G_UNKNOWN" 5 "RAT_NR5G_SA" 4 "RAT_NR5G_NSA" 3 "RAT_LTE" 2 "RAT_WCDMA" 1 "RAT_GSM" 0 "RAT_UNKNOWN" ;
VAL_ 1412 TCU2_mdmDataCallStatus 4 "DISCONNECTED" 3 "DISCONNECTING" 2 "CONNECTED" 1 "CONNECTING" 0 "UNKNOWN" ;
VAL_ 1412 TCU2_mdmNSAAvailable 2 "NSA_NOT_AVAILABLE" 1 "NSA_AVAILABLE" 0 "NSA_UNKNOWN" ;
VAL_ 1412 TCU2_cellularSMState 7 "RECOVERING" 6 "LINK_CONNECTED" 5 "CHECKING_INTERNET" 4 "DATA_CONNECTED" 3 "IN_SERVICE" 2 "OUT_OF_SERVICE" 1 "WAITING_COMPONENT" 0 "UNKNOWN" ;
VAL_ 1412 TCU2_tcuSMState 7 "UPDATING" 6 "RESUMING" 5 "SUSPENDED" 4 "PREPARING_SLEEP" 3 "POWER_CYCLING" 2 "IN_OPERATION" 1 "SEARCHING_COMPONENT" 0 "UNKNOWN" ;
VAL_ 1412 TCU2_wakeSource 3 "ETHERNET" 2 "WOIP" 1 "SMS" 0 "NONE" ;
VAL_ 1159 TCU_tc10Version 2 "TCU_tc10Version_FINAL_1_0" 1 "TCU_tc10Version_DRAFT" 0 "SNA" ;
VAL_ 1157 TCU_alertID 16 "w016_IMEIMismatch" 15 "w015_NPNSubscriptionActive" 14 "w014_HostapdCrash" 13 "w013_UplinkQueueFull" 12 "w012_UplinkDegraded" 11 "w011_CellDumpDetected" 10 "w010_WifiDumpDetected" 9 "w009_WifiFirmwareCrash" 8 "w008_KernelPanic" 7 "w007_ModemUnreachable" 6 "w006_MpssUnavailable" 5 "w005_SIMSlotError" 4 "w004_MSDTransmissionFailed" 3 "w003_ECallFailed" 2 "w002_CellRegRejected" 1 "w001_IMSRegistrationFailed" 0 "ALERT_DO_NOT_USE_ZERO" ;
VAL_ 1157 TCU_alertState 1 "SET" 0 "CLEARED" ;
VAL_ 1157 TCU_w012_DataRAT 6 "NR5G_UNKNOWN" 5 "NR5G_SA" 4 "NR5G_NSA" 3 "LTE" 2 "WCDMA" 1 "GSM" 0 "UNKNOWN" ;
VAL_ 1157 TCU_w012_NSAAvailable 2 "NOT_AVAILABLE" 1 "AVAILABLE" 0 "UNKNOWN" ;
VAL_ 1157 TCU_w013_DataRAT 6 "NR5G_UNKNOWN" 5 "NR5G_SA" 4 "NR5G_NSA" 3 "LTE" 2 "WCDMA" 1 "GSM" 0 "UNKNOWN" ;
VAL_ 1157 TCU_w013_NSAAvailable 2 "NOT_AVAILABLE" 1 "AVAILABLE" 0 "UNKNOWN" ;
VAL_ 1155 TCU_logMux 30 "wakeSource" 29 "mdmBand" 28 "checkInternetFailCount" 27 "tcuSMState" 26 "cellularSMState" 25 "mdmDataCallTermCode" 24 "mdmDataCallTermReason" 23 "mdmTxKiloBytes" 22 "mdmMcc" 21 "mdmMnc" 20 "mdmPCIID" 19 "mdmNSAAvailable" 18 "mdmDataCallStatus" 17 "mdmDataRat" 16 "modemUptime" 15 "mdmBusyActive" 14 "mdmSIMStatus" 13 "mdmIMSStatus" 12 "mdmServiceState" 11 "mdmUplinkAvgRate" 10 "mdmUplinkAllowedRate" 9 "mdmSINR" 8 "mdmRSRP" 7 "mdmUplinkQueueSize" 6 "totalResumes" 5 "pwmcap" 4 "pwm" 3 "availableMemory" 2 "mdmCoreTemperature" 1 "cpuUsage" 0 "cpuTemp" ;
VAL_ 1155 TCU_mdmBusyActive 4294967295 "SNA" ;
VAL_ 1155 TCU_mdmDataRat 6 "RAT_NR5G_UNKNOWN" 5 "RAT_NR5G_SA" 4 "RAT_NR5G_NSA" 3 "RAT_LTE" 2 "RAT_WCDMA" 1 "RAT_GSM" 0 "RAT_UNKNOWN" ;
VAL_ 1155 TCU_mdmDataCallStatus 4 "DISCONNECTED" 3 "DISCONNECTING" 2 "CONNECTED" 1 "CONNECTING" 0 "UNKNOWN" ;
VAL_ 1155 TCU_mdmNSAAvailable 2 "NSA_NOT_AVAILABLE" 1 "NSA_AVAILABLE" 0 "NSA_UNKNOWN" ;
VAL_ 1155 TCU_cellularSMState 7 "RECOVERING" 6 "LINK_CONNECTED" 5 "CHECKING_INTERNET" 4 "DATA_CONNECTED" 3 "IN_SERVICE" 2 "OUT_OF_SERVICE" 1 "WAITING_COMPONENT" 0 "UNKNOWN" ;
VAL_ 1155 TCU_tcuSMState 7 "UPDATING" 6 "RESUMING" 5 "SUSPENDED" 4 "PREPARING_SLEEP" 3 "POWER_CYCLING" 2 "IN_OPERATION" 1 "SEARCHING_COMPONENT" 0 "UNKNOWN" ;
VAL_ 1155 TCU_wakeSource 3 "ETHERNET" 2 "WOIP" 1 "SMS" 0 "NONE" ;
VAL_ 1056 UIS_logMux 451 "CamViewerServiceEnabled" 450 "activeAppView" 449 "amdSocPkgPower" 448 "apeHardwareMinorVersion" 447 "audioA2BRediscoveryCount" 446 "audioMediaBrowsing" 445 "audioMediaPlaying" 444 "audioPWSGain" 443 "audioSource" 442 "audioState" 441 "audioType" 440 "audioVolumeLevel" 439 "backlightUserRequest" 438 "bifrostCPUUsage" 437 "bifrostMemUsage" 436 "bifrostOdinEngineRequests" 435 "bifrostOdinEngineUp" 434 "bluetoothAutoConnectionState" 433 "bluetoothAutoconnectActive" 432 "bluetoothAutoconnectAttempts" 431 "bluetoothCPUUsage" 430 "bluetoothConnectionState" 429 "bluetoothMemUsage" 428 "bluetoothPairResult" 427 "bluetoothStackRearState" 426 "bluetoothStackState" 425 "bluetoothState" 424 "boardTemperature" 423 "bootCount" 422 "camBackupDecodeAvgFrametime" 421 "camBackupDecodeFramecount" 420 "camBackupDecodeMaxFrametime" 419 "camBackupDecodeMinFrametime" 418 "cameraBackupFramerate" 417 "cameraBackupLateFrames" 416 "pmSuspendHookIndex" 415 "cameraBackupMaxFrametime" 414 "cameraBackupPacketState" 413 "cameraBackupPipeline" 412 "cameraBackupPopup" 411 "cameraBackupRenderState" 410 "cameraBackupStreamMissing" 409 "cameraBackupStreamQuality" 408 "cameraFrontPacketState" 407 "cameraFrontPipeline" 406 "cameraFrontPopup" 405 "cameraFrontRenderState" 404 "cameraFrontStreamMissing" 403 "cameraLDownwardPacketState" 402 "cameraLDownwardPipeline" 401 "cameraLDownwardRenderState" 400 "cameraLRepeaterFramerate" 399 "cameraLRepeaterLateFrames" 398 "cameraLRepeaterMaxFrametime" 397 "cameraLRepeaterPacketState" 396 "cameraLRepeaterPipeline" 395 "cameraLRepeaterPopup" 394 "cameraLRepeaterRenderState" 393 "cameraLRepeaterStreamMissing" 392 "cameraRDownwardPacketState" 391 "cameraRDownwardPipeline" 390 "cameraRDownwardRenderState" 389 "cameraRRepeaterFramerate" 388 "cameraRRepeaterLateFrames" 387 "cameraRRepeaterMaxFrametime" 386 "cameraRRepeaterPacketState" 385 "cameraRRepeaterPipeline" 384 "cameraRRepeaterPopup" 383 "cameraRRepeaterRenderState" 382 "cameraRRepeaterStreamMissing" 381 "cameraRearViewPacketState" 380 "cameraRearViewPipeline" 379 "cameraRearViewPopup" 378 "cameraRearViewRenderState" 377 "cameraRearViewStreamMissing" 376 "cameraSelectablePacketState" 375 "cameraSelectablePipeline" 374 "cameraSelectableRenderState" 373 "carAssistErrorCode" 372 "carAssistMicAlsaRms" 371 "carAssistMicMuted" 370 "carAssistSessionCount" 369 "carAssistState" 341 "cellularConnectivityStatus" 340 "cellularLinkManagerState" 339 "centerDispAsilA_lsb" 338 "centerDispAsilA_msb" 337 "centerDispAsilB_lsb" 336 "centerDispAsilB_msb" 335 "centerDisplayEvent" 334 "centerDisplayState" 333 "ceruleanx8664CPUUsage" 332 "ceruleanx8664MemUsage" 331 "chargeLocationId" 330 "chargeOnSolarNoChargeReason" 329 "chromiumadapterCPUUsage" 328 "chromiumadapterMemUsage" 327 "clusterCPUUsage" 326 "clusterDisplayState" 325 "clusterFramesOver100Ms" 324 "clusterFramesOver200Ms" 323 "clusterMaxFrametime" 322 "clusterMeanFPS" 321 "clusterMemUsage" 320 "cobaltlinuxCPUUsage" 319 "cobaltlinuxMemUsage" 318 "compositorFrameMonitorState" 317 "compositorRenderAvgRenderTime" 316 "compositorRenderFrameCount" 315 "compositorRenderFrameRate" 314 "compositorRenderGpuPercentage" 313 "compositorRenderMaxFrameTime" 312 "compositorRenderMaxRenderTime" 311 "compositorRenderMinFrameTime" 310 "compositorRenderMinRenderTime" 309 "connectedToInternet" 308 "cpuTemperature" 307 "dasAutonomyControlMessageMiaInDriverlessTakeover" 306 "dashcamOnboardAvailableMB" 305 "dashcamOnboardMB" 304 "dashcamOnboardSavePressCount" 303 "dashcamOnboardTransferCount" 302 "dashcamSavedToOnboardCount" 301 "dashcamSavedToSavedCount" 300 "dashcamSavedToSentryCount" 299 "dashcamState" 298 "dashcamStorageAvailableMB" 297 "dashcamStorageRecentMB" 296 "dashcamStorageSavedMB" 295 "dashcamStorageSentryMB" 294 "dashcamStorageState" 293 "dashcamTransferCount" 292 "dashcamTransferFileCount" 291 "dashcamTransferRateMBps" 290 "dashcamTransferSizeMB" 289 "dashcamTransferTimeMs" 288 "dashcamviewerCPUUsage" 287 "dashcamviewerMemUsage" 286 "developerMode" 285 "dgpuTemperature" 284 "dmCenterAsilCalibrationSync" 283 "dmCenterAsilFirmwareStatus" 282 "dmCenterAsilOpenFlag" 281 "dmCenterAsilResumeFlag" 280 "dmCenterAsilShortFlag" 279 "dmCenterBacklightControlDeferred" 278 "dmCenterBacklightDevExists" 277 "dmCenterBacklightDutyCycle" 276 "dmCenterBacklightFault" 275 "dmCenterBacklightNits" 274 "dmCenterBacklightPowerLevel" 273 "dmCenterConnected" 272 "dmCenterEnabled" 271 "dmCenterLinkCheckOk" 270 "dmCenterMOsdExactCrcCheck" 269 "dmCenterMOsdVideoCrcData" 268 "dmCenterModeSettingStatus" 267 "dmCenterOsdDayNightState" 266 "dmCenterOsdDisplayedState" 265 "dmCenterPowerState" 264 "dmCenterSOsdExactCrcCheck" 263 "dmCenterSOsdVideoCrcData" 262 "dmCenterTouchDeviceExists" 261 "dmCenterTouchIrqCount" 260 "dmGatewayLinkWedged" 259 "dmIcuAsilFirmwareStatus" 258 "dmIcuAsilOpenFlag" 257 "dmIcuAsilResumeFlag" 256 "dmIcuAsilShortFlag" 255 "dmIcuBacklightDevExists" 254 "dmIcuBacklightDutyCycle" 253 "dmIcuBacklightFault" 252 "dmIcuBacklightNits" 251 "dmIcuBacklightPowerLevel" 250 "dmIcuConnected" 249 "dmIcuEnabled" 248 "dmIcuLinkCheckOk" 247 "dmIcuPowerState" 246 "dmIcuTouchIrqCount" 245 "dmRearAsilStatusLsb" 244 "dmRearAsilStatusMsb" 243 "dmRearBacklightDevExists" 242 "dmRearBacklightDutyCycle" 241 "dmRearBacklightFault" 240 "dmRearBacklightNits" 239 "dmRearBacklightPowerLevel" 238 "dmRearConnected" 237 "dmRearEnabled" 236 "dmRearLinkCheckOk" 235 "dmRearPowerState" 234 "dmRearTouchDeviceExists" 233 "dumTclipClipCount" 232 "dumTclipSuccessfulUploadCount" 231 "dumTclipTransferCount" 230 "dumTclipUploadActive" 229 "dumTclipUploadState" 228 "dynamicTriggersCampaignState" 227 "dynamicTriggersHRLServiceState" 226 "dynamicTriggersOutputManagerServiceState" 225 "dynamicTriggersTelemetryServiceState" 224 "embeddedGameName" 223 "embeddedGameState" 222 "estimatedOccupancyCount" 221 "featureSuperchargingEnabled" 220 "firmwareReleaseScope" 219 "godotCPUUsage" 218 "godotMemUsage" 217 "godot_MEMORY_DYNAMIC" 216 "godot_MEMORY_STATIC" 215 "godot_TIME_FPS" 214 "godot_TIME_PROCESS" 213 "gpsmanagerCPUUsage" 212 "gpsmanagerMemUsage" 211 "gtwSocUartRxStatBadChecksum" 210 "gtwSocUartRxStatBadTooBig" 209 "gtwSocUartRxStatBadTooSmall" 208 "gtwSocUartRxStatHandleErr" 207 "gtwSocUartRxStatHeartbeats" 206 "gtwSocUartRxStatMsgErr" 205 "gtwSocUartRxStatUnhandled" 204 "gtwSocUartRxStatValidPackets" 203 "gtwSocUartTxStatAnsMismatch" 202 "gtwSocUartTxStatBadTooBig" 201 "gtwSocUartTxStatNacks" 200 "gtwSocUartTxStatPackets" 199 "gtwSocUartTxStatTimeouts" 198 "headsetConnectionState" 197 "headsetPairResult" 196 "hermesclientCPUUsage" 195 "hermesclientMemUsage" 194 "hermesdynamicCPUUsage" 193 "hermesdynamicMemUsage" 192 "hicarAudioSetupState" 191 "hicarAudioTeardownState" 190 "hicarCallState" 189 "hicarConnectionState" 188 "hicarDataReceiveType" 187 "hicarErrorCode" 186 "hicarEventCode" 185 "hicarServiceState" 184 "homelinkState" 183 "igpuTemperature" 182 "inSuperchargerGeofence" 181 "limex8664CPUUsage" 180 "limex8664MemUsage" 179 "mediaImageCacheCost" 178 "mediaImageCacheSize" 177 "mediaNeedAuthToken" 176 "mediaPlaybackStatus" 175 "mediaserveCPUUsage" 174 "mediaserveMemUsage" 173 "mirrorGeofenceActive" 172 "modemBusyActive" 171 "modemECallppAvail" 170 "mounterdDashcamCapacityGB" 169 "mounterdDeviceCount" 168 "mounterdEncryptionCapacityGB" 167 "mounterdFilesystemCountExfat" 166 "mounterdFilesystemCountExt3" 165 "mounterdFilesystemCountExt4" 164 "mounterdFilesystemCountFat32" 163 "mounterdFrontHubConnected" 162 "mounterdFrontHubDisconnected" 161 "mounterdMountCountTotal" 160 "mounterdState" 159 "muteNavVolume" 158 "navAudioVolume" 157 "navServiceError" 156 "netCellRxCount" 155 "netCellRxRate" 154 "netCellTxCount" 153 "netCellTxRate" 152 "netEthRxCount" 151 "netEthRxDroppedCount" 150 "netEthRxDroppedRate" 149 "netEthRxErrorCount" 148 "netEthRxErrorRate" 147 "netEthRxRate" 146 "netEthTxCount" 145 "netEthTxRate" 144 "netWifiRxCount" 143 "netWifiRxRate" 142 "netWifiTxCount" 141 "netWifiTxRate" 140 "nuanceserverCPUUsage" 139 "nuanceserverMemUsage" 138 "numCorrMemErrorsECC" 137 "numUncorrMemErrorsECC" 136 "nvmeDataUnitsWritten100mb" 135 "nvmePercentLifetimeUsed" 134 "nvmeTemperature" 133 "odinAuthCount" 132 "odinAuthFailCount" 131 "odinCPUUsage" 130 "odinEcuLogForceTriggerUploadState" 129 "odinEcuLogUploadState" 128 "odinFileSystemState" 127 "odinGatewayConnectionState" 126 "odinHermesConnectionState" 125 "odinHrlLogUploadState" 124 "odinHrlUploadLimits" 123 "odinListTasksCmdDurationMs" 122 "odinListTasksCmdResult" 121 "odinMemUsage" 120 "odinNetworkFailCount" 119 "odinNetworkStartCount" 118 "odinOrchestratorFailCount" 117 "odinOrchestratorStartCount" 116 "odinPeriodicTaskState" 115 "odinProcessState" 114 "odinStatusCmdDurationMs" 113 "odinStatusCmdResult" 112 "polytopiax8664CPUUsage" 111 "polytopiax8664MemUsage" 110 "powerManagerState" 109 "psiCpuSome" 108 "psiIOFull" 107 "psiIOSome" 106 "psiMemFull" 105 "psiMemSome" 104 "qtcarCPUUsage" 103 "qtcarMemUsage" 102 "radioserveCPUUsage" 101 "radioserveMemUsage" 100 "rearDisplayState" 99 "rearDisplayUserPresent" 98 "releasenotesCPUUsage" 97 "releasenotesMemUsage" 96 "remoteRequestType" 95 "robotaxiModeActive" 94 "scheduleChargeEndTime" 93 "scheduleChargeStartTime" 92 "scheduledChargingMode" 91 "sentryIncidentCount" 90 "sentryNeedsNap" 89 "sentryState" 88 "serverCPUUsage" 87 "serverMemUsage" 86 "serviceMode" 85 "serviceModePlus" 84 "settingsAutoTurnSignal" 83 "slackerLoginResult" 82 "sleepCount" 81 "sleepState" 80 "sleepTime" 79 "sleepType" 78 "softwareInstallPopupStatus" 77 "softwareUpdatePrimDownload" 76 "softwareUpdateState" 75 "solitaireCPUUsage" 74 "solitaireMemUsage" 73 "speechrecoCPUUsage" 72 "speechrecoMemUsage" 71 "spotifyserverCPUUsage" 70 "spotifyserverMemUsage" 69 "sudokuCPUUsage" 68 "sudokuMemUsage" 67 "superchargePaymentNeeded" 66 "suspensionGeofence" 65 "systemMemSwapUsage" 64 "systemUptime" 63 "systemWakeTime" 62 "tegraModemManState" 61 "teleopAvgPacketDelta" 60 "teleopMaxPacketDelta" 59 "teleopMinPacketDelta" 58 "teleopPacketDrops" 57 "teleopPhoneCallActive" 56 "teleopStreamXrunCount" 55 "teslaMediaCacheCost" 54 "teslaMediaCacheSize" 53 "teslachromiumCPUUsage" 52 "teslachromiumMemUsage" 51 "testDriveMode" 50 "thermalProfile" 49 "thermalResistance" 48 "tmserverCPUUsage" 47 "tmserverMemUsage" 46 "touchEventsAggCount" 45 "tunerCurrentAntenna1" 44 "tunerCurrentAntenna2" 43 "tunerTemperatureCelsius" 42 "tunerTemperatureFahrenheit" 41 "tunerVoltage1V8" 40 "tunerVoltage3V3" 39 "tunerVoltageAntenna1" 38 "tunerVoltageAntenna2" 37 "tunerVoltageMQS" 36 "tunerVoltageOperation" 35 "tunerVoltageUBatt" 34 "uiFramesOver100Ms" 33 "uiFramesOver200Ms" 32 "uiFrametimeGearShiftDToR" 31 "uiFrametimeGearShiftPToR" 30 "uiMaxFrametime" 29 "uiMeanFPS" 28 "uiQtCarSwapUsage" 27 "uiQtCarUptime" 26 "valetMode" 25 "valhallaserverCPUUsage" 24 "valhallaserverMemUsage" 23 "vehicleCPUUsage" 22 "vehicleMemUsage" 21 "videodCPUUsage" 20 "videodMemUsage" 19 "vmtouchCPUUsage" 18 "vmtouchMemUsage" 17 "webbrowserCPUUsage" 16 "webbrowserMemUsage" 15 "wifiAutoJoinLowRSSI" 14 "wifiBars" 13 "wifiStackReady" 12 "wifiStackState" 11 "wifiTemperature" 10 "zramCompressedSize" 9 "zramCompressionRatio" 8 "zramFailedReads" 7 "zramFailedWrites" 6 "zramInvalidIO" 5 "zramNotifyFree" 4 "zramOriginalSize" 3 "zramReadIO" 2 "zramReadTicks" 1 "zramWriteIO" 0 "zramWriteTicks" ;
VAL_ 1056 UIS_wifiStackState 17 "WL_RESET_CONNMAN" 16 "WL_RUNNING_LOCAL" 15 "WL_CAPTIVE" 14 "WL_DISCONNECTING" 13 "WL_RUNNING" 12 "WL_WAITING_ONLINE" 11 "WL_CHECKING" 10 "WL_CONFIGURING" 9 "WL_CONNECTING" 8 "WL_SELECTING_NETWORK" 7 "WL_WAITING_AUTOCONNECT" 6 "WL_SEARCHING" 5 "WL_POWERING_ON" 4 "WL_DISABLED_WAIT" 3 "WL_POWERING_OFF" 2 "WL_WAITING_TECHNOLOGY" 1 "WL_RESETTING" 0 "DEFAULT" ;
VAL_ 1056 UIS_wifiStackReady 1 "TRUE" 0 "FALSE" ;
VAL_ 1056 UIS_wifiAutoJoinLowRSSI 1 "TRUE" 0 "FALSE" ;
VAL_ 1056 UIS_valetMode 1 "TRUE" 0 "FALSE" ;
VAL_ 1056 UIS_thermalProfile 11 "FACTORY_HOT" 10 "FACTORY_WARM" 9 "FACTORY_IDLE" 8 "FACTORY_COLD" 7 "INFOTAINMENT_OVERHEAT" 6 "INFOTAINMENT_THROTTLE" 5 "INFOTAINMENT_THRESHOLD" 4 "INFOTAINMENT_HOT" 3 "INFOTAINMENT_WARM" 2 "INFOTAINMENT_IDLE" 1 "INFOTAINMENT_COLD" 0 "SNA" ;
VAL_ 1056 UIS_testDriveMode 1 "ENABLED" 0 "DISABLED" ;
VAL_ 1056 UIS_tegraModemManState 20 "INVALID" 19 "CHECKINGMODEM" 18 "CHECKINGPORTS" 17 "STOPPINGLINK" 16 "UNCONFIGURINGLINK" 15 "RUNNINGSTATUS" 14 "RUNNING" 13 "CHECKINGLINK" 12 "CONFIGURINGLINK" 11 "RETRYINGLINK" 10 "STARTINLINK" 9 "PRECONDITIONINGLINK" 8 "INITIALIZING2" 7 "CHECKINGANTENNA" 6 "ENABLINGSIM" 5 "INITIALIZING1" 4 "RECOVERING" 3 "WAKING" 2 "SLEEPING" 1 "RESTARTING" 0 "ABORTINGLINK" ;
VAL_ 1056 UIS_suspensionGeofence 1 "REQUESTED" 0 "REMOVED" ;
VAL_ 1056 UIS_softwareUpdateState 11 "POST_INSTALL_START" 10 "COMPLETE" 9 "GATEWAY_DONE" 8 "GATEWAY_START" 7 "APE_B" 6 "APE" 5 "STAGED" 4 "GAME" 3 "SECONDARY" 2 "GOOD_SIG" 1 "PRIMARY" 0 "INIT" ;
VAL_ 1056 UIS_softwareUpdatePrimDownload 3 "FAILURE" 2 "SUCCESS" 1 "IN_PROGRESS" 0 "IDLE" ;
VAL_ 1056 UIS_softwareInstallPopupStatus 3 "INSTALLING" 2 "PRESENT" 1 "COUNTDOWN" 0 "NONE" ;
VAL_ 1056 UIS_sleepType 4 "Unknown" 3 "ModernStandby" 2 "S2Idle" 1 "S3" 0 "Shallow" ;
VAL_ 1056 UIS_sleepState 3 "Wake" 2 "Sleep" 1 "Run" 0 "Boot" ;
VAL_ 1056 UIS_slackerLoginResult 5000 "SLACKER_LOGIN_CREDENTIALS_MISSING" 444 "SLACKER_LOGIN_USER_BUMPED" 412 "SLACKER_LOGIN_TOKEN_INVALID_TIMESTAMP" 409 "SLACKER_LOGIN_TOKEN_REVOKED_KEY" 403 "SLACKER_LOGIN_CAPTCHA_REQUIRED" 401 "SLACKER_LOGIN_INCORRECT_CREDENTIALS" 400 "SLACKER_LOGIN_TOKEN_INVALID_SIGNATURE" 6 "SLACKER_LOGIN_BAD_ACCOUNT_LEVEL" 5 "SLACKER_LOGIN_OTHER_ERROR" 4 "SLACKER_LOGIN_NET_ERROR" 3 "SLACKER_LOGIN_TOKEN_UNKNOWN_ERROR" 2 "SLACKER_LOGIN_SUCCESS" 1 "SLACKER_LOGIN_SERVERTIME_FAILED" ;
VAL_ 1056 UIS_settingsAutoTurnSignal 1 "AUTO_CANCEL" 0 "OFF" ;
VAL_ 1056 UIS_sentryState 5 "QUIET" 4 "PANIC" 3 "AWARE" 2 "ARMED" 1 "IDLE" 0 "OFF" ;
VAL_ 1056 UIS_scheduledChargingMode 3 "TIME_WINDOW" 2 "END_BY" 1 "START_AT" 0 "OFF" ;
VAL_ 1056 UIS_remoteRequestType 106 "NAV_GPS_DESTINATION_REQUEST" 105 "TESLA_AUTH_RESPONSE" 104 "GET_MESSAGE" 103 "SET_LIGHTBAR_DITCH" 102 "SET_LIGHTBAR_MIDDLE" 101 "SET_LIGHTBAR_BRIGHTNESS" 100 "REMOVE_PRECONDITION_SCHEDULE" 99 "ADD_PRECONDITION_SCHEDULE" 98 "REMOVE_CHARGE_SCHEDULE" 97 "ADD_CHARGE_SCHEDULE" 96 "SET_REAR_ZONE_LIGHT_REQUEST" 95 "SET_FRONT_ZONE_LIGHT_REQUEST" 94 "SET_TENT_MODE_REQUEST" 93 "SET_POWERSHARE_REQUEST" 92 "SET_POWERSHARE_DISCHARGE_LIMIT" 91 "SET_POWERSHARE_FEATURE" 90 "NAVIGATION_WAYPOINTS_REQUEST" 89 "VEHICLE_CONTROL_RESET_PIN_TO_DRIVE_ADMIN" 88 "SET_TRUCK_BED_LIGHT_BRIGHTNESS" 87 "SET_TRUCK_BED_LIGHT_AUTO_STATE" 86 "SET_TRAILER_LIGHT_TEST_START_STOP" 85 "SET_POWER_FEED_SOC_LIMIT" 84 "SET_POWER_FEED_TIMER" 83 "SET_POWER_FEED_ON_OFF" 82 "SET_OUTLET_SOC_LIMIT" 81 "SET_OUTLET_TIMER" 80 "SET_OUTLETS_ON_OFF" 79 "DRIVING_CLEAR_SPEED_LIMIT_PIN_ADMIN" 78 "VEHICLE_CONTROL_RESET_PIN_TO_DRIVE" 77 "VEHICLE_CONTROL_SET_PIN_TO_DRIVE" 76 "RESERVED_SEVENTY_SIX" 75 "GET_CHARGE_ON_SOLAR_FEATURE" 74 "UPDATE_CHARGE_ON_SOLAR_FEATURE" 73 "GET_MANAGED_CHARGING_SITES" 72 "ERASE_USER_DATA" 71 "STW_HEAT_LEVEL" 70 "AUTO_STW_HEAT" 69 "NAVIGATION_ROUTE" 68 "REMOVE_MANAGED_CHARGING_SITE" 67 "ADD_MANAGED_CHARGING_SITE" 66 "SET_COP_TEMP" 65 "GUEST_MODE" 64 "BOOMBOX" 63 "BLUETOOTH_CLASSIC_PAIRING_REQUEST" 62 "CHARGE_PORT_DOOR_OPEN" 61 "CHARGE_PORT_DOOR_CLOSE" 60 "RESERVED_SIXTY" 59 "RESERVED_FIFTY_NINE" 58 "TAKE_DRIVENOTE" 57 "VIDEO_REQUEST" 56 "GET_RATE_TARIFF" 55 "RESERVED_FIFTY_FIVE" 54 "SET_VEHICLE_NAME" 53 "NAVIGATION_GPS_REQUEST" 52 "PSEUDONYM_SYNC_REQUEST" 51 "PII_KEY_REQUEST" 50 "SET_CABIN_OVERHEAT_PROTECTION" 49 "HVAC_SEAT_COOLER_ACTIONS" 48 "AUTO_SEAT_CLIMATE" 47 "DASHCAM_SAVE_CLIP" 46 "PING" 45 "HVAC_RECIRCULATION" 44 "HVAC_CLIMATE_KEEPER" 43 "SET_CHARGING_AMPS" 42 "SCHEDULED_DEPARTURE" 41 "SCHEDULED_CHARGING" 40 "VITALS_ACK" 39 "VITALS_SUBSCRIPTION" 38 "VEHICLE_DATA_ACK" 37 "VEHICLE_DATA_SUBSCRIPTION" 36 "HVAC_SEAT_HEATER_ACTIONS" 35 "HVAC_BIO_WEAPON_MODE" 34 "VEHICLE_CONTROL_WINDOW" 33 "VEHICLE_CONTROL_TRIGGER_HOMELINK" 32 "VEHICLE_CONTROL_SUNROOF_OPEN_CLOSE" 31 "VEHICLE_CONTROL_SET_VALET_MODE" 30 "VEHICLE_CONTROL_SET_SENTRY_MODE" 29 "VEHICLE_CONTROL_SCHEDULE_SOFTWARE_UPDATE" 28 "VEHICLE_CONTROL_RESET_VALET_PIN" 27 "VEHICLE_CONTROL_HONK_HORN" 26 "VEHICLE_CONTROL_FLASH_LIGHTS" 25 "VEHICLE_CONTROL_CANCEL_SOFTWARE_UPDATE" 24 "UI_SET_UPCOMING_CALENDAR_ENTRIES" 23 "GET_NEARBY_CHARGING_SITES" 22 "NAVIGATION_SUPERCHARGER_REQUEST" 21 "NAVIGATION_REQUEST" 20 "MEDIA_PREVIOUS_TRACK" 19 "MEDIA_NEXT_TRACK" 18 "MEDIA_PREVIOUS_FAVORITE" 17 "MEDIA_NEXT_FAVORITE" 16 "MEDIA_UPDATE_VOLUME" 15 "MEDIA_PLAY" 14 "HVAC_TEMPERATURE_ADJUSTMENT" 13 "HVAC_STEERING_WHEEL_HEATER" 12 "HVAC_SET_PRECONDITIONING_MAX" 11 "RESERVED_ELEVEN" 10 "HVAC_AUTO" 9 "DRIVING_SPEED_LIMIT" 8 "DRIVING_SET_SPEED_LIMIT" 7 "DRIVING_CLEAR_SPEED_LIMIT_PIN" 6 "CHARGING_START_STOP" 5 "CHARGING_SET_LIMIT" 4 "STREAM_MESSAGE" 3 "CREATE_STREAM_SESSION" 2 "REMOTE_START_DRIVE" 1 "GET_VEHICLE_DATA" 0 "UNKNOWN" ;
VAL_ 1056 UIS_rearDisplayUserPresent 1 "TRUE" 0 "FALSE" ;
VAL_ 1056 UIS_rearDisplayState 9 "ENTERTAINMENT" 8 "DOG" 7 "SENTRY" 6 "LOCK" 5 "CHARGING" 4 "DRIVING" 3 "ON" 2 "ACCESSORY" 1 "DIM" 0 "OFF" ;
VAL_ 1056 UIS_powerManagerState 31 "PMS_ENTERINGROBOTAXILOADSHED" 30 "PMS_ROBOTAXILOADSHEDDING" 29 "PMS_UPLOADDATA" 28 "PMS_EXTREMELOADSHEDDING" 27 "PMS_ENTERINGEXTREMELOADSHED" 26 "PMS_PREPARINGSLEEP" 25 "PMS_ENTERINGLOADSHED" 24 "PMS_SENTRYACTIVE" 23 "PMS_EXITINGLOADSHED" 22 "PMS_LOADSHEDDING" 21 "PMS_EXITINGSENTRY" 20 "PMS_SENTRYARMED" 19 "PMS_ENTERINGSENTRY" 18 "PMS_UNKNOWN_SNA" 17 "PMS_EXITINGSLEEP" 16 "PMS_READYFORSLEEP" 15 "PMS_WAITINGONRAILS" 14 "PMS_PERFORMANCE" 13 "PMS_HIGHPOWERSTARTED" 12 "PMS_HIGHPOWERSTOPPING" 11 "PMS_HIGHPOWERSTARTING" 10 "PMS_REBOOT" 9 "PMS_ENTERINGSLEEP" 8 "PMS_ALLTUCKEDIN" 7 "PMS_CHARGING" 6 "PMS_AUDIOSTOPPED" 5 "PMS_AUDIOSTOPPING" 4 "PMS_POWERBROWNOUT" 3 "PMS_AUDIOSTARTING" 2 "PMS_ACCDELAY" 1 "PMS_FULLPOWER" 0 "PMS_CHECKING" ;
VAL_ 1056 UIS_odinStatusCmdResult 2 "EXCEPTION" 1 "FAIL" 0 "PASS" ;
VAL_ 1056 UIS_odinProcessState 4 "UNKNOWN" 3 "RUNNING_NETWORK_AND_ORCHESTRATOR" 2 "RUNNING_ORCHESTRATOR" 1 "RUNNING_NETWORK" 0 "IDLE" ;
VAL_ 1056 UIS_odinPeriodicTaskState 6 "QUEUED_FAILED" 5 "CANCELLED" 4 "FAILED" 3 "TIMEOUT" 2 "SUCCESS" 1 "ENQUEUED" 0 "IDLE" ;
VAL_ 1056 UIS_odinListTasksCmdResult 2 "EXCEPTION" 1 "FAIL" 0 "PASS" ;
VAL_ 1056 UIS_odinHrlUploadLimits 1 "CELL_DAILY_UPLOAD_LIMIT_REACHED" 0 "DAILY_UPLOAD_LIMIT_REACHED" ;
VAL_ 1056 UIS_odinHrlLogUploadState 4 "HRL_FILE_UPLOADED" 3 "HRL_FILE_UPLOAD_FAILED" 2 "HRL_FILE_TRANSFER_FAILED" 1 "HRL_FILE_TRANSFERRED" 0 "SERVICE_STARTED" ;
VAL_ 1056 UIS_odinHermesConnectionState 3 "CONNECTION_ERROR" 2 "CONNECTING" 1 "CONNECTED" 0 "DISCONNECTED" ;
VAL_ 1056 UIS_odinGatewayConnectionState 2 "CONNECTION_ERROR" 1 "CONNECTED" 0 "DISCONNECTED" ;
VAL_ 1056 UIS_odinFileSystemState 4 "DIR_SIZE_LIMIT_SURPASSED" 3 "OVERSIZED_FILE" 2 "DIR_DELETED" 1 "FILE_DELETED" 0 "IDLE" ;
VAL_ 1056 UIS_odinEcuLogUploadState 5 "FAILURE" 4 "COMPLETE" 3 "UPLOADING" 2 "GET_DATA" 1 "POLLING" 0 "IDLE" ;
VAL_ 1056 UIS_odinEcuLogForceTriggerUpload 1 "REQUESTED" 0 "IDLE" ;
VAL_ 1056 UIS_mounterdState 9 "MOUNTING_STEAM" 8 "MOUNTING_LIGHTSHOW" 7 "MOUNTING_UPDATE" 6 "MOUNTING_MEDIA" 5 "MOUNTING_ENCRYPTION" 4 "MOUNTING_DASHCAM" 3 "UNMOUNTING" 2 "IDLE" 1 "TERMINATED" 0 "INVALID" ;
VAL_ 1056 UIS_modemECallppAvail 1 "ENABLED" 0 "DISABLED" ;
VAL_ 1056 UIS_modemBusyActive 1 "RUNNING" 0 "OFF" ;
VAL_ 1056 UIS_mirrorGeofenceActive 1 "TRUE" 0 "FALSE" ;
VAL_ 1056 UIS_mediaPlaybackStatus 2 "PAUSED" 1 "PLAYING" 0 "STOPPED" ;
VAL_ 1056 UIS_mediaNeedAuthToken 1 "TRUE" 0 "FALSE" ;
VAL_ 1056 UIS_inSuperchargerGeofence 1 "TRUE" 0 "FALSE" ;
VAL_ 1056 UIS_homelinkState 23 "HW_ERROR" 22 "UNIVERSAL_RECEIVER_ERROR" 21 "UNIVERSAL_RECEIVER_SUCCESS" 20 "UNIVERSAL_RECEIVER_WAIT" 19 "DEFAULT_FAIL" 18 "DEFAULT_SUCCESS" 17 "DEFAULT_WAIT" 16 "STANDARD_FAIL" 15 "STANDARD_SUCCESS" 14 "STANDARD_WAIT" 13 "CLEAR_FAIL" 12 "CLEAR_SUCCESS" 11 "CLEAR_WAIT" 10 "TIMEOUT" 9 "LEARN_FAIL" 8 "LEARN_CANCLE" 7 "LEARN_SUCCESS_NOT_ROLLING" 6 "LEARN_SUCCESS_ROLLING" 5 "LEARN_TEST" 4 "LEARN_SUCCESS" 3 "LEARN_WAIT" 2 "PROGRAM_WAIT" 1 "TRANSMITTING" 0 "IDLE" ;
VAL_ 1056 UIS_hicarEventCode 9 "APPLIST_UPDATED" 8 "PROJECTION_BACKGROUND" 7 "PROJECTION_FOREGROUND" 6 "CALL_METADATA_SUPPORTED" 5 "MEDIA_METADATA_SUPPORTED" 4 "NAVIGATION_METADATA_SUPPORTED" 3 "SPEECH_STOPPED" 2 "SPEECH_STARTED" 1 "NAVIGATION_STOPPED" 0 "NAVIGATION_STARTED" ;
VAL_ 1056 UIS_hicarErrorCode 0 "AUDIO_LATENCY" ;
VAL_ 1056 UIS_hicarConnectionState 4 "DISCONNECTING" 3 "CONNECTED" 2 "WIFI_CONNECTING" 1 "BR_CONNECTING" 0 "DISCONNECTED" ;
VAL_ 1056 UIS_hicarCallState 8 "DISCONNECTING" 7 "DISCONNECTED" 6 "WAITING" 5 "INCOMING" 4 "ALERTING" 3 "DIALING" 2 "HOLDING" 1 "ACTIVE" 0 "IDLE" ;
VAL_ 1056 UIS_hicarAudioTeardownState 3 "DEFAULT" 2 "PHONE_CALL" 1 "NAVIGATION" 0 "MEDIA" ;
VAL_ 1056 UIS_hicarAudioSetupState 3 "DEFAULT" 2 "PHONE_CALL" 1 "NAVIGATION" 0 "MEDIA" ;
VAL_ 1056 UIS_headsetPairResult 23 "HID_PAIRED" 22 "HID_MAX_NR_OF_CONNS" 21 "HID_PAGE_TIMEOUT" 20 "HID_OETC_USER" 19 "HID_REJ_BY_REMOTE_NO_RES" 18 "HID_LMP_RESPONSE_TIMEOUT" 17 "HID_AUTH_FAILURE" 16 "HID_KEY_MISSING" 15 "HID_NO_RESPONSE" 14 "HID_ALREADY_REQUESTED_BY_REMOTE" 13 "HID_UNKNOWN" 12 "HID_UNPAIRED" 11 "PAIRED" 10 "MAX_NR_OF_CONNS" 9 "PAGE_TIMEOUT" 8 "OETC_USER" 7 "REJ_BY_REMOTE_NO_RES" 6 "LMP_RESPONSE_TIMEOUT" 5 "AUTH_FAILURE" 4 "KEY_MISSING" 3 "NO_RESPONSE" 2 "ALREADY_REQUESTED_BY_REMOTE" 1 "UNKNOWN" 0 "UNPAIRED" ;
VAL_ 1056 UIS_headsetConnectionState 77 "HID_ERROR_UNKNOWN" 76 "HID_ERROR_ANTENNA_DISCONNECTED" 75 "HID_CONNECTED" 74 "HID_CONNECT_CANCELLED" 73 "HID_CONNECT_PROFILE_UNAVAILABLE" 72 "HID_CONNECT_INVALID_ARGUMENT" 71 "HID_CONNECT_ADAPTER_OFF" 70 "HID_CONNECT_NOT_SUPPORTED" 69 "HID_CONNECT_ALREADY_CONN" 68 "HID_CONNECT_DEVICE_NOT_FOUND_NO_RESOURCES" 67 "HID_CONNECT_DEVICE_NOT_FOUND_PAGE_TIMEOUT" 66 "HID_CONNECT_DEVICE_NOT_FOUND" 65 "HID_CONNECT_FAILED_REMOTE_TERMINATED" 64 "HID_CONNECT_FAILED_NO_RESOURCES" 63 "HID_CONNECT_FAILED_CONNECTION_TIMEOUT" 62 "HID_CONNECT_FAILED" 61 "HID_CONNECT_SDP_FAILURE" 60 "HID_CONNECT_PIN_MISSING" 59 "HID_CONNECT_PAGE_TIMEOUT" 58 "HID_CONNECT_REJ_BY_REMOTE_NO_RES" 57 "HID_CONNECT_MAX_NR_OF_CONNS" 56 "HID_CONNECT_CONTROLLER_BUSY" 55 "HID_CONNECT_CONN_TIMEOUT" 54 "HID_CONNECT_MAX_NR_OF_ACL" 53 "HID_CONNECT_LMP_RESPONSE_TIMEOUT" 52 "HID_CONNECT_HOST_TIMEOUT" 51 "HID_CONNECT_UNKNOWN_FAILURE" 50 "HID_DISCONNECT_UNKNOWN" 49 "HID_DISCONNECT_OETC_POWERING_OFF" 48 "HID_DISCONNECT_OETC_LOW_RESOURCE" 47 "HID_DISCONNECT_REJ_BY_REMOTE_SEC" 46 "HID_DISCONNECT_AUTH_FAIL" 45 "HID_DISCONNECT_LMP_RESPONSE_TIMEOUT" 44 "HID_DISCONNECT_OETC_USER" 43 "HID_DISCONNECT_CONN_TIMEOUT" 42 "HID_DISCONNECT_CONN_TERM_LOCAL_HOST" 41 "HID_DISCONNECT_LINKLOSS" 40 "HID_DISCONNECT_FROM_REMOTE" 39 "HID_DISCONNECTED" 38 "ERROR_UNKNOWN" 37 "ERROR_ANTENNA_DISCONNECTED" 36 "CONNECTED" 35 "CONNECT_CANCELLED" 34 "CONNECT_PROFILE_UNAVAILABLE" 33 "CONNECT_INVALID_ARGUMENT" 32 "CONNECT_ADAPTER_OFF" 31 "CONNECT_NOT_SUPPORTED" 30 "CONNECT_ALREADY_CONN" 29 "CONNECT_DEVICE_NOT_FOUND_NO_RESOURCES" 28 "CONNECT_DEVICE_NOT_FOUND_PAGE_TIMEOUT" 27 "CONNECT_DEVICE_NOT_FOUND" 26 "CONNECT_FAILED_REMOTE_TERMINATED" 25 "CONNECT_FAILED_NO_RESOURCES" 24 "CONNECT_FAILED_CONNECTION_TIMEOUT" 23 "CONNECT_FAILED" 22 "CONNECT_SDP_FAILURE" 21 "CONNECT_PIN_MISSING" 20 "CONNECT_PAGE_TIMEOUT" 19 "CONNECT_REJ_BY_REMOTE_NO_RES" 18 "CONNECT_MAX_NR_OF_CONNS" 17 "CONNECT_CONTROLLER_BUSY" 16 "CONNECT_CONN_TIMEOUT" 15 "CONNECT_MAX_NR_OF_ACL" 14 "CONNECT_LMP_RESPONSE_TIMEOUT" 13 "CONNECT_HOST_TIMEOUT" 12 "CONNECT_UNKNOWN_FAILURE" 11 "DISCONNECT_UNKNOWN" 10 "DISCONNECT_OETC_POWERING_OFF" 9 "DISCONNECT_OETC_LOW_RESOURCE" 8 "DISCONNECT_REJ_BY_REMOTE_SEC" 7 "DISCONNECT_AUTH_FAIL" 6 "DISCONNECT_LMP_RESPONSE_TIMEOUT" 5 "DISCONNECT_OETC_USER" 4 "DISCONNECT_CONN_TIMEOUT" 3 "DISCONNECT_CONN_TERM_LOCAL_HOST" 2 "DISCONNECT_LINKLOSS" 1 "DISCONNECT_FROM_REMOTE" 0 "DISCONNECTED" ;
VAL_ 1056 UIS_firmwareReleaseScope 2 "PROD" 1 "DEV" 0 "UNKNOWN" ;
VAL_ 1056 UIS_embeddedGameState 2 "FROZEN" 1 "PLAYING" 0 "STOPPED" ;
VAL_ 1056 UIS_embeddedGameName 2 "POLYTOPIA" 1 "SOLITAIRE" 0 "NONE" ;
VAL_ 1056 UIS_dynamicTriggersTelemetryServ 4 "REGISTERED" 3 "UPLOADED" 2 "UPLOAD_FAILED" 1 "REGISTRATION_FAILED" 0 "IDLE" ;
VAL_ 1056 UIS_dynamicTriggersOutputManager 4 "REGISTERED" 3 "UPLOADED" 2 "UPLOAD_FAILED" 1 "REGISTRATION_FAILED" 0 "IDLE" ;
VAL_ 1056 UIS_dynamicTriggersHRLServiceSta 3 "COLLECTING" 2 "COLLECTED" 1 "FAILED" 0 "IDLE" ;
VAL_ 1056 UIS_dynamicTriggersCampaignState 9 "COLLECTING_OUTPUTS" 8 "COOLDOWN" 7 "EVALUATING" 6 "HAMMERED" 5 "EXPIRED" 4 "COMPLETED" 3 "STARTED" 2 "TRIGGERED" 1 "DESCHEDULED" 0 "SNA" ;
VAL_ 1056 UIS_dumTclipUploadState 7 "TclipStateDone" 6 "TclipStateUploading" 5 "TclipStateWaiting" 4 "TclipStateTransferring" 3 "TclipStatePolling" 2 "TclipStateChecking" 1 "TclipStateIdle" 0 "TclipStateSNA" ;
VAL_ 1056 UIS_dmRearPowerState 1 "ON" 0 "OFF" ;
VAL_ 1056 UIS_dmRearLinkCheckOk 1 "PASSED" 0 "FAILED" ;
VAL_ 1056 UIS_dmRearBacklightPowerLevel 2 "HIGH_POWER" 1 "LOW_POWER" 0 "OFF" ;
VAL_ 1056 UIS_dmRearBacklightDevExists 1 "PASSED" 0 "FAILED" ;
VAL_ 1056 UIS_dmIcuPowerState 1 "ON" 0 "OFF" ;
VAL_ 1056 UIS_dmIcuLinkCheckOk 1 "PASSED" 0 "FAILED" ;
VAL_ 1056 UIS_dmIcuBacklightPowerLevel 2 "HIGH_POWER" 1 "LOW_POWER" 0 "OFF" ;
VAL_ 1056 UIS_dmIcuBacklightDevExists 1 "PASSED" 0 "FAILED" ;
VAL_ 1056 UIS_dmIcuAsilResumeFlag 4 "ACI_ERROR_RESET" 3 "SOFTWARE_RESET" 2 "REBOOT_RESET" 1 "WATCHDOG_RESET" 0 "GLOBAL_RESET" ;
VAL_ 1056 UIS_dmIcuAsilFirmwareStatus 3 "NORMAL_RUN" 2 "CALIBRATION_DONE" 1 "CALIBRATION" 0 "INITIAL_STAGE" ;
VAL_ 1056 UIS_dmCenterSOsdExactCrcCheck 2 "PASS" 1 "EXPECT_MATCH_FAIL" 0 "EXPECT_MISMATCH_FAIL" ;
VAL_ 1056 UIS_dmCenterPowerState 1 "ON" 0 "OFF" ;
VAL_ 1056 UIS_dmCenterOsdDisplayedState 1 "SHOWING" 0 "HIDDEN" ;
VAL_ 1056 UIS_dmCenterOsdDayNightState 1 "DAY" 0 "NIGHT" ;
VAL_ 1056 UIS_dmCenterModeSettingStatus 1 "PASSED" 0 "FAILED" ;
VAL_ 1056 UIS_dmCenterMOsdExactCrcCheck 2 "PASS" 1 "EXPECT_MATCH_FAIL" 0 "EXPECT_MISMATCH_FAIL" ;
VAL_ 1056 UIS_dmCenterLinkCheckOk 1 "PASSED" 0 "FAILED" ;
VAL_ 1056 UIS_dmCenterBacklightPowerLevel 2 "HIGH_POWER" 1 "LOW_POWER" 0 "OFF" ;
VAL_ 1056 UIS_dmCenterBacklightDevExists 1 "PASSED" 0 "FAILED" ;
VAL_ 1056 UIS_dmCenterAsilResumeFlag 4 "ACI_ERROR_RESET" 3 "SOFTWARE_RESET" 2 "REBOOT_RESET" 1 "WATCHDOG_RESET" 0 "GLOBAL_RESET" ;
VAL_ 1056 UIS_dmCenterAsilFirmwareStatus 3 "NORMAL_RUN" 2 "CALIBRATION_DONE" 1 "CALIBRATION" 0 "INITIAL_STAGE" ;
VAL_ 1056 UIS_dmCenterAsilCalibrationSync 1 "IN_SYNC" 0 "OUT_OF_SYNC" ;
VAL_ 1056 UIS_dashcamStorageState 8 "RECENT_BUFFER_DURATION_REDUCED" 7 "SLOW" 6 "READ_ONLY" 5 "FULL" 4 "GETTING_FULL" 3 "ERROR" 2 "READY" 1 "REMOVED" 0 "INVALID" ;
VAL_ 1056 UIS_dashcamState 7 "STREAMING" 6 "SAVING" 5 "PAUSED" 4 "RECORDING" 3 "STOPPED" 2 "ERROR" 1 "TERMINATED" 0 "INVALID" ;
VAL_ 1056 UIS_dasAutonomyControlMessageMia 1 "TRUE" 0 "FALSE" ;
VAL_ 1056 UIS_compositorFrameMonitorState 6 "DISCONNECTED" 5 "OK" 4 "STALLED" 3 "STALLING" 2 "CORRUPT_TIMECODE" 1 "UNKNOWN_FAILURE" 0 "UNKNOWN" ;
VAL_ 1056 UIS_clusterDisplayState 9 "ENTERTAINMENT" 8 "DOG" 7 "SENTRY" 6 "LOCK" 5 "CHARGING" 4 "DRIVING" 3 "ON" 2 "ACCESSORY" 1 "DIM" 0 "OFF" ;
VAL_ 1056 UIS_chargeOnSolarNoChargeReason 3 "ALTERNATIVE_VEHICLE_CHARGE_PRIORITY" 2 "GRID_EXPORT_PRIORITY" 1 "POWERWALL_CHRAGE_PRIORITY" 0 "INSUFFICIENT_SOLAR" ;
VAL_ 1056 UIS_centerDisplayState 9 "ENTERTAINMENT" 8 "DOG" 7 "SENTRY" 6 "LOCK" 5 "CHARGING" 4 "DRIVING" 3 "ON" 2 "ACCESSORY" 1 "DIM" 0 "OFF" ;
VAL_ 1056 UIS_centerDisplayEvent 21 "CPD_TRIGGERED" 20 "CAR_LOCKED" 19 "ENTERTAINMENT_OFF" 18 "ALL_STATES_EXCEPT_ENTERTAINMENT_TURNED_ON" 17 "IC_HAZARDS_OFF_DOOR_CLOSED_NO_OCCUPANTS" 16 "IC_HAZARDS_ON" 15 "ALL_DOORS_CLOSED_NO_OCCUPANTS_CHARGE_ACTIVE" 14 "TIMEOUT" 13 "DOOR_HANDLE_PULLED" 12 "ALL_STATES_EXCEPT_SENTRY" 11 "SENTRY_PANIC_ENDED" 10 "POWER_OFF_REQUEST" 9 "DRIVE_RAIL_OFF_NO_DRIVER_PRESENT" 8 "DRIVE_RAIL_OFF_DOOR_OPEN" 7 "DRIVE_RAIL_OFF_DRIVE_PRESENT" 6 "POWER_ON_REQUEST" 5 "DOOR_OPENED" 4 "ALL_STATES_EXCEPT_ENTERTAINMENT_DRIVE_RAIL_TURNED_ON" 3 "ALL_DOORS_CLOSED_NO_OCCUPANTS" 2 "PASSED_SPEED_THRESHOLD" 1 "SHIFTED_P_TO_N" 0 "OTHER" ;
VAL_ 1056 UIS_cellularLinkManagerState 16 "INVALID" 15 "RUNNING" 14 "DISCONNECTING" 13 "ROAMINGDISALLOWED" 12 "ENTERINGAIRPLANEMODE" 11 "CHECKING" 10 "RETRYING" 9 "CONFIGURING" 8 "CONNECTING" 7 "OFONOMODEMRELOADING" 6 "SEARCHING" 5 "CONFIGURINGAPN" 4 "QUERYDIAGNOSTIC" 3 "STARTING" 2 "UPDATING" 1 "RESETTING" 0 "RECOVERING" ;
VAL_ 1056 UIS_cellularConnectivityStatus 1 "CONNECTED" 0 "DISCONNECTED" ;
VAL_ 1056 UIS_carAssistState 5 "GROK" 4 "DICTATION" 3 "COMMAND" 2 "ERROR" 1 "IDLE" 0 "DISABLED" ;
VAL_ 1056 UIS_carAssistMicMuted 1 "TRUE" 0 "FALSE" ;
VAL_ 1056 UIS_carAssistErrorCode 17 "CLIENT_LOGGED_OUT_TOKEN_EXPIRED" 16 "CLIENT_PROVIDER_RATE_LIMTED" 15 "CLIENT_PROVIDER_AT_CAPACITY" 14 "CLIENT_ANON_USAGE_LIMITED" 13 "CLIENT_PREM_CONN" 12 "CLIENT_SPEECH" 11 "CLIENT_REMOTE" 10 "CLIENT_DBUS" 9 "CLIENT_DISCONNECTED" 8 "CLIENT_CONNECTIVITY" 7 "CLIENT_AUDIO" 6 "CLIENT_ERROR" 5 "COMMAND_NOT_IMPLEMENTED" 4 "COMMAND_NOT_AVAILABLE" 3 "COMMAND_NOT_UNDERSTOOD" 2 "REMOTE_ERROR" 1 "REMOTE_UNKNOWN" 0 "NONE" ;
VAL_ 1056 UIS_cameraSelectableRenderState 2 "ACTIVE" 1 "REQUESTED" 0 "INACTIVE" ;
VAL_ 1056 UIS_cameraSelectablePipeline 4 "PLAYING" 3 "PAUSED" 2 "READY" 1 "NULL" 0 "SLEEP" ;
VAL_ 1056 UIS_cameraSelectablePacketState 2 "RECEIVING" 1 "MISSING" 0 "CHECKING" ;
VAL_ 1056 UIS_cameraRearViewStreamMissing 1 "MISSING" 0 "ACTIVE" ;
VAL_ 1056 UIS_cameraRearViewRenderState 2 "ACTIVE" 1 "REQUESTED" 0 "INACTIVE" ;
VAL_ 1056 UIS_cameraRearViewPopup 1 "OPEN" 0 "CLOSED" ;
VAL_ 1056 UIS_cameraRearViewPipeline 4 "PLAYING" 3 "PAUSED" 2 "READY" 1 "NULL" 0 "SLEEP" ;
VAL_ 1056 UIS_cameraRearViewPacketState 2 "RECEIVING" 1 "MISSING" 0 "CHECKING" ;
VAL_ 1056 UIS_cameraRRepeaterStreamMissing 1 "MISSING" 0 "ACTIVE" ;
VAL_ 1056 UIS_cameraRRepeaterRenderState 2 "ACTIVE" 1 "REQUESTED" 0 "INACTIVE" ;
VAL_ 1056 UIS_cameraRRepeaterPopup 1 "OPEN" 0 "CLOSED" ;
VAL_ 1056 UIS_cameraRRepeaterPipeline 4 "PLAYING" 3 "PAUSED" 2 "READY" 1 "NULL" 0 "SLEEP" ;
VAL_ 1056 UIS_cameraRRepeaterPacketState 2 "RECEIVING" 1 "MISSING" 0 "CHECKING" ;
VAL_ 1056 UIS_cameraRDownwardRenderState 2 "ACTIVE" 1 "REQUESTED" 0 "INACTIVE" ;
VAL_ 1056 UIS_cameraRDownwardPipeline 4 "PLAYING" 3 "PAUSED" 2 "READY" 1 "NULL" 0 "SLEEP" ;
VAL_ 1056 UIS_cameraRDownwardPacketState 2 "RECEIVING" 1 "MISSING" 0 "CHECKING" ;
VAL_ 1056 UIS_cameraLRepeaterStreamMissing 1 "MISSING" 0 "ACTIVE" ;
VAL_ 1056 UIS_cameraLRepeaterRenderState 2 "ACTIVE" 1 "REQUESTED" 0 "INACTIVE" ;
VAL_ 1056 UIS_cameraLRepeaterPopup 1 "OPEN" 0 "CLOSED" ;
VAL_ 1056 UIS_cameraLRepeaterPipeline 4 "PLAYING" 3 "PAUSED" 2 "READY" 1 "NULL" 0 "SLEEP" ;
VAL_ 1056 UIS_cameraLRepeaterPacketState 2 "RECEIVING" 1 "MISSING" 0 "CHECKING" ;
VAL_ 1056 UIS_cameraLDownwardRenderState 2 "ACTIVE" 1 "REQUESTED" 0 "INACTIVE" ;
VAL_ 1056 UIS_cameraLDownwardPipeline 4 "PLAYING" 3 "PAUSED" 2 "READY" 1 "NULL" 0 "SLEEP" ;
VAL_ 1056 UIS_cameraLDownwardPacketState 2 "RECEIVING" 1 "MISSING" 0 "CHECKING" ;
VAL_ 1056 UIS_cameraFrontStreamMissing 1 "MISSING" 0 "ACTIVE" ;
VAL_ 1056 UIS_cameraFrontRenderState 2 "ACTIVE" 1 "REQUESTED" 0 "INACTIVE" ;
VAL_ 1056 UIS_cameraFrontPopup 1 "OPEN" 0 "CLOSED" ;
VAL_ 1056 UIS_cameraFrontPipeline 4 "PLAYING" 3 "PAUSED" 2 "READY" 1 "NULL" 0 "SLEEP" ;
VAL_ 1056 UIS_cameraFrontPacketState 2 "RECEIVING" 1 "MISSING" 0 "CHECKING" ;
VAL_ 1056 UIS_cameraBackupStreamQuality 4 "EXCELLENT" 3 "GOOD" 2 "FAIR" 1 "POOR" 0 "UNKNOWN" ;
VAL_ 1056 UIS_cameraBackupStreamMissing 1 "MISSING" 0 "ACTIVE" ;
VAL_ 1056 UIS_cameraBackupRenderState 2 "ACTIVE" 1 "REQUESTED" 0 "INACTIVE" ;
VAL_ 1056 UIS_cameraBackupPopup 1 "OPEN" 0 "CLOSED" ;
VAL_ 1056 UIS_cameraBackupPipeline 4 "PLAYING" 3 "PAUSED" 2 "READY" 1 "NULL" 0 "SLEEP" ;
VAL_ 1056 UIS_cameraBackupPacketState 2 "RECEIVING" 1 "MISSING" 0 "CHECKING" ;
VAL_ 1056 UIS_pmSuspendHookIndex 99 "PM_SUSPEND_END" 98 "Kernel" 95 "Timesync" 90 "LED" 80 "Button" 70 "NVME" 69 "Memory" 61 "Cameras" 50 "Modem" 40 "Bluetooth" 30 "Wifi" 25 "Hermes" 20 "USB" 10 "Audio" 9 "BluetoothRear" 5 "DGPU" 2 "Post" 1 "Steam" 0 "PM_SUSPEND_START" ;
VAL_ 1056 UIS_bluetoothState 11 "CONNECTED" 10 "CONN_MAP" 9 "CONN_PBAP" 8 "CONN_A2DP" 7 "CONN_HFP" 6 "CONN_SPP" 5 "CONN_ACL" 4 "CONNECTING" 3 "PAIRING" 2 "DISCOVERY_STOP" 1 "DISCOVERY_START" 0 "DISCONNECTED" ;
VAL_ 1056 UIS_bluetoothStackState 4 "ON_BLUEZ" 3 "ON_SYNERGY" 2 "ON_LGIT" 1 "ON" 0 "OFF" ;
VAL_ 1056 UIS_bluetoothStackRearState 4 "ON_BLUEZ" 3 "ON_SYNERGY" 2 "ON_LGIT" 1 "ON" 0 "OFF" ;
VAL_ 1056 UIS_bluetoothPairResult 23 "HID_PAIRED" 22 "HID_MAX_NR_OF_CONNS" 21 "HID_PAGE_TIMEOUT" 20 "HID_OETC_USER" 19 "HID_REJ_BY_REMOTE_NO_RES" 18 "HID_LMP_RESPONSE_TIMEOUT" 17 "HID_AUTH_FAILURE" 16 "HID_KEY_MISSING" 15 "HID_NO_RESPONSE" 14 "HID_ALREADY_REQUESTED_BY_REMOTE" 13 "HID_UNKNOWN" 12 "HID_UNPAIRED" 11 "PAIRED" 10 "MAX_NR_OF_CONNS" 9 "PAGE_TIMEOUT" 8 "OETC_USER" 7 "REJ_BY_REMOTE_NO_RES" 6 "LMP_RESPONSE_TIMEOUT" 5 "AUTH_FAILURE" 4 "KEY_MISSING" 3 "NO_RESPONSE" 2 "ALREADY_REQUESTED_BY_REMOTE" 1 "UNKNOWN" 0 "UNPAIRED" ;
VAL_ 1056 UIS_bluetoothConnectionState 77 "HID_ERROR_UNKNOWN" 76 "HID_ERROR_ANTENNA_DISCONNECTED" 75 "HID_CONNECTED" 74 "HID_CONNECT_CANCELLED" 73 "HID_CONNECT_PROFILE_UNAVAILABLE" 72 "HID_CONNECT_INVALID_ARGUMENT" 71 "HID_CONNECT_ADAPTER_OFF" 70 "HID_CONNECT_NOT_SUPPORTED" 69 "HID_CONNECT_ALREADY_CONN" 68 "HID_CONNECT_DEVICE_NOT_FOUND_NO_RESOURCES" 67 "HID_CONNECT_DEVICE_NOT_FOUND_PAGE_TIMEOUT" 66 "HID_CONNECT_DEVICE_NOT_FOUND" 65 "HID_CONNECT_FAILED_REMOTE_TERMINATED" 64 "HID_CONNECT_FAILED_NO_RESOURCES" 63 "HID_CONNECT_FAILED_CONNECTION_TIMEOUT" 62 "HID_CONNECT_FAILED" 61 "HID_CONNECT_SDP_FAILURE" 60 "HID_CONNECT_PIN_MISSING" 59 "HID_CONNECT_PAGE_TIMEOUT" 58 "HID_CONNECT_REJ_BY_REMOTE_NO_RES" 57 "HID_CONNECT_MAX_NR_OF_CONNS" 56 "HID_CONNECT_CONTROLLER_BUSY" 55 "HID_CONNECT_CONN_TIMEOUT" 54 "HID_CONNECT_MAX_NR_OF_ACL" 53 "HID_CONNECT_LMP_RESPONSE_TIMEOUT" 52 "HID_CONNECT_HOST_TIMEOUT" 51 "HID_CONNECT_UNKNOWN_FAILURE" 50 "HID_DISCONNECT_UNKNOWN" 49 "HID_DISCONNECT_OETC_POWERING_OFF" 48 "HID_DISCONNECT_OETC_LOW_RESOURCE" 47 "HID_DISCONNECT_REJ_BY_REMOTE_SEC" 46 "HID_DISCONNECT_AUTH_FAIL" 45 "HID_DISCONNECT_LMP_RESPONSE_TIMEOUT" 44 "HID_DISCONNECT_OETC_USER" 43 "HID_DISCONNECT_CONN_TIMEOUT" 42 "HID_DISCONNECT_CONN_TERM_LOCAL_HOST" 41 "HID_DISCONNECT_LINKLOSS" 40 "HID_DISCONNECT_FROM_REMOTE" 39 "HID_DISCONNECTED" 38 "ERROR_UNKNOWN" 37 "ERROR_ANTENNA_DISCONNECTED" 36 "CONNECTED" 35 "CONNECT_CANCELLED" 34 "CONNECT_PROFILE_UNAVAILABLE" 33 "CONNECT_INVALID_ARGUMENT" 32 "CONNECT_ADAPTER_OFF" 31 "CONNECT_NOT_SUPPORTED" 30 "CONNECT_ALREADY_CONN" 29 "CONNECT_DEVICE_NOT_FOUND_NO_RESOURCES" 28 "CONNECT_DEVICE_NOT_FOUND_PAGE_TIMEOUT" 27 "CONNECT_DEVICE_NOT_FOUND" 26 "CONNECT_FAILED_REMOTE_TERMINATED" 25 "CONNECT_FAILED_NO_RESOURCES" 24 "CONNECT_FAILED_CONNECTION_TIMEOUT" 23 "CONNECT_FAILED" 22 "CONNECT_SDP_FAILURE" 21 "CONNECT_PIN_MISSING" 20 "CONNECT_PAGE_TIMEOUT" 19 "CONNECT_REJ_BY_REMOTE_NO_RES" 18 "CONNECT_MAX_NR_OF_CONNS" 17 "CONNECT_CONTROLLER_BUSY" 16 "CONNECT_CONN_TIMEOUT" 15 "CONNECT_MAX_NR_OF_ACL" 14 "CONNECT_LMP_RESPONSE_TIMEOUT" 13 "CONNECT_HOST_TIMEOUT" 12 "CONNECT_UNKNOWN_FAILURE" 11 "DISCONNECT_UNKNOWN" 10 "DISCONNECT_OETC_POWERING_OFF" 9 "DISCONNECT_OETC_LOW_RESOURCE" 8 "DISCONNECT_REJ_BY_REMOTE_SEC" 7 "DISCONNECT_AUTH_FAIL" 6 "DISCONNECT_LMP_RESPONSE_TIMEOUT" 5 "DISCONNECT_OETC_USER" 4 "DISCONNECT_CONN_TIMEOUT" 3 "DISCONNECT_CONN_TERM_LOCAL_HOST" 2 "DISCONNECT_LINKLOSS" 1 "DISCONNECT_FROM_REMOTE" 0 "DISCONNECTED" ;
VAL_ 1056 UIS_bluetoothAutoConnectionState 3 "MANUAL_CONNECT_REQUESTED" 2 "GAVE_UP" 1 "CONNECTED" 0 "IDLE" ;
VAL_ 1056 UIS_audioType 4 "BASE_WITH_PREMIUM200" 3 "PREMIUM" 2 "BASE" 1 "NO_A2B" 0 "INVALID" ;
VAL_ 1056 UIS_audioState 7 "SLEEPING" 6 "AUDIO_NOT_PUMPING" 5 "A2B_REDISCOVERY" 4 "HFP_PUMPING" 3 "AUDIO_PUMPING" 2 "UNINITIALIZING" 1 "INITIALIZING" 0 "TERMINATED" ;
VAL_ 1056 UIS_audioSource 5 "NONE" 4 "PHONE_RX" 3 "BLUETOOTH" 2 "MICROPHONE" 1 "TUNER" 0 "MEDIA" ;
VAL_ 1056 UIS_audioMediaPlaying 39 "SODA_MUSIC" 38 "CARAOKE" 37 "KUGOU" 36 "YOUTUBE_MUSIC" 35 "YUNTING" 34 "AMAZON_MUSIC" 33 "AUDIBLE" 32 "APPLE_PODCASTS" 31 "APPLE_MUSIC" 30 "MINI_PROGRAMS" 29 "SEARCH" 28 "HOME_APPS" 27 "RECENTS_FAVORITES" 26 "TOYBOX" 25 "TUTORIAL" 24 "THEATER" 23 "BROWSER" 22 "GAME" 21 "NET_EASE_MUSIC" 20 "ONLINE_RADIO" 19 "XIMALAYA" 18 "QQ_MUSIC2" 17 "QQ_MUSIC1" 16 "TIDAL" 15 "SIRIUS_XM" 14 "STINGRAY" 13 "TUNE_IN" 12 "EU_RADIO" 11 "US_RADIO" 10 "SPOTIFY" 9 "SLACKER" 8 "BLUETOOTH" 7 "USB" 6 "DAB" 5 "XM" 4 "FM" 3 "AM" 2 "UNKNOWN" 1 "DEPRECATED" 0 "NONE" ;
VAL_ 1056 UIS_audioMediaBrowsing 39 "SODA_MUSIC" 38 "CARAOKE" 37 "KUGOU" 36 "YOUTUBE_MUSIC" 35 "YUNTING" 34 "AMAZON_MUSIC" 33 "AUDIBLE" 32 "APPLE_PODCASTS" 31 "APPLE_MUSIC" 30 "MINI_PROGRAMS" 29 "SEARCH" 28 "HOME_APPS" 27 "RECENTS_FAVORITES" 26 "TOYBOX" 25 "TUTORIAL" 24 "THEATER" 23 "BROWSER" 22 "GAME" 21 "NET_EASE_MUSIC" 20 "ONLINE_RADIO" 19 "XIMALAYA" 18 "QQ_MUSIC2" 17 "QQ_MUSIC1" 16 "TIDAL" 15 "SIRIUS_XM" 14 "STINGRAY" 13 "TUNE_IN" 12 "EU_RADIO" 11 "US_RADIO" 10 "SPOTIFY" 9 "SLACKER" 8 "BLUETOOTH" 7 "USB" 6 "DAB" 5 "XM" 4 "FM" 3 "AM" 2 "UNKNOWN" 1 "DEPRECATED" 0 "NONE" ;
VAL_ 1056 UIS_activeAppView 67 "SODA_MUSIC" 66 "HICAR" 65 "CARAOKE_WEB" 64 "KUGOU" 63 "YOUTUBE_MUSIC" 62 "YUNTING" 61 "ONLINE_RADIO" 60 "AMAZON_MUSIC" 59 "AUDIBLE" 58 "APPLE_PODCASTS" 57 "ONBOARDING_MANUAL" 56 "APPLE_MUSIC" 55 "ZOOM" 54 "MINI_PROGRAMS" 53 "CADMIUM" 52 "MESSAGES" 51 "NAV_MEDIA" 50 "BACKGAMMON" 49 "SKETCH_PAD" 48 "ARCADE" 47 "XIMALAYA" 46 "BLUETOOTH" 45 "CHESS" 44 "NETEASE" 43 "OWNERS_MANUAL" 42 "QQMUSIC" 41 "RELEASE_NOTES" 40 "SONIC" 39 "USB" 38 "THEATER" 37 "TIDAL" 36 "TUNEIN" 35 "CARAOKE" 34 "STREAMING" 33 "RADIO" 32 "SPOTIFY" 31 "CAMERA" 30 "CHARGE" 29 "MEDIA" 28 "ENTERTAINMENT" 27 "WEB" 26 "CALENDAR" 25 "TOYBOX" 24 "PHONE" 23 "ENERGY" 22 "TUTORIAL" 21 "CERULEAN" 20 "TOPAZ" 19 "DASHCAM" 18 "CARBONADO" 17 "THEATERVIEW" 16 "MAMBU" 15 "COBALT" 14 "TESLATARI" 13 "SERVICE_APPS" 12 "LIME" 11 "TEARDROP" 10 "NAV" 9 "PURPLE" 8 "CALICO" 7 "CARWASH" 6 "2048" 5 "CONTROLS" 4 "COLORIZER" 3 "XM" 2 "DEVELOPMENT" 1 "NONE" 0 "UNKNOWN" ;
VAL_ 979 UI_airbagCutoffSwState 2 "SNA" 1 "PASSENGER_AIRBAG_OFF" 0 "PASSENGER_AIRBAG_ON" ;
VAL_ 979 UI_warningIndicatorStatus 3 "SNA" 1 "WARNING_LAMP_ON" 0 "WARNING_LAMP_OFF" ;
